VERSION "HNNBNNNYNNNNNNNNNNNNNNNNNNNNNNNNNNNNNNNNNN/4/%%%/4/'%**4NNN///"

NS_ :

BS_:

BU_: AAG BCM1 BCM2 ELV Gateway HDSG IEZS MFG MSBBR SAD SAD2 Schwerpanzer_Zusatz SitzMem_BFS SitzMem_FS SitzMem_HBFS SitzMem_HFS SitzMem_SR3 SpoilerSG TSG_BFS TSG_FS VSG VTS DK_Dummy

BO_ 975 TSG_HBFS_01: 8 TSG_BFS
 SG_ HBFS_Tuer_geoeffnet : 0|1@1+ (1,0) [0|1] ""  BCM2,Gateway,IEZS,MFG,SitzMem_FS,SitzMem_HBFS,SitzMem_SR3,VTS
 SG_ HBFS_verriegelt : 1|1@1+ (1,0) [0|1] ""  BCM2,Gateway,MFG,SitzMem_SR3,VTS
 SG_ HBFS_gesafet : 2|1@1+ (1,0) [0|1] ""  BCM2,Gateway,MFG,TSG_FS,VTS
 SG_ HBFS_Heckrollotaster_betaetigt : 3|1@1+ (1,0) [0|1] ""  BCM2,Gateway
 SG_ HBFS_Tuerschloss_defekt : 4|1@1+ (1,0) [0|1] ""  BCM2,Gateway
 SG_ HBFS_Unlock_Taster : 5|1@1+ (1,0) [0|1] ""  BCM2,Gateway,MFG
 SG_ HBFS_Lock_Taster : 6|1@1+ (1,0) [0|1] ""  BCM2,Gateway,MFG
 SG_ HBFS_Sperrklinke : 7|1@1+ (1,0) [0|1] ""  BCM2,Gateway,MFG
 SG_ HBFS_TAG_betaetigt : 8|1@1+ (1,0) [0|1] ""  Gateway,MFG,VTS
 SG_ HBFS_TIG_betaetigt : 9|1@1+ (1,0) [0|1] ""  BCM1,BCM2,Gateway,MFG
 SG_ HBFS_FH_S_HFS_AutoHoch : 10|1@1+ (1,0) [0|1] ""  Gateway,TSG_FS
 SG_ HBFS_FH_S_HFS_AutoTief : 11|1@1+ (1,0) [0|1] ""  Gateway,TSG_FS
 SG_ HBFS_FH_S_HFS_ManHoch : 12|1@1+ (1,0) [0|1] ""  Gateway,TSG_FS
 SG_ HBFS_FH_S_HFS_ManTief : 13|1@1+ (1,0) [0|1] ""  Gateway,TSG_FS
 SG_ HBFS_Tuer_Status : 14|2@1+ (1,0) [0|3] ""  Gateway,SitzMem_HBFS,TSG_FS
 SG_ HBFS_SAD_Schalter : 16|4@1+ (1,0) [0|15] ""  SAD2,BCM2,Gateway,SAD
 SG_ HBFS_FH_S_ManHoch : 20|1@1+ (1,0) [0|1] ""  BCM2,Gateway,MFG
 SG_ HBFS_FH_S_AutoHoch : 21|1@1+ (1,0) [0|1] ""  BCM2,Gateway,MFG
 SG_ HBFS_FH_S_ManTief : 22|1@1+ (1,0) [0|1] ""  BCM2,Gateway,MFG
 SG_ HBFS_FH_S_AutoTief : 23|1@1+ (1,0) [0|1] ""  BCM2,Gateway,MFG
 SG_ HBFS_FH_Oeffnung : 24|8@1+ (0.5,0) [0|100] "Unit_PerCent"  BCM1,BCM2,Gateway,MFG,SAD,SAD2,VSG,VTS
 SG_ HBFS_FH_Bew_hoch : 32|1@1+ (1,0) [0|1] ""  Gateway,MFG,TSG_FS,VSG
 SG_ HBFS_FH_Bew_tief : 33|1@1+ (1,0) [0|1] ""  Gateway,MFG,TSG_FS
 SG_ HBFS_FH_Fang : 34|1@1+ (1,0) [0|1] ""  Gateway,MFG
 SG_ HBFS_FH_Block : 35|1@1+ (1,0) [0|1] ""  Gateway,MFG
 SG_ HBFS_FH_Thermo : 36|1@1+ (1,0) [0|1] ""  BCM2,Gateway,MFG
 SG_ HBFS_UEKB_aktiviert : 37|1@1+ (1,0) [0|1] ""  BCM2,Gateway,MFG
 SG_ HBFS_Tuerschloss_verrieg_nicht : 38|1@1+ (1,0) [0|1] ""  Gateway
 SG_ HBFS_FH_normiert : 39|1@1+ (1,0) [0|1] ""  BCM2,Gateway,MFG,TSG_FS,VSG,VTS
 SG_ ASW_Warnung_aktiv_HBFS : 40|1@1+ (1,0) [0|1] ""  BCM1,Gateway
 SG_ HBFS_Zuziehhilfe_aktiv : 41|1@1+ (1,0) [0|1] ""  Gateway,MFG
 SG_ HBFS_Seitenrollo_hoch : 42|1@1+ (1,0) [0|1] ""  Gateway,MFG
 SG_ HBFS_Seitenrollo_tief : 43|1@1+ (1,0) [0|1] ""  Gateway,MFG
 SG_ HBFS_Status_KiSi : 44|1@1+ (1,0) [0|1] ""  Gateway,MFG,TSG_FS
 SG_ SSR_HBFS_Pos_Unten : 45|1@1+ (1,0) [0|1] ""  Gateway,TSG_FS
 SG_ HBFS_Oben_Block_erw : 46|1@1+ (1,0) [0|1] ""  Gateway,MFG,TSG_FS
 SG_ HBFS_Unten_Block_erw : 47|1@1+ (1,0) [0|1] ""  Gateway,MFG,TSG_FS
 SG_ MTHBFS_M_Taste : 48|1@1+ (1,0) [0|1] ""  Gateway,SitzMem_FS,SitzMem_HBFS
 SG_ MTHBFS_Pos1 : 49|1@1+ (1,0) [0|1] ""  Gateway,SitzMem_FS
 SG_ MTHBFS_Pos2 : 50|1@1+ (1,0) [0|1] ""  Gateway,SitzMem_FS,SitzMem_HBFS
 SG_ MTHBFS_Pos3 : 51|1@1+ (1,0) [0|1] ""  Gateway,SitzMem_FS,SitzMem_HBFS
 SG_ HBFS_MRollo_Schalter : 52|3@1+ (1,0) [0|7] ""  SAD2,BCM2,Gateway,SAD
 SG_ HBFS_Lock_Taster_inv : 55|1@1+ (1,0) [0|1] ""  BCM2,Gateway
 SG_ HBFS_Status_KiSi_inv : 56|1@1+ (1,0) [0|1] ""  Gateway,TSG_FS

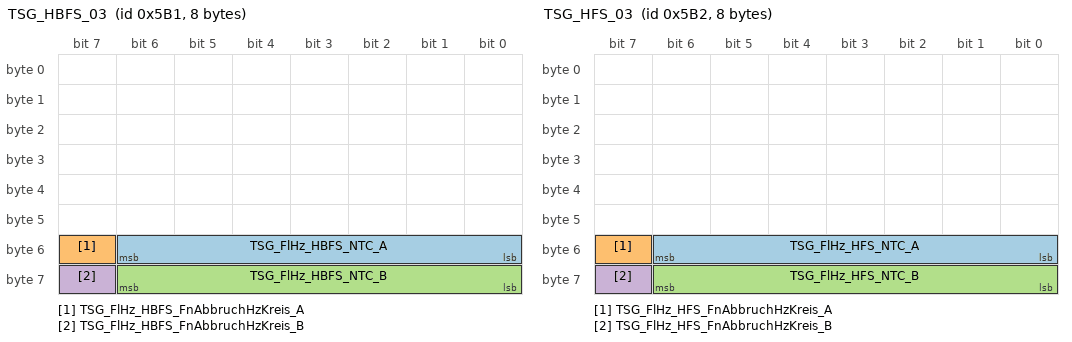
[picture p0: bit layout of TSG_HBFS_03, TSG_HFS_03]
BO_ 1457 TSG_HBFS_03: 8 TSG_BFS
 SG_ TSG_FlHz_HBFS_NTC_A : 48|7@1+ (1,-40) [-40|80] "Unit_DegreCelsi"  BCM1
 SG_ TSG_FlHz_HBFS_FnAbbruchHzKreis_A : 55|1@1+ (1,0) [0|1] ""  BCM1
 SG_ TSG_FlHz_HBFS_NTC_B : 56|7@1+ (1,-40) [-40|80] "Unit_DegreCelsi"  BCM1
 SG_ TSG_FlHz_HBFS_FnAbbruchHzKreis_B : 63|1@1+ (1,0) [0|1] ""  BCM1

BO_ 974 TSG_HFS_01: 8 TSG_FS
 SG_ HFS_Tuer_geoeffnet : 0|1@1+ (1,0) [0|1] ""  BCM2,Gateway,IEZS,MFG,SitzMem_FS,SitzMem_HFS,SitzMem_SR3,VTS
 SG_ HFS_verriegelt : 1|1@1+ (1,0) [0|1] ""  BCM2,Gateway,MFG,SitzMem_SR3,VTS
 SG_ HFS_gesafet : 2|1@1+ (1,0) [0|1] ""  BCM2,Gateway,MFG,TSG_BFS,VTS
 SG_ HFS_Heckrollotaster_betaetigt : 3|1@1+ (1,0) [0|1] ""  BCM2,Gateway
 SG_ HFS_Tuerschloss_defekt : 4|1@1+ (1,0) [0|1] ""  BCM2,Gateway
 SG_ HFS_Unlock_Taster : 5|1@1+ (1,0) [0|1] ""  BCM2,Gateway,MFG
 SG_ HFS_Lock_Taster : 6|1@1+ (1,0) [0|1] ""  BCM2,Gateway,MFG
 SG_ HFS_Sperrklinke : 7|1@1+ (1,0) [0|1] ""  BCM2,Gateway,MFG
 SG_ HFS_TAG_betaetigt : 8|1@1+ (1,0) [0|1] ""  Gateway,MFG,VTS
 SG_ HFS_TIG_betaetigt : 9|1@1+ (1,0) [0|1] ""  BCM1,BCM2,Gateway,MFG
 SG_ HFS_FH_S_HBFS_AutoHoch : 10|1@1+ (1,0) [0|1] ""  Gateway,MFG,TSG_BFS
 SG_ HFS_FH_S_HBFS_AutoTief : 11|1@1+ (1,0) [0|1] ""  Gateway,MFG,TSG_BFS
 SG_ HFS_FH_S_HBFS_ManHoch : 12|1@1+ (1,0) [0|1] ""  Gateway,MFG,TSG_BFS
 SG_ HFS_FH_S_HBFS_ManTief : 13|1@1+ (1,0) [0|1] ""  Gateway,MFG,TSG_BFS
 SG_ HFS_Tuer_Status : 14|2@1+ (1,0) [0|3] ""  Gateway
 SG_ HFS_SAD_Schalter : 16|4@1+ (1,0) [0|15] ""  SAD2,BCM2,Gateway,SAD
 SG_ HFS_FH_S_ManHoch : 20|1@1+ (1,0) [0|1] ""  BCM2,Gateway
 SG_ HFS_FH_S_AutoHoch : 21|1@1+ (1,0) [0|1] ""  BCM2,Gateway
 SG_ HFS_FH_S_ManTief : 22|1@1+ (1,0) [0|1] ""  BCM2,Gateway
 SG_ HFS_FH_S_AutoTief : 23|1@1+ (1,0) [0|1] ""  BCM2,Gateway
 SG_ HFS_FH_Oeffnung : 24|8@1+ (0.5,0) [0|100] "Unit_PerCent"  BCM1,BCM2,Gateway,MFG,SAD,SAD2,VSG,VTS
 SG_ HFS_FH_Bew_hoch : 32|1@1+ (1,0) [0|1] ""  Gateway,MFG,TSG_BFS,VSG
 SG_ HFS_FH_Bew_tief : 33|1@1+ (1,0) [0|1] ""  Gateway,MFG,TSG_BFS
 SG_ HFS_FH_Fang : 34|1@1+ (1,0) [0|1] ""  Gateway,MFG
 SG_ HFS_FH_Block : 35|1@1+ (1,0) [0|1] ""  Gateway,MFG
 SG_ HFS_FH_Thermo : 36|1@1+ (1,0) [0|1] ""  BCM2,Gateway,MFG
 SG_ HFS_UEKB_aktiviert : 37|1@1+ (1,0) [0|1] ""  BCM2,Gateway,MFG
 SG_ HFS_Tuerschloss_verrieg_nicht : 38|1@1+ (1,0) [0|1] ""  Gateway
 SG_ HFS_FH_normiert : 39|1@1+ (1,0) [0|1] ""  BCM2,Gateway,MFG,VSG,VTS
 SG_ ASW_Warnung_aktiv_HFS : 40|1@1+ (1,0) [0|1] ""  BCM1,Gateway
 SG_ HFS_Zuziehhilfe_aktiv : 41|1@1+ (1,0) [0|1] ""  Gateway,MFG
 SG_ HFS_Seitenrollo_hoch : 42|1@1+ (1,0) [0|1] ""  Gateway,MFG
 SG_ HFS_Seitenrollo_tief : 43|1@1+ (1,0) [0|1] ""  Gateway,MFG
 SG_ HFS_Status_KiSi : 44|1@1+ (1,0) [0|1] ""  Gateway,MFG,TSG_BFS
 SG_ SSR_HFS_Pos_Unten : 45|1@1+ (1,0) [0|1] ""  Gateway,TSG_BFS
 SG_ HFS_Oben_Block_erw : 46|1@1+ (1,0) [0|1] ""  Gateway,MFG,TSG_BFS
 SG_ HFS_Unten_Block_erw : 47|1@1+ (1,0) [0|1] ""  Gateway,MFG,TSG_BFS
 SG_ MTHFS_M_Taste : 48|1@1+ (1,0) [0|1] ""  Gateway,SitzMem_FS,SitzMem_HFS
 SG_ MTHFS_Pos1 : 49|1@1+ (1,0) [0|1] ""  Gateway,SitzMem_FS,SitzMem_HFS
 SG_ MTHFS_Pos2 : 50|1@1+ (1,0) [0|1] ""  Gateway,SitzMem_FS,SitzMem_HFS
 SG_ MTHFS_Pos3 : 51|1@1+ (1,0) [0|1] ""  Gateway,SitzMem_FS,SitzMem_HFS
 SG_ HFS_MRollo_Schalter : 52|3@1+ (1,0) [0|7] ""  SAD2,BCM2,Gateway,SAD
 SG_ HFS_Lock_Taster_inv : 55|1@1+ (1,0) [0|1] ""  BCM2,Gateway

BO_ 1458 TSG_HFS_03: 8 TSG_FS
 SG_ TSG_FlHz_HFS_NTC_A : 48|7@1+ (1,-40) [-40|80] "Unit_DegreCelsi"  BCM1
 SG_ TSG_FlHz_HFS_FnAbbruchHzKreis_A : 55|1@1+ (1,0) [0|1] ""  BCM1
 SG_ TSG_FlHz_HFS_NTC_B : 56|7@1+ (1,-40) [-40|80] "Unit_DegreCelsi"  BCM1
 SG_ TSG_FlHz_HFS_FnAbbruchHzKreis_B : 63|1@1+ (1,0) [0|1] ""  BCM1

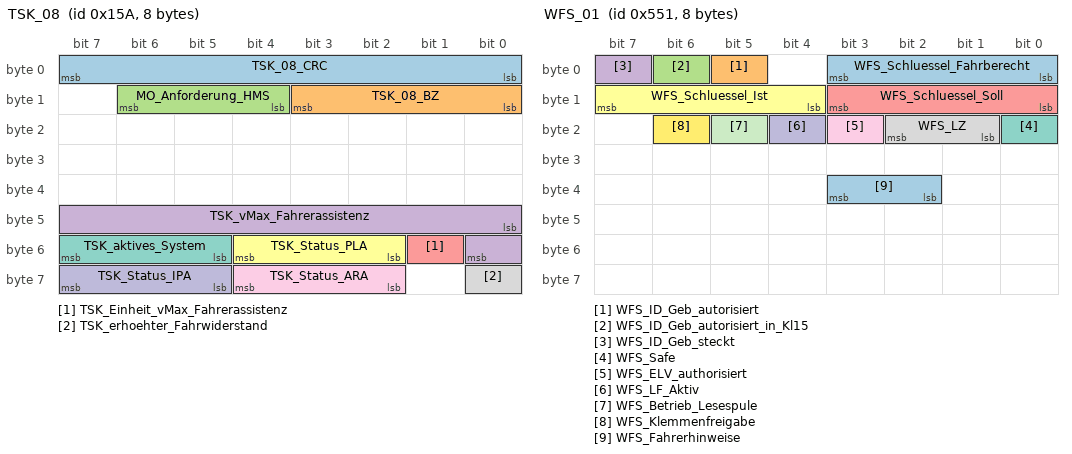
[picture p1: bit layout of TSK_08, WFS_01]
BO_ 346 TSK_08: 8 Gateway
 SG_ TSK_08_CRC : 0|8@1+ (1,0) [0|255] "" Vector__XXX
 SG_ TSK_08_BZ : 8|4@1+ (1,0) [0|15] "" Vector__XXX
 SG_ MO_Anforderung_HMS : 12|3@1+ (1,0) [0|7] "" Vector__XXX
 SG_ TSK_vMax_Fahrerassistenz : 40|9@1+ (1,0) [0|510] "" Vector__XXX
 SG_ TSK_Einheit_vMax_Fahrerassistenz : 49|1@1+ (1,0) [0|1] "" Vector__XXX
 SG_ TSK_Status_PLA : 50|3@1+ (1,0) [0|7] ""  BCM1
 SG_ TSK_aktives_System : 53|3@1+ (1,0) [0|7] ""  BCM1
 SG_ TSK_erhoehter_Fahrwiderstand : 56|1@1+ (1,0) [0|1] "" Vector__XXX
 SG_ TSK_Status_ARA : 58|3@1+ (1,0) [0|7] ""  BCM1
 SG_ TSK_Status_IPA : 61|3@1+ (1,0) [0|7] "" Vector__XXX

BO_ 995 Verdeck_01: 8 VSG
 SG_ VS_VD_zu_ver : 16|1@1+ (1,0) [0|1] ""  BCM1,BCM2,Gateway,SpoilerSG,TSG_BFS,TSG_FS
 SG_ VS_VD_entriegelt : 17|1@1+ (1,0) [0|1] ""  BCM2,Gateway,TSG_BFS,TSG_FS
 SG_ VS_VD_offen_ver : 18|1@1+ (1,0) [0|1] ""  BCM1,BCM2,Gateway,TSG_BFS,TSG_FS
 SG_ VS_VD_Zwischenposition : 19|1@1+ (1,0) [0|1] ""  BCM2,Gateway,TSG_BFS,TSG_FS
 SG_ VS_VD_Bew_auf : 20|1@1+ (1,0) [0|1] ""  Gateway,TSG_BFS,TSG_FS
 SG_ VS_VD_Bew_zu : 21|1@1+ (1,0) [0|1] ""  Gateway,TSG_BFS,TSG_FS
 SG_ VS_Verdeck_Anf : 22|1@1+ (1,0) [0|1] ""  AAG,BCM2,Gateway
 SG_ VS_Hardtop : 23|1@1+ (1,0) [0|1] ""  BCM1,Gateway,TSG_BFS,TSG_FS
 SG_ VS_VD_Fehler : 24|1@1+ (1,0) [0|1] ""  Gateway
 SG_ VS_Lampe_Blk : 25|1@1+ (1,0) [0|1] ""  Gateway
 SG_ VS_Buzzer : 26|1@1+ (1,0) [0|1] ""  Gateway
 SG_ VS_HD_sperren : 27|1@1+ (1,0) [0|1] ""  BCM2,Gateway
 SG_ VS_HHS_enable : 28|1@1+ (1,0) [0|1] ""  BCM2,Gateway
 SG_ ZFH_FS_AutoHoch : 32|1@1+ (1,0) [0|1] ""  Gateway,TSG_FS
 SG_ ZFH_FS_AutoTief : 33|1@1+ (1,0) [0|1] ""  Gateway,TSG_FS
 SG_ ZFH_FS_ManHoch : 34|1@1+ (1,0) [0|1] ""  Gateway,TSG_FS
 SG_ ZFH_FS_ManTief : 35|1@1+ (1,0) [0|1] ""  Gateway,TSG_FS
 SG_ ZFH_BFS_AutoHoch : 36|1@1+ (1,0) [0|1] ""  Gateway,TSG_BFS
 SG_ ZFH_BFS_AutoTief : 37|1@1+ (1,0) [0|1] ""  Gateway,TSG_BFS
 SG_ ZFH_BFS_ManHoch : 38|1@1+ (1,0) [0|1] ""  Gateway,TSG_BFS
 SG_ ZFH_BFS_ManTief : 39|1@1+ (1,0) [0|1] ""  Gateway,TSG_BFS
 SG_ ZFH_HFS_AutoHoch : 40|1@1+ (1,0) [0|1] ""  Gateway,TSG_FS
 SG_ ZFH_HFS_AutoTief : 41|1@1+ (1,0) [0|1] ""  Gateway,TSG_FS
 SG_ ZFH_HFS_ManHoch : 42|1@1+ (1,0) [0|1] ""  Gateway,TSG_FS
 SG_ ZFH_HFS_ManTief : 43|1@1+ (1,0) [0|1] ""  Gateway,TSG_FS
 SG_ ZFH_HBFS_AutoHoch : 44|1@1+ (1,0) [0|1] ""  Gateway,TSG_BFS
 SG_ ZFH_HBFS_AutoTief : 45|1@1+ (1,0) [0|1] ""  Gateway,TSG_BFS
 SG_ ZFH_HBFS_ManHoch : 46|1@1+ (1,0) [0|1] ""  Gateway,TSG_BFS
 SG_ ZFH_HBFS_ManTief : 47|1@1+ (1,0) [0|1] ""  Gateway,TSG_BFS
 SG_ VS_FH_FT_Langhub : 49|1@1+ (1,0) [0|1] ""  Gateway,TSG_FS
 SG_ VS_FH_BT_Langhub : 51|1@1+ (1,0) [0|1] ""  Gateway,TSG_BFS
 SG_ VS_FH_HFS_Langhub : 53|1@1+ (1,0) [0|1] ""  Gateway,TSG_FS
 SG_ VS_Heckschloss_auf : 54|1@1+ (1,0) [0|1] ""  Gateway
 SG_ VS_FH_HBFS_Langhub : 55|1@1+ (1,0) [0|1] ""  Gateway,TSG_BFS
 SG_ VSG_Meldungen : 56|6@1+ (1,0) [0|63] ""  BCM1,Gateway

BO_ 1716 VIN_01: 8 BCM2
 SG_ VIN_01_MUX M : 0|2@1+ (1,0) [0|3] ""  BCM1,Gateway,HDSG,MFG,SAD,SAD2,TSG_BFS,TSG_FS,VSG,VTS
 SG_ KS_Geheimnis_1 m0 : 8|8@1+ (1,0) [0|255] ""  Gateway
 SG_ VIN_4 m1 : 8|8@1+ (1,0) [0|255] ""  BCM1,Gateway,HDSG,MFG,SAD,SAD2,TSG_BFS,TSG_FS,VSG,VTS
 SG_ VIN_11 m2 : 8|8@1+ (1,0) [0|255] ""  BCM1,Gateway,HDSG,MFG,SAD,SAD2,TSG_BFS,TSG_FS,VSG,VTS
 SG_ KS_Geheimnis_2 m0 : 16|8@1+ (1,0) [0|255] ""  Gateway
 SG_ VIN_5 m1 : 16|8@1+ (1,0) [0|255] ""  BCM1,Gateway,HDSG,MFG,SAD,SAD2,TSG_BFS,TSG_FS,VSG,VTS
 SG_ VIN_12 m2 : 16|8@1+ (1,0) [0|255] ""  BCM1,Gateway,HDSG,MFG,SAD,SAD2,TSG_BFS,TSG_FS,VSG,VTS
 SG_ KS_Geheimnis_3 m0 : 24|8@1+ (1,0) [0|255] ""  Gateway
 SG_ VIN_6 m1 : 24|8@1+ (1,0) [0|255] ""  BCM1,Gateway,HDSG,MFG,SAD,SAD2,TSG_BFS,TSG_FS,VSG,VTS
 SG_ VIN_13 m2 : 24|8@1+ (1,0) [0|255] ""  BCM1,Gateway,HDSG,MFG,SAD,SAD2,TSG_BFS,TSG_FS,VSG,VTS
 SG_ KS_Geheimnis_4 m0 : 32|8@1+ (1,0) [0|255] ""  Gateway
 SG_ VIN_7 m1 : 32|8@1+ (1,0) [0|255] ""  BCM1,Gateway,HDSG,MFG,SAD,SAD2,TSG_BFS,TSG_FS,VSG,VTS
 SG_ VIN_14 m2 : 32|8@1+ (1,0) [0|255] ""  BCM1,Gateway,HDSG,MFG,SAD,SAD2,TSG_BFS,TSG_FS,VSG,VTS
 SG_ VIN_1 m0 : 40|8@1+ (1,0) [0|255] ""  BCM1,Gateway,HDSG,MFG,SAD,SAD2,TSG_BFS,TSG_FS,VSG,VTS
 SG_ VIN_8 m1 : 40|8@1+ (1,0) [0|255] ""  BCM1,Gateway,HDSG,MFG,SAD,SAD2,TSG_BFS,TSG_FS,VSG,VTS
 SG_ VIN_15 m2 : 40|8@1+ (1,0) [0|255] ""  BCM1,Gateway,HDSG,MFG,SAD,SAD2,TSG_BFS,TSG_FS,VSG,VTS
 SG_ VIN_2 m0 : 48|8@1+ (1,0) [0|255] ""  BCM1,Gateway,HDSG,MFG,SAD,SAD2,TSG_BFS,TSG_FS,VSG,VTS
 SG_ VIN_9 m1 : 48|8@1+ (1,0) [0|255] ""  BCM1,Gateway,HDSG,MFG,SAD,SAD2,TSG_BFS,TSG_FS,VSG,VTS
 SG_ VIN_16 m2 : 48|8@1+ (1,0) [0|255] ""  BCM1,Gateway,HDSG,MFG,SAD,SAD2,TSG_BFS,TSG_FS,VSG,VTS
 SG_ VIN_3 m0 : 56|8@1+ (1,0) [0|255] ""  BCM1,Gateway,HDSG,MFG,SAD,SAD2,TSG_BFS,TSG_FS,VSG,VTS
 SG_ VIN_10 m1 : 56|8@1+ (1,0) [0|255] ""  BCM1,Gateway,HDSG,MFG,SAD,SAD2,TSG_BFS,TSG_FS,VSG,VTS
 SG_ VIN_17 m2 : 56|8@1+ (1,0) [0|255] ""  BCM1,Gateway,HDSG,MFG,SAD,SAD2,TSG_BFS,TSG_FS,VSG,VTS

BO_ 1361 WFS_01: 8 BCM2
 SG_ WFS_Schluessel_Fahrberecht : 0|4@1+ (1,0) [0|15] ""  Gateway,SitzMem_FS
 SG_ WFS_ID_Geb_autorisiert : 5|1@1+ (1,0) [0|1] ""  BCM1,Gateway
 SG_ WFS_ID_Geb_autorisiert_in_Kl15 : 6|1@1+ (1,0) [0|1] ""  Gateway
 SG_ WFS_ID_Geb_steckt : 7|1@1+ (1,0) [0|1] ""  Gateway
 SG_ WFS_Schluessel_Soll : 8|4@1+ (1,0) [0|15] ""  Gateway
 SG_ WFS_Schluessel_Ist : 12|4@1+ (1,0) [0|15] ""  Gateway
 SG_ WFS_Safe : 16|1@1+ (1,0) [0|1] ""  Gateway
 SG_ WFS_LZ : 17|2@1+ (1,0) [0|3] ""  Gateway
 SG_ WFS_ELV_authorisiert : 19|1@1+ (1,0) [0|1] ""  Gateway
 SG_ WFS_LF_Aktiv : 20|1@1+ (1,0) [0|1] ""  Gateway
 SG_ WFS_Betrieb_Lesespule : 21|1@1+ (1,0) [0|1] ""  Gateway
 SG_ WFS_Klemmenfreigabe : 22|1@1+ (1,0) [0|1] ""  Gateway
 SG_ WFS_Fahrerhinweise : 34|2@1+ (1,0) [0|3] ""  Gateway

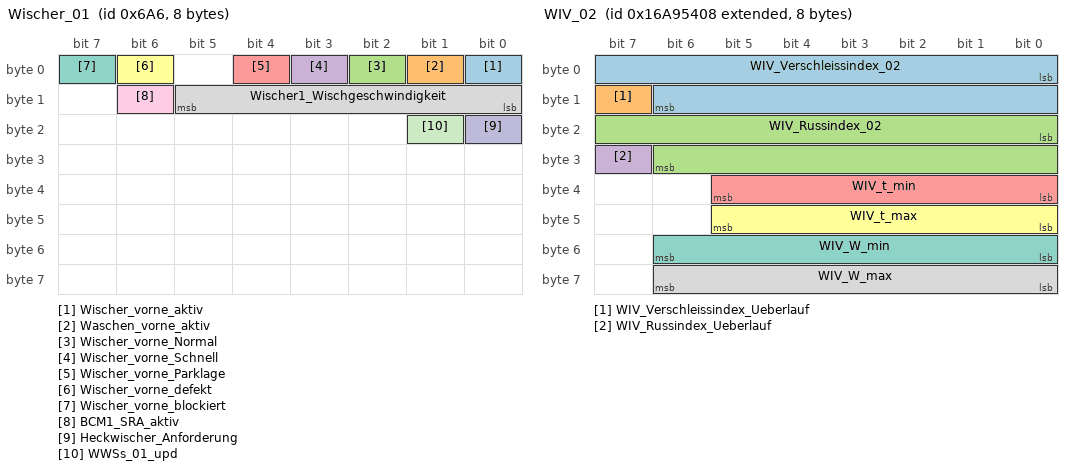
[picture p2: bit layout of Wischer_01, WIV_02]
BO_ 1702 Wischer_01: 8 BCM1
 SG_ Wischer_vorne_aktiv : 0|1@1+ (1,0) [0|1] ""  Gateway,TSG_BFS,TSG_FS
 SG_ Waschen_vorne_aktiv : 1|1@1+ (1,0) [0|1] ""  Gateway
 SG_ Wischer_vorne_Normal : 2|1@1+ (1,0) [0|1] ""  Gateway
 SG_ Wischer_vorne_Schnell : 3|1@1+ (1,0) [0|1] ""  Gateway
 SG_ Wischer_vorne_Parklage : 4|1@1+ (1,0) [0|1] ""  Gateway
 SG_ Wischer_vorne_defekt : 6|1@1+ (1,0) [0|1] ""  Gateway
 SG_ Wischer_vorne_blockiert : 7|1@1+ (1,0) [0|1] ""  Gateway
 SG_ Wischer1_Wischgeschwindigkeit : 8|6@1+ (1,9) [10|70] "Unit_MinutInver"  Gateway
 SG_ BCM1_SRA_aktiv : 14|1@1+ (1,0) [0|1] ""  Gateway
 SG_ Heckwischer_Anforderung : 16|1@1+ (1,0) [0|1] ""  BCM2,Gateway
 SG_ WWSs_01_upd : 17|1@1+ (1,0) [0|1] ""  Gateway,TSG_BFS,TSG_FS

BO_ 2527679496 WIV_02: 8 Gateway
 SG_ WIV_Verschleissindex_02 : 0|15@1+ (0.001,0) [0|32.766] "" Vector__XXX
 SG_ WIV_Verschleissindex_Ueberlauf : 15|1@1+ (1,0) [0|1] "" Vector__XXX
 SG_ WIV_Russindex_02 : 16|15@1+ (0.001,0) [0|32.766] "" Vector__XXX
 SG_ WIV_Russindex_Ueberlauf : 31|1@1+ (1,0) [0|1] "" Vector__XXX
 SG_ WIV_t_min : 32|6@1+ (1,0) [0|63] "Unit_Month"  VTS
 SG_ WIV_t_max : 40|6@1+ (1,0) [0|63] "Unit_Month"  VTS
 SG_ WIV_W_min : 48|7@1+ (1000,0) [0|127000] "Unit_KiloMeter"  VTS
 SG_ WIV_W_max : 56|7@1+ (1000,0) [0|127000] "Unit_KiloMeter"  VTS

BO_ 2617130496 XCP_AAG_CRO_01: 8 Vector__XXX
 SG_ XCP_AAG_CRO_01_Data : 0|64@1+ (1,0) [0|1] ""  AAG

BO_ 2617130497 XCP_AAG_DTO_01: 8 AAG
 SG_ XCP_AAG_DTO_01_Data : 0|64@1+ (1,0) [0|1] "" Vector__XXX

BO_ 2617013760 XCP_BCM1_CRO_01: 8 Vector__XXX
 SG_ XCP_BCM1_CRO_01_Data : 0|64@1+ (1,0) [0|1] ""  BCM1

BO_ 2617013761 XCP_BCM1_DTO_01: 8 BCM1
 SG_ XCP_BCM1_DTO_01_Data : 0|64@1+ (1,0) [0|1] "" Vector__XXX

BO_ 2617007872 XCP_BCM2_CRO_01: 8 Vector__XXX
 SG_ XCP_BCM2_CRO_01_Data : 0|64@1+ (1,0) [0|1] ""  BCM2

BO_ 2617007873 XCP_BCM2_DTO_01: 8 BCM2
 SG_ XCP_BCM2_DTO_01_Data : 0|64@1+ (1,0) [0|1] "" Vector__XXX

BO_ 2617085440 XCP_ELV_CRO_01: 8 Vector__XXX
 SG_ XCP_ELV_CRO_01_Data : 0|64@1+ (1,0) [0|1] ""  ELV

BO_ 2617085441 XCP_ELV_DTO_01: 8 ELV
 SG_ XCP_ELV_DTO_01_Data : 0|64@1+ (1,0) [0|1] "" Vector__XXX

BO_ 2617056768 XCP_HDSG_CRO_01: 8 Vector__XXX
 SG_ XCP_HDSG_CRO_01_Data : 0|64@1+ (1,0) [0|1] ""  HDSG

BO_ 2617056769 XCP_HDSG_DTO_01: 8 HDSG
 SG_ XCP_HDSG_DTO_01_Data : 0|64@1+ (1,0) [0|1] "" Vector__XXX

BO_ 2617075200 XCP_MFG_CRO_01: 8 Vector__XXX
 SG_ XCP_MFG_CRO_01_Data : 0|64@1+ (1,0) [0|1] ""  MFG

BO_ 2617075201 XCP_MFG_DTO_01: 8 MFG
 SG_ XCP_MFG_DTO_01_Data : 0|64@1+ (1,0) [0|1] "" Vector__XXX

BO_ 2617050880 XCP_SAD2_CRO_01: 8 Vector__XXX
 SG_ XCP_SAD2_CRO_01_Data : 0|64@1+ (1,0) [0|1] ""  SAD2

BO_ 2617050881 XCP_SAD2_DTO_01: 8 SAD2
 SG_ XCP_SAD2_DTO_01_Data : 0|64@1+ (1,0) [0|1] "" Vector__XXX

BO_ 2616993536 XCP_SAD_CRO_01: 8 Vector__XXX
 SG_ XCP_SAD_CRO_01_Data : 0|64@1+ (1,0) [0|1] ""  SAD

BO_ 2616993537 XCP_SAD_DTO_01: 8 SAD
 SG_ XCP_SAD_DTO_01_Data : 0|64@1+ (1,0) [0|1] "" Vector__XXX

BO_ 2617040640 XCP_SBBR_CRO_01: 8 Vector__XXX
 SG_ XCP_MSBBR_CRO_01_Data : 0|64@1+ (1,0) [0|1] ""  MSBBR

BO_ 2617040641 XCP_SBBR_DTO_01: 8 MSBBR
 SG_ XCP_MSBBR_DTO_01_Data : 0|64@1+ (1,0) [0|1] "" Vector__XXX

BO_ 2617142784 XCP_SitzMem_BFS_CRO_01: 8 Vector__XXX
 SG_ XCP_SitzMem_BFS_CRO_01_Data : 0|64@1+ (1,0) [0|1] ""  SitzMem_BFS

BO_ 2617142785 XCP_SitzMem_BFS_DTO_01: 8 SitzMem_BFS
 SG_ XCP_SitzMem_BFS_DTO_01_Data : 0|64@1+ (1,0) [0|1] "" Vector__XXX

BO_ 2617140736 XCP_SitzMem_FS_CRO_01: 8 Vector__XXX
 SG_ XCP_SitzMem_FS_CRO_01_Data : 0|64@1+ (1,0) [0|1] ""  SitzMem_FS

BO_ 2617140737 XCP_SitzMem_FS_DTO_01: 8 SitzMem_FS
 SG_ XCP_SitzMem_FS_DTO_01_Data : 0|64@1+ (1,0) [0|1] "" Vector__XXX

BO_ 2617001728 XCP_SitzMem_HBFS_CRO_01: 8 Vector__XXX
 SG_ XCP_SitzMem_HBFS_CRO_01_Data : 0|64@1+ (1,0) [0|1] ""  SitzMem_HBFS

BO_ 2617001729 XCP_SitzMem_HBFS_DTO_01: 8 SitzMem_HBFS
 SG_ XCP_SitzMem_HBFS_DTO_01_Data : 0|64@1+ (1,0) [0|1] "" Vector__XXX

BO_ 2616999680 XCP_SitzMem_HFS_CRO_01: 8 Vector__XXX
 SG_ XCP_SitzMem_HFS_CRO_01_Data : 0|64@1+ (1,0) [0|1] ""  SitzMem_HFS

BO_ 2616999681 XCP_SitzMem_HFS_DTO_01: 8 SitzMem_HFS
 SG_ XCP_SitzMem_HFS_DTO_01_Data : 0|64@1+ (1,0) [0|1] "" Vector__XXX

BO_ 2617028352 XCP_SitzMem_SR3_CRO_01: 8 Vector__XXX
 SG_ XCP_SitzMem_SR3_CRO_01_Data : 0|64@1+ (1,0) [0|1] ""  SitzMem_SR3

BO_ 2617028353 XCP_SitzMem_SR3_DTO_01: 8 SitzMem_SR3
 SG_ XCP_SitzMem_SR3_DTO_01_Data : 0|64@1+ (1,0) [0|1] "" Vector__XXX

BO_ 2617058816 XCP_SpoilerSG_CRO_01: 8 Vector__XXX
 SG_ XCP_SpoilerSG_CRO_01_Data : 0|64@1+ (1,0) [0|1] ""  SpoilerSG

BO_ 2617058817 XCP_SpoilerSG_DTO_01: 8 SpoilerSG
 SG_ XCP_SpoilerSG_DTO_01_Data : 0|64@1+ (1,0) [0|1] "" Vector__XXX

BO_ 2617073152 XCP_STS_CRO_01: 8 Vector__XXX
 SG_ XCP_STS_CRO_01_Data : 0|64@1+ (1,0) [0|1] ""  VTS

BO_ 2617073153 XCP_STS_DTO_01: 8 VTS
 SG_ XCP_STS_DTO_01_Data : 0|64@1+ (1,0) [0|1] "" Vector__XXX

BO_ 2617138688 XCP_TSG_BT_CRO_01: 8 Vector__XXX
 SG_ XCP_TSG_BT_CRO_01_Data : 0|64@1+ (1,0) [0|1.84467440737096E+019] ""  TSG_BFS

BO_ 2617138689 XCP_TSG_BT_DTO_01: 8 TSG_BFS
 SG_ XCP_TSG_BT_DTO_01_Data : 0|64@1+ (1,0) [0|1.84467440737096E+019] "" Vector__XXX

BO_ 2617136640 XCP_TSG_FT_CRO_01: 8 Vector__XXX
 SG_ XCP_TSG_FT_CRO_01_Data : 0|64@1+ (1,0) [0|1.84467440737096E+019] ""  TSG_FS

BO_ 2617136641 XCP_TSG_FT_DTO_01: 8 TSG_FS
 SG_ XCP_TSG_FT_DTO_01_Data : 0|64@1+ (1,0) [0|1.84467440737096E+019] "" Vector__XXX

BO_ 2566802688 XCP_TSG_HBFS_CRO_01: 8 Vector__XXX
 SG_ XCP_TSG_HBFS_CRO_01_Data : 0|64@1+ (1,0) [0|1.84467440737096E+019] ""  TSG_BFS

BO_ 2566802689 XCP_TSG_HBFS_DTO_01: 8 TSG_BFS
 SG_ XCP_TSG_HBFS_DTO_01_Data : 0|64@1+ (1,0) [0|1.84467440737096E+019] "" Vector__XXX

BO_ 2566802432 XCP_TSG_HFS_CRO_01: 8 Vector__XXX
 SG_ XCP_TSG_HFS_CRO_01_Data : 0|64@1+ (1,0) [0|1.84467440737096E+019] ""  TSG_FS

BO_ 2566802433 XCP_TSG_HFS_DTO_01: 8 TSG_FS
 SG_ XCP_TSG_HFS_DTO_01_Data : 0|64@1+ (1,0) [0|1.84467440737096E+019] "" Vector__XXX

BO_ 2617077248 XCP_VSG_CRO_01: 8 Vector__XXX
 SG_ XCP_VSG_CRO_01_Data : 0|64@1+ (1,0) [0|1] ""  VSG

BO_ 2617077249 XCP_VSG_DTO_01: 8 VSG
 SG_ XCP_VSG_DTO_01_Data : 0|64@1+ (1,0) [0|1] "" Vector__XXX

BO_ 389 ZFH_01: 8 TSG_FS
 SG_ ZFH_FS_ManHoch : 0|1@1+ (1,0) [0|1] ""  MFG
 SG_ ZFH_FS_AutoHoch : 1|1@1+ (1,0) [0|1] ""  MFG
 SG_ ZFH_FS_ManTief : 2|1@1+ (1,0) [0|1] ""  MFG
 SG_ ZFH_FS_AutoTief : 3|1@1+ (1,0) [0|1] ""  MFG
 SG_ ZFH_BFS_ManHoch : 4|1@1+ (1,0) [0|1] ""  MFG,TSG_BFS
 SG_ ZFH_BFS_AutoHoch : 5|1@1+ (1,0) [0|1] ""  MFG,TSG_BFS
 SG_ ZFH_BFS_ManTief : 6|1@1+ (1,0) [0|1] ""  MFG,TSG_BFS
 SG_ ZFH_BFS_AutoTief : 7|1@1+ (1,0) [0|1] ""  MFG,TSG_BFS
 SG_ ZFH_HFS_ManHoch : 8|1@1+ (1,0) [0|1] ""  MFG
 SG_ ZFH_HFS_AutoHoch : 9|1@1+ (1,0) [0|1] ""  MFG
 SG_ ZFH_HFS_ManTief : 10|1@1+ (1,0) [0|1] ""  MFG
 SG_ ZFH_HFS_AutoTief : 11|1@1+ (1,0) [0|1] ""  MFG
 SG_ ZFH_HBFS_ManHoch : 12|1@1+ (1,0) [0|1] ""  MFG,TSG_BFS
 SG_ ZFH_HBFS_AutoHoch : 13|1@1+ (1,0) [0|1] ""  MFG,TSG_BFS
 SG_ ZFH_HBFS_ManTief : 14|1@1+ (1,0) [0|1] ""  MFG,TSG_BFS
 SG_ ZFH_HBFS_AutoTief : 15|1@1+ (1,0) [0|1] ""  MFG,TSG_BFS
 SG_ ZFH_zentral_zu : 28|1@1+ (1,0) [0|1] ""  TSG_BFS
 SG_ ZFH_zentral_auf : 29|1@1+ (1,0) [0|1] ""  TSG_BFS
 SG_ Krypt_Signatur : 48|11@1+ (1,0) [0|2047] ""  TSG_BFS
 SG_ Krypt_Schluesselschalter_auf : 59|1@1+ (1,0) [0|1] ""  BCM2,TSG_BFS
 SG_ Krypt_Schluesselschalter_zu : 60|1@1+ (1,0) [0|1] ""  BCM2,TSG_BFS

BO_ 392 ZFH_BFS_01: 8 TSG_BFS
 SG_ BT_FH_BT_ManHoch : 0|1@1+ (1,0) [0|1] ""  MFG
 SG_ BT_FH_BT_AutoHoch : 1|1@1+ (1,0) [0|1] ""  MFG
 SG_ BT_FH_BT_ManTief : 2|1@1+ (1,0) [0|1] ""  MFG
 SG_ BT_FH_BT_AutoTief : 3|1@1+ (1,0) [0|1] ""  MFG
 SG_ BT_FH_FT_ManHoch : 4|1@1+ (1,0) [0|1] ""  MFG,TSG_FS
 SG_ BT_FH_FT_AutoHoch : 5|1@1+ (1,0) [0|1] ""  MFG,TSG_FS
 SG_ BT_FH_FT_ManTief : 6|1@1+ (1,0) [0|1] ""  MFG,TSG_FS
 SG_ BT_FH_FT_AutoTief : 7|1@1+ (1,0) [0|1] ""  MFG,TSG_FS
 SG_ BT_FH_HFS_ManHoch : 8|1@1+ (1,0) [0|1] ""  MFG,TSG_FS
 SG_ BT_FH_HFS_AutoHoch : 9|1@1+ (1,0) [0|1] ""  MFG,TSG_FS
 SG_ BT_FH_HFS_ManTief : 10|1@1+ (1,0) [0|1] ""  MFG,TSG_FS
 SG_ BT_FH_HFS_AutoTief : 11|1@1+ (1,0) [0|1] ""  MFG,TSG_FS
 SG_ BT_FH_HBFS_ManHoch : 12|1@1+ (1,0) [0|1] ""  MFG
 SG_ BT_FH_HBFS_AutoHoch : 13|1@1+ (1,0) [0|1] ""  MFG
 SG_ BT_FH_HBFS_ManTief : 14|1@1+ (1,0) [0|1] ""  MFG
 SG_ BT_FH_HBFS_AutoTief : 15|1@1+ (1,0) [0|1] ""  MFG
 SG_ BT_SP_hoch : 16|1@1+ (1,0) [0|1] ""  MFG
 SG_ BT_SP_tief : 17|1@1+ (1,0) [0|1] ""  MFG
 SG_ BT_SP_links : 18|1@1+ (1,0) [0|1] ""  MFG
 SG_ BT_SP_rechts : 19|1@1+ (1,0) [0|1] ""  MFG
 SG_ BT_SP_Garagenstellung : 20|1@1+ (1,0) [0|1] ""  MFG
 SG_ BT_SP_Fahrstellung : 21|1@1+ (1,0) [0|1] ""  MFG,VTS
 SG_ BT_FH_zentral_zu : 28|1@1+ (1,0) [0|1] ""  MFG,TSG_FS
 SG_ BT_FH_zentral_auf : 29|1@1+ (1,0) [0|1] ""  MFG,TSG_FS

BO_ 388 ZV_01: 8 BCM2
 SG_ ZV_01_CRC : 0|8@1+ (1,0) [0|255] ""  BCM1,Gateway,TSG_FS
 SG_ ZV_01_BZ : 8|4@1+ (1,0) [0|15] ""  BCM1,Gateway,TSG_FS
 SG_ ZV_FT_verriegeln : 12|1@1+ (1,0) [0|1] ""  BCM1,Gateway,SitzMem_BFS,SitzMem_FS,TSG_BFS,TSG_FS
 SG_ ZV_FT_entriegeln : 13|1@1+ (1,0) [0|1] ""  BCM1,Gateway,TSG_BFS,TSG_FS
 SG_ ZV_BT_verriegeln : 14|1@1+ (1,0) [0|1] ""  Gateway,TSG_BFS
 SG_ ZV_BT_entriegeln : 15|1@1+ (1,0) [0|1] ""  Gateway,TSG_BFS
 SG_ ZV_HFS_verriegeln : 16|1@1+ (1,0) [0|1] ""  Gateway,TSG_FS
 SG_ ZV_HFS_entriegeln : 17|1@1+ (1,0) [0|1] ""  Gateway,TSG_FS
 SG_ ZV_HBFS_verriegeln : 18|1@1+ (1,0) [0|1] ""  Gateway,TSG_BFS
 SG_ ZV_HBFS_entriegeln : 19|1@1+ (1,0) [0|1] ""  Gateway,TSG_BFS
 SG_ ZV_zentral_safen : 20|1@1+ (1,0) [0|1] ""  Gateway,TSG_BFS,TSG_FS
 SG_ ZV_zentral_entsafen : 21|1@1+ (1,0) [0|1] ""  Gateway,TSG_BFS,TSG_FS
 SG_ ZV_Spg_Anklappen : 22|1@1+ (1,0) [0|1] ""  Gateway,TSG_BFS,TSG_FS
 SG_ ZV_Softtouch_betaetigt : 23|1@1+ (1,0) [0|1] ""  AAG,BCM1,Gateway,HDSG
 SG_ ZV_LED_Steuerung : 24|1@1+ (1,0) [0|1] ""  Gateway,TSG_FS
 SG_ ZV_LED_Uebernahme : 25|1@1+ (1,0) [0|1] ""  Gateway,TSG_FS
 SG_ ZV_auf_FT : 26|1@1+ (1,0) [0|1] ""  BCM1,Gateway,TSG_FS
 SG_ ZV_zu_FT : 27|1@1+ (1,0) [0|1] ""  Gateway,TSG_FS
 SG_ ZV_auf_BT : 28|1@1+ (1,0) [0|1] ""  BCM1,Gateway
 SG_ ZV_zu_BT : 29|1@1+ (1,0) [0|1] ""  Gateway
 SG_ ZV_auf_Kessy : 30|1@1+ (1,0) [0|1] ""  BCM1,Gateway,TSG_BFS,TSG_FS
 SG_ ZV_zu_Kessy : 31|1@1+ (1,0) [0|1] ""  BCM1,Gateway,TSG_BFS,TSG_FS
 SG_ ZV_auf_Funk : 32|1@1+ (1,0) [0|1] ""  BCM1,Gateway,SitzMem_BFS,SitzMem_FS,TSG_BFS,TSG_FS
 SG_ ZV_zu_Funk : 33|1@1+ (1,0) [0|1] ""  BCM1,Gateway,TSG_BFS,TSG_FS
 SG_ VIP_Sensor_betaetigt : 34|1@1+ (1,0) [0|1] ""  AAG,BCM1,Gateway,HDSG
 SG_ VIP_Freigabe : 35|1@1+ (1,0) [0|1] ""  Gateway
 SG_ ZV_zu_Zeitl_Nachverr : 36|1@1+ (1,0) [0|1] ""  BCM1,Gateway,TSG_BFS,TSG_FS
 SG_ ZV_HSK_entriegeln : 37|1@1+ (1,0) [0|1] ""  Gateway
 SG_ ZV_HSK_verriegeln : 38|1@1+ (1,0) [0|1] ""  Gateway
 SG_ ZV_Verdeck_zu : 39|1@1+ (1,0) [0|1] ""  Gateway,VSG
 SG_ ZV_Verdeck_auf : 40|1@1+ (1,0) [0|1] ""  Gateway,VSG
 SG_ FH_FT_hoch : 41|1@1+ (1,0) [0|1] ""  Gateway,TSG_FS
 SG_ FH_FT_tief : 42|1@1+ (1,0) [0|1] ""  Gateway,TSG_FS
 SG_ FH_BT_hoch : 43|1@1+ (1,0) [0|1] ""  Gateway,TSG_BFS
 SG_ FH_BT_tief : 44|1@1+ (1,0) [0|1] ""  Gateway,TSG_BFS
 SG_ FH_HFS_hoch : 45|1@1+ (1,0) [0|1] ""  Gateway,TSG_FS
 SG_ FH_HFS_tief : 46|1@1+ (1,0) [0|1] ""  Gateway,TSG_FS
 SG_ FH_HBFS_hoch : 47|1@1+ (1,0) [0|1] ""  Gateway,TSG_BFS
 SG_ FH_HBFS_tief : 48|1@1+ (1,0) [0|1] ""  Gateway,TSG_BFS
 SG_ BCM_Spg_Synchron : 49|1@1+ (1,0) [0|1] ""  Gateway,TSG_FS
 SG_ BCM_BF_Spg_Absenkung : 50|1@1+ (1,0) [0|1] ""  Gateway,TSG_BFS
 SG_ ZV_Signatur : 51|11@1+ (1,0) [0|2047] ""  Gateway,TSG_BFS,TSG_FS

BO_ 1411 ZV_02: 8 BCM2
 SG_ BCM_FH_Freigabe : 12|1@1+ (1,0) [0|1] ""  Gateway,MFG,SAD,SAD2,TSG_BFS,TSG_FS,VSG
 SG_ BCM_Komfortfkt_Freigabe : 13|1@1+ (1,0) [0|1] ""  BCM1,Gateway,SAD,SAD2,TSG_BFS,TSG_FS
 SG_ BCM_HSK_Freigabe : 14|1@1+ (1,0) [0|1] ""  Gateway
 SG_ BCM_Verdeck_Freigabe : 15|1@1+ (1,0) [0|1] ""  Gateway,TSG_BFS,TSG_FS,VSG
 SG_ ZV_verriegelt_intern_ist : 16|1@1+ (1,0) [0|1] ""  Gateway,MFG,TSG_BFS,TSG_FS,VTS
 SG_ ZV_verriegelt_extern_ist : 17|1@1+ (1,0) [0|1] ""  AAG,BCM1,Gateway,HDSG,MFG,SitzMem_FS,SitzMem_SR3,TSG_BFS,TSG_FS,VSG,VTS
 SG_ ZV_verriegelt_intern_soll : 18|1@1+ (1,0) [0|1] ""  Gateway,MFG,TSG_BFS,TSG_FS
 SG_ ZV_verriegelt_extern_soll : 19|1@1+ (1,0) [0|1] ""  AAG,BCM1,ELV,Gateway,MFG,SitzMem_BFS,SitzMem_FS,SitzMem_SR3,TSG_BFS,TSG_FS,VSG
 SG_ ZV_gesafet_extern_ist : 20|1@1+ (1,0) [0|1] ""  BCM1,Gateway,MFG,TSG_BFS,TSG_FS
 SG_ ZV_gesafet_extern_soll : 21|1@1+ (1,0) [0|1] ""  BCM1,ELV,Gateway,MFG,TSG_BFS,TSG_FS
 SG_ ZV_Einzeltuerentriegelung : 22|1@1+ (1,0) [0|1] ""  Gateway
 SG_ ZV_Heckeinzelentriegelung : 23|1@1+ (1,0) [0|1] ""  Gateway
 SG_ ZV_FT_offen : 24|1@1+ (1,0) [0|1] ""  BCM1,Gateway,MSBBR
 SG_ ZV_BT_offen : 25|1@1+ (1,0) [0|1] ""  BCM1,Gateway,MSBBR
 SG_ ZV_HFS_offen : 26|1@1+ (1,0) [0|1] ""  BCM1,Gateway,MSBBR,TSG_BFS,TSG_FS
 SG_ ZV_HBFS_offen : 27|1@1+ (1,0) [0|1] ""  BCM1,Gateway,MSBBR,TSG_BFS,TSG_FS
 SG_ ZV_HD_offen : 28|1@1+ (1,0) [0|1] ""  AAG,BCM1,Gateway,HDSG,MFG,MSBBR,SitzMem_SR3,SpoilerSG,VSG,VTS
 SG_ ZV_HS_offen : 29|1@1+ (1,0) [0|1] ""  AAG,BCM1,Gateway,MSBBR,SitzMem_SR3
 SG_ IRUE_aktiv : 30|1@1+ (1,0) [0|1] ""  Gateway
 SG_ DWA_aktiv : 31|1@1+ (1,0) [0|1] ""  BCM1,Gateway,MFG
 SG_ HD_Hauptraste : 32|1@1+ (1,0) [0|1] ""  Gateway,HDSG,VSG
 SG_ HD_Vorraste : 33|1@1+ (1,0) [0|1] ""  Gateway,HDSG
 SG_ FFB_HDF_Taste : 34|1@1+ (1,0) [0|1] ""  Gateway
 SG_ FFB_Panik_Taste : 35|1@1+ (1,0) [0|1] ""  Gateway
 SG_ FFB_Auf_Taste : 36|1@1+ (1,0) [0|1] ""  Gateway
 SG_ FFB_Zu_Taste : 37|1@1+ (1,0) [0|1] ""  Gateway
 SG_ FFB_CarFinder : 38|1@1+ (1,0) [0|1] ""  Gateway
 SG_ FFB_Komfortoeffnen : 39|1@1+ (1,0) [0|1] ""  Gateway
 SG_ FFB_Komfortschliessen : 40|1@1+ (1,0) [0|1] ""  Gateway
 SG_ FBS_IDG_in_Reichweite : 41|1@1+ (1,0) [0|1] ""  Gateway
 SG_ ZV_Schluessel_Zugang : 42|4@1+ (1,0) [0|15] ""  Gateway
 SG_ ZV_SafeFunktion_aktiv : 46|1@1+ (1,0) [0|1] ""  Gateway
 SG_ FBS_Warn_Schluessel_Batt : 47|1@1+ (1,0) [0|1] ""  Gateway
 SG_ ZV_Oeffnungsmodus : 48|2@1+ (1,0) [0|3] ""  Gateway
 SG_ HFS_verriegelt : 50|1@1+ (1,0) [0|1] ""  Gateway
 SG_ HFS_gesafet : 51|1@1+ (1,0) [0|1] ""  Gateway
 SG_ HBFS_verriegelt : 52|1@1+ (1,0) [0|1] ""  Gateway
 SG_ HBFS_gesafet : 53|1@1+ (1,0) [0|1] ""  Gateway
 SG_ ZV_ist_Zustand_verfuegbar : 54|1@1+ (1,0) [0|1] ""  BCM1,Gateway,MFG,SitzMem_BFS,SitzMem_FS
 SG_ IRUE_Taster_Fkts_LED : 55|1@1+ (1,0) [0|1] ""  Gateway,TSG_FS
 SG_ ZV_Tankklappe_offen : 56|1@1+ (1,0) [0|1] ""  Gateway
 SG_ ZV_Rollo_auf : 57|1@1+ (1,0) [0|1] ""  Gateway,SAD,SAD2
 SG_ ZV_Rollo_zu : 58|1@1+ (1,0) [0|1] ""  Gateway,SAD,SAD2
 SG_ ZV_SAD_auf : 59|1@1+ (1,0) [0|1] ""  Gateway,SAD,SAD2
 SG_ ZV_SAD_zu : 60|1@1+ (1,0) [0|1] ""  Gateway,SAD,SAD2
 SG_ BCM_Tankklappensteller_Fehler : 61|1@1+ (1,0) [0|1] ""  Gateway

CM_ SG_ 975 HBFS_Tuer_geoeffnet "HBFS Tuer geoeffnet";
CM_ SG_ 975 HBFS_verriegelt "Verriegelungsstatus Tür";
CM_ SG_ 975 HBFS_gesafet "HBFS Tuer gesafet.
Im Zustand Safe wird auch das Signal HBFS_verriegelt = 1 gesendet.";
CM_ SG_ 975 HBFS_Heckrollotaster_betaetigt "Verfahren des Heckrollos in Richtung Hoch

Bei Einfachtaster wird Bit als Togglebit verwendet (Heckrollo hoch, tief)";
CM_ SG_ 975 HBFS_Tuerschloss_defekt "Das hintere Tuerschloss auf der Beifahrerseite ist nicht mehr funktionsfähig.";
CM_ SG_ 975 HBFS_Unlock_Taster "Betaetigung Unlock Taster";
CM_ SG_ 975 HBFS_Lock_Taster "Betaetigung Lock-Taster";
CM_ SG_ 975 HBFS_Sperrklinke "Vorraste für Schloß

zwischen Vor- und Hauptraste Signal kurz auf 1, danach wieder auf 0 wenn Tür in Hauptraste (Tür ist sicher zu wenn Sperrklinke und Türkontakt auf 0 sind)";
CM_ SG_ 975 HBFS_TAG_betaetigt "Betaetigung Türaussengriff";
CM_ SG_ 975 HBFS_TIG_betaetigt "Betaetigung Tuerinnengriff";
CM_ SG_ 975 HBFS_FH_S_HFS_AutoHoch "Automatisches Hochfahren der Seitenscheibe HFS";
CM_ SG_ 975 HBFS_FH_S_HFS_AutoTief "Automatisches Absenken der Seitenscheibe HFS";
CM_ SG_ 975 HBFS_FH_S_HFS_ManHoch "Manuelles Hochfahren der Seitenscheibe HFS";
CM_ SG_ 975 HBFS_FH_S_HFS_ManTief "Manuelles Absenken der Seitenscheibe HFS";
CM_ SG_ 975 HBFS_Tuer_Status "Türstatus mit Fehler und Initwert";
CM_ SG_ 975 HBFS_SAD_Schalter "  |   Ausstelldach MD3
-----------------------------
0 | nicht_betaetigt
1 |
2 |
3 |
4 |
5 | (m) Auf
6 | (a) Auf
7 | (m) Zu
8 | (a) Zu
13| Schalter nicht verfuegbar
14| Init
15| Fehlerfall";
CM_ SG_ 975 HBFS_FH_S_ManHoch "Betaetigung FH Schalter man hoch ";
CM_ SG_ 975 HBFS_FH_S_AutoHoch "Betaetigung FH Schalter auto tief ";
CM_ SG_ 975 HBFS_FH_S_ManTief "Betaetigung FH Schalter man tief";
CM_ SG_ 975 HBFS_FH_S_AutoTief "Betaetigung FH Schalter auto hoch";
CM_ SG_ 975 HBFS_FH_Oeffnung "Gibt den Fensteröffnungswert in % an.";
CM_ SG_ 975 HBFS_FH_Bew_hoch "HBFS Fenster bewegt sich in Richtung hoch";
CM_ SG_ 975 HBFS_FH_Bew_tief "HFS Fenster bewegt sich in Richtung tief";
CM_ SG_ 975 HBFS_FH_Fang "Fangbereich ist 4mm von oberer Lippendichtung";
CM_ SG_ 975 HBFS_FH_Block "Fensterscheibe befindet sich im mechanischen Block (oben oder unten)";
CM_ SG_ 975 HBFS_FH_Thermo "gibt an ob Fensterheber im Thermoschutz ist";
CM_ SG_ 975 HBFS_UEKB_aktiviert "Überschutzbegrenzungskraft bei Reversieren";
CM_ SG_ 975 HBFS_Tuerschloss_verrieg_nicht "Die Fahrertür kann nicht verriegelt werden.";
CM_ SG_ 975 ASW_Warnung_aktiv_HBFS "Abschaltung der Ambientefunktion Tür hinten der Beifahrerseite bei aktiver ASW Warnung an der Fahrertür";
CM_ SG_ 975 HBFS_Status_KiSi "Status Kindersicherung HBFS
";
CM_ SG_ 975 SSR_HBFS_Pos_Unten "Signal für die 'Global Close'. Über dieses Bit wissen die anderen TSGs, ob der SSR oder der FH verfahren werden darf.";
CM_ SG_ 975 HBFS_Oben_Block_erw "Fensterheber in Blockerwartung oben";
CM_ SG_ 975 HBFS_Unten_Block_erw "Fensterheber in Blockerwartung unten";
CM_ SG_ 975 MTHBFS_M_Taste "Betätigung M-Taste HBFS";
CM_ SG_ 975 MTHBFS_Pos1 "Betätigung Postionstaste 1 HBFS";
CM_ SG_ 975 MTHBFS_Pos2 "Betätigung Postionstaste 2 HBFS
";
CM_ SG_ 975 MTHBFS_Pos3 "Betätigung Postionstaste 3 HBFS";
CM_ SG_ 975 HBFS_MRollo_Schalter "  | MRollo2
-----------------------------
0 | nicht_betaetigt
1 | (m) Zu
2 | (a) Zu
3 | (m) Auf
4 | (a) Auf
5 | Schalter nicht verfuegbar
6 | Init
7 | Fehlerfall";
CM_ SG_ 975 HBFS_Lock_Taster_inv "Lock Taster nicht betätigt";
CM_ SG_ 975 HBFS_Status_KiSi_inv "Inverser Status der elektrischen Kindersicherung Beifahrerseite hinten";
CM_ SG_ 1457 TSG_FlHz_HBFS_NTC_A "Flächenheizung: Temperatur und Fehlerwert des Heizaktors";
CM_ SG_ 1457 TSG_FlHz_HBFS_FnAbbruchHzKreis_A "Flächenheizung: Status";
CM_ SG_ 1457 TSG_FlHz_HBFS_NTC_B "Flächenheizung: Temperatur und Fehlerwert des Heizaktors";
CM_ SG_ 1457 TSG_FlHz_HBFS_FnAbbruchHzKreis_B "Flächenheizung: Status";
CM_ SG_ 974 HFS_Tuer_geoeffnet "HFS Tuer geoeffnet";
CM_ SG_ 974 HFS_verriegelt "HFS Tuer verriegelt";
CM_ SG_ 974 HFS_gesafet "HFS Tuer gesafet.
Im Zustand Safe wird auch das Signal HFS_verriegelt = 1 gesendet.";
CM_ SG_ 974 HFS_Heckrollotaster_betaetigt "Verfahren des Heckrollos in Richtung Hoch

Bei Einfachtaster wird Bit als Togglebit verwendet (Heckrollo hoch, tief)";
CM_ SG_ 974 HFS_Tuerschloss_defekt "Das hintere Tuerschloss auf der Fahrerseite ist nicht mehr funktionsfähig.";
CM_ SG_ 974 HFS_Unlock_Taster "Betaetigung Unlock Taster";
CM_ SG_ 974 HFS_Lock_Taster "Betätigung Lock-Taster";
CM_ SG_ 974 HFS_Sperrklinke "Vorraste für Schloß

zwischen Vor- und Hauptraste Signal kurz auf 1, danach wieder auf 0 wenn Tür in Hauptraste (Tür ist sicher zu wenn Sperrklinke und Türkontakt auf 0 sind)";
CM_ SG_ 974 HFS_TAG_betaetigt "Betaetigung Türaussengriff";
CM_ SG_ 974 HFS_TIG_betaetigt "Betaetigung Türinnengriff";
CM_ SG_ 974 HFS_FH_S_HBFS_AutoHoch "Automatisches Hochfahren der Seitenscheibe HBFS";
CM_ SG_ 974 HFS_FH_S_HBFS_AutoTief "Automatisches Absenken der Seitenscheibe HBFS";
CM_ SG_ 974 HFS_FH_S_HBFS_ManHoch "Manuelles Hochfahren der Seitenscheibe HBFS";
CM_ SG_ 974 HFS_FH_S_HBFS_ManTief "Manuelles Absenken der Seitenscheibe HBFS";
CM_ SG_ 974 HFS_Tuer_Status "Türstatus mit Fehler und Initwert";
CM_ SG_ 974 HFS_SAD_Schalter "  |   Ausstelldach MD3
-----------------------------
0 | nicht_betaetigt
1 |
2 |
3 |
4 |
5 | (m) Auf
6 | (a) Auf
7 | (m) Zu
8 | (a) Zu
13| Schalter nicht verfuegbar
14| Init
15| Fehlerfall";
CM_ SG_ 974 HFS_FH_S_ManHoch "Betaetigung FH Schalter man hoch ";
CM_ SG_ 974 HFS_FH_S_AutoHoch "Betaetigung FH Schalter auto hoch";
CM_ SG_ 974 HFS_FH_S_ManTief "Betaetigung FH Schalter man tief";
CM_ SG_ 974 HFS_FH_S_AutoTief "Betaetigung FH Schalter auto tief ";
CM_ SG_ 974 HFS_FH_Oeffnung "Gibt den Fensteröffnungswert in % an.";
CM_ SG_ 974 HFS_FH_Bew_hoch "HFS Fenster bewegt sich in Richtung hoch";
CM_ SG_ 974 HFS_FH_Bew_tief "HFS Fenster bewegt sich in Richtung tief";
CM_ SG_ 974 HFS_FH_Fang "Fangbereich ist 4mm von oberer Lippendichtung";
CM_ SG_ 974 HFS_FH_Block "Fensterscheibe befindet sich im mechanischen Block (oben oder unten)";
CM_ SG_ 974 HFS_FH_Thermo "gibt an ob Fensterheber im Thermoschutz ist";
CM_ SG_ 974 HFS_UEKB_aktiviert "Überschutzbegrenzungskraft bei Reversieren";
CM_ SG_ 974 HFS_Tuerschloss_verrieg_nicht "Das Türschloss kann nicht verriegelt werden";
CM_ SG_ 974 ASW_Warnung_aktiv_HFS "Abschaltung der Ambientefunktion Tür hinten der Fahrerseite bei aktiver ASW Warnung an der Fahrertür";
CM_ SG_ 974 HFS_Status_KiSi "Status Kindersicherung hinten Fahrerseite";
CM_ SG_ 974 SSR_HFS_Pos_Unten "Signal für die 'Global Close'. Über dieses Bit wissen die anderen TSGs, ob der SSR oder der FH verfahren werden darf.";
CM_ SG_ 974 HFS_Oben_Block_erw "Fensterheber in Blockerwartung oben";
CM_ SG_ 974 HFS_Unten_Block_erw "Fensterheber in Blockerwartung unten";
CM_ SG_ 974 MTHFS_M_Taste "Betätigung M-Taste HFS";
CM_ SG_ 974 MTHFS_Pos1 "Betätigung Postionstaste 1 HFS";
CM_ SG_ 974 MTHFS_Pos2 "Betätigung Postionstaste 2 HFS
";
CM_ SG_ 974 MTHFS_Pos3 "Betätigung Postionstaste 3 HFS";
CM_ SG_ 974 HFS_MRollo_Schalter "  | MRollo2
-----------------------------
0 | nicht_betaetigt
1 | (m) Zu
2 | (a) Zu
3 | (m) Auf
4 | (a) Auf
5 | Schalter nicht verfuegbar
6 | Init
7 | Fehlerfall";
CM_ SG_ 974 HFS_Lock_Taster_inv "Lock Taster nicht betätigt";
CM_ SG_ 1458 TSG_FlHz_HFS_NTC_A "Flächenheizung: Temperatur und Fehlerwert des Heizaktors";
CM_ SG_ 1458 TSG_FlHz_HFS_FnAbbruchHzKreis_A "Flächenheizung: Status";
CM_ SG_ 1458 TSG_FlHz_HFS_NTC_B "Flächenheizung: Temperatur und Fehlerwert des Heizaktors";
CM_ SG_ 1458 TSG_FlHz_HFS_FnAbbruchHzKreis_B "Flächenheizung: Status";
CM_ SG_ 346 TSK_08_CRC "Für MLB:
'Berechnung siehe Lastenheft 'Kommunikationsabsicherung für FlexRay und CAN''

Ab MQB und MLBevo:
'Berechnung siehe Lastenheft 'End-to-End Kommunikationsabsicherung''

Endwerte siehe Begleitdokument 'S-PDU Kennungsfolgen'";
CM_ SG_ 346 MO_Anforderung_HMS "Halteanforderung vom Motor an HMS";
CM_ SG_ 346 TSK_vMax_Fahrerassistenz "maximale Sollgeschwindigkeit für GRA/ACC/Limiter
Hinweis: Signal ist mit Signal TSK_Einheit_vMax_Fahrerassistenz zu interpretieren.  Das Signal wird abwechselnd in km/h und mph gesendet.";
CM_ SG_ 346 TSK_Einheit_vMax_Fahrerassistenz "Einheit zu Signal TSK_vMax_Fahrerassistenz";
CM_ SG_ 346 TSK_Status_PLA "Funktionsstatus des Triebstrangkoordinators für den Speedlimiter des Parkassistenten";
CM_ SG_ 346 TSK_aktives_System "Anzeige der in der TSK-Längsführung aktiven Funktion";
CM_ SG_ 346 TSK_erhoehter_Fahrwiderstand "Rückmeldung vom Triebstrangkoordinator, dass eine große Reglerdifferenz detektiert wurde. Soll ermöglichen, einen ggfs. unbekannten Fahrwiderstand am Boden zu erkennen.";
CM_ SG_ 346 TSK_Status_ARA "Funktionsstatus des Triebstrangkoordinators für den Anhängerrangierassistenten";
CM_ SG_ 346 TSK_Status_IPA "Funktionsstatus des Triebstrangkoordinators für die Längsführung des Einparkassistenten";
CM_ BO_ 995 "ab MQB IS5";
CM_ SG_ 995 VS_VD_zu_ver "
";
CM_ SG_ 995 VS_VD_entriegelt "

";
CM_ SG_ 995 VS_VD_offen_ver "

";
CM_ SG_ 995 VS_VD_Zwischenposition "

";
CM_ SG_ 995 VS_VD_Bew_auf "



";
CM_ SG_ 995 VS_VD_Bew_zu "


";
CM_ SG_ 995 VS_Verdeck_Anf "



";
CM_ SG_ 995 VS_Hardtop "



";
CM_ SG_ 995 VS_VD_Fehler "

";
CM_ SG_ 995 VS_Lampe_Blk "Ansteuerung Lampe im Kombi

Wird aktiviert bei Aufprüfen, Verdecklauf und Fehlerfall (blinkend).


";
CM_ SG_ 995 VS_Buzzer "Buzzeransteuerung: 'Buzzeransteuerung' für Gong 200ms (Kombi)";
CM_ SG_ 995 VS_HD_sperren "Bei gesetztem Signal wird der Kofferraum/Heckdeckel durch den BCM2 nicht entriegelt werden.";
CM_ SG_ 995 VS_HHS_enable "

";
CM_ SG_ 995 ZFH_FS_AutoHoch "automatischer Hochlauf des FS Fenster ausgelöst durch zentralen Fensterhebertaster";
CM_ SG_ 995 ZFH_FS_AutoTief "automatischer Tieflauf des FS Fenster ausgelöst durch zentralen Fensterhebertaster";
CM_ SG_ 995 ZFH_FS_ManHoch "manueller Hochlauf des FS Fenster ausgelöst durch zentralen Fensterhebertaster";
CM_ SG_ 995 ZFH_FS_ManTief "manueller Tieflauf des FS Fenster ausgelöst durch zentralen Fensterhebertaster";
CM_ SG_ 995 ZFH_BFS_AutoHoch "automatischer Hochlauf des BFS Fenster ausgelöst durch zentralen Fensterhebertaster";
CM_ SG_ 995 ZFH_BFS_AutoTief "automatischer Tieflauf des BFS Fenster ausgelöst durch zentralen Fensterhebertaster";
CM_ SG_ 995 ZFH_BFS_ManHoch "manueller Hochlauf des BFS Fenster ausgelöst durch zentralen Fensterhebertaster";
CM_ SG_ 995 ZFH_BFS_ManTief "manueller Tieflauf des BFS Fenster ausgelöst durch zentralen Fensterhebertaster";
CM_ SG_ 995 ZFH_HFS_AutoHoch "automatischer Hochlauf des HFS Fenster ausgelöst durch zentralen Fensterhebertaster";
CM_ SG_ 995 ZFH_HFS_AutoTief "automatischer Tieflauf des HFS Fenster ausgelöst durch zentralen Fensterhebertaster";
CM_ SG_ 995 ZFH_HFS_ManHoch "manueller Hochlauf des HFS Fenster ausgelöst durch zentralen Fensterhebertaster";
CM_ SG_ 995 ZFH_HFS_ManTief "manueller Tieflauf des HFS Fenster ausgelöst durch zentralen Fensterhebertaster";
CM_ SG_ 995 ZFH_HBFS_AutoHoch "automatischer Hochlauf des HBFS Fenster ausgelöst durch zentralen Fensterhebertaster";
CM_ SG_ 995 ZFH_HBFS_AutoTief "automatischer Tieflauf des HBFS Fenster ausgelöst durch zentralen Fensterhebertaster";
CM_ SG_ 995 ZFH_HBFS_ManHoch "manueller Hochlauf des HBFS Fenster ausgelöst durch zentralen Fensterhebertaster";
CM_ SG_ 995 ZFH_HBFS_ManTief "manueller Tieflauf des HBFS Fenster ausgelöst durch zentralen Fensterhebertaster";
CM_ SG_ 995 VS_FH_FT_Langhub "Ansteuerung Fensterheber vom Verdecksteuergeraet";
CM_ SG_ 995 VS_FH_BT_Langhub "Ansteuerung Fensterheber vom Verdecksteuergeraet";
CM_ SG_ 995 VS_FH_HFS_Langhub "Ansteuerung Fensterheber vom Verdecksteuergeraet";
CM_ SG_ 995 VS_Heckschloss_auf "Signal wird gesetzt, wenn fuer einen Verdeckbetrieb das Öffnen des Heckschlosses erforderlich ist.";
CM_ SG_ 995 VS_FH_HBFS_Langhub "Ansteuerung Fensterheber vom Verdecksteuergeraet";
CM_ SG_ 995 VSG_Meldungen "Meldungen fuers Kombi lt. konzernübergreifender Abstimmung

0 -> keine Meldung
1 -> Meldung für 'Verdeckbetrieb RDW aktiv'
2 -> Meldung für 'Verdeckbetrieb NAR aktiv'
3 -> Meldung für 'stehendes Verdeck in Zwischenposition (ZP)'
4 -> Meldung für  'a";
CM_ BO_ 1716 "200ms bei D4 und folgende";
CM_ SG_ 1716 VIN_01_MUX "Achtung:
Die Botschaft ist nicht linear gemultiplext!!!
Sondern 0,1,0,2,0, usw.";
CM_ SG_ 1716 VIN_4 "Initwert:
0x2D bei Fahrzeugen mit Wegfahrsperrengeneration >= 5 
0x58 bei Fahrzeugen mit Wegfahrsperrengeneration < 5 (z.B. WFS-4)";
CM_ SG_ 1716 VIN_11 "Initwert:
0x2D bei Fahrzeugen mit Wegfahrsperrengeneration >= 5 
0x58 bei Fahrzeugen mit Wegfahrsperrengeneration < 5 (z.B. WFS-4)";
CM_ SG_ 1716 VIN_5 "Initwert:
0x2D bei Fahrzeugen mit Wegfahrsperrengeneration >= 5 
0x58 bei Fahrzeugen mit Wegfahrsperrengeneration < 5 (z.B. WFS-4)";
CM_ SG_ 1716 VIN_12 "Initwert:
0x2D bei Fahrzeugen mit Wegfahrsperrengeneration >= 5 
0x58 bei Fahrzeugen mit Wegfahrsperrengeneration < 5 (z.B. WFS-4)";
CM_ SG_ 1716 VIN_6 "Initwert:
0x2D bei Fahrzeugen mit Wegfahrsperrengeneration >= 5 
0x58 bei Fahrzeugen mit Wegfahrsperrengeneration < 5 (z.B. WFS-4)";
CM_ SG_ 1716 VIN_13 "Initwert:
0x2D bei Fahrzeugen mit Wegfahrsperrengeneration >= 5 
0x58 bei Fahrzeugen mit Wegfahrsperrengeneration < 5 (z.B. WFS-4)";
CM_ SG_ 1716 VIN_7 "Initwert:
0x2D bei Fahrzeugen mit Wegfahrsperrengeneration >= 5 
0x58 bei Fahrzeugen mit Wegfahrsperrengeneration < 5 (z.B. WFS-4)";
CM_ SG_ 1716 VIN_14 "Initwert:
0x2D bei Fahrzeugen mit Wegfahrsperrengeneration >= 5 
0x58 bei Fahrzeugen mit Wegfahrsperrengeneration < 5 (z.B. WFS-4)";
CM_ SG_ 1716 VIN_1 "Initwert:
0x2D bei Fahrzeugen mit Wegfahrsperrengeneration >= 5 
0x58 bei Fahrzeugen mit Wegfahrsperrengeneration < 5 (z.B. WFS-4)";
CM_ SG_ 1716 VIN_8 "Initwert:
0x2D bei Fahrzeugen mit Wegfahrsperrengeneration >= 5 
0x58 bei Fahrzeugen mit Wegfahrsperrengeneration < 5 (z.B. WFS-4)";
CM_ SG_ 1716 VIN_15 "Initwert:
0x2D bei Fahrzeugen mit Wegfahrsperrengeneration >= 5 
0x58 bei Fahrzeugen mit Wegfahrsperrengeneration < 5 (z.B. WFS-4)";
CM_ SG_ 1716 VIN_2 "Initwert:
0x2D bei Fahrzeugen mit Wegfahrsperrengeneration >= 5 
0x58 bei Fahrzeugen mit Wegfahrsperrengeneration < 5 (z.B. WFS-4)";
CM_ SG_ 1716 VIN_9 "Initwert:
0x2D bei Fahrzeugen mit Wegfahrsperrengeneration >= 5 
0x58 bei Fahrzeugen mit Wegfahrsperrengeneration < 5 (z.B. WFS-4)";
CM_ SG_ 1716 VIN_16 "Initwert:
0x2D bei Fahrzeugen mit Wegfahrsperrengeneration >= 5 
0x58 bei Fahrzeugen mit Wegfahrsperrengeneration < 5 (z.B. WFS-4)";
CM_ SG_ 1716 VIN_3 "Initwert:
0x2D bei Fahrzeugen mit Wegfahrsperrengeneration >= 5 
0x58 bei Fahrzeugen mit Wegfahrsperrengeneration < 5 (z.B. WFS-4)";
CM_ SG_ 1716 VIN_10 "Initwert:
0x2D bei Fahrzeugen mit Wegfahrsperrengeneration >= 5 
0x58 bei Fahrzeugen mit Wegfahrsperrengeneration < 5 (z.B. WFS-4)";
CM_ SG_ 1716 VIN_17 "Initwert:
0x2D bei Fahrzeugen mit Wegfahrsperrengeneration >= 5 
0x58 bei Fahrzeugen mit Wegfahrsperrengeneration < 5 (z.B. WFS-4)";
CM_ SG_ 1361 WFS_Schluessel_Fahrberecht "Schlüsselnummer Fahrberechtigung
0 = ungueltig, xxxx = Schluessel-Nr.";
CM_ SG_ 1361 WFS_ID_Geb_autorisiert "Authorisierung Schluessel (ID-Geber)
";
CM_ SG_ 1361 WFS_ID_Geb_autorisiert_in_Kl15 "Authorisierung des Schlüssels im aktiven Klemme-15-Zyklus";
CM_ SG_ 1361 WFS_ID_Geb_steckt "Schluessel (ID-Geber) im Zuendschloss
";
CM_ SG_ 1361 WFS_Schluessel_Soll "Sollwert der zu lernenden Schluessel";
CM_ SG_ 1361 WFS_Schluessel_Ist "Istwert der gelernten Schluessel";
CM_ SG_ 1361 WFS_Safe "Status WFS
";
CM_ SG_ 1361 WFS_LZ "Anforderung aus Lastenheft WFS V
";
CM_ SG_ 1361 WFS_ELV_authorisiert "Authorisierung der elektrischen Lenkungsverriegelung an der WFS";
CM_ SG_ 1361 WFS_LF_Aktiv "LF Schluesselkommunikation
";
CM_ SG_ 1361 WFS_Betrieb_Lesespule "Schlüsselkommunikation über die Lesespule";
CM_ SG_ 1361 WFS_Klemmenfreigabe "Freigabe von der WFS zum Einschalten der Klemme 15 und Klemme S";
CM_ SG_ 1361 WFS_Fahrerhinweise "Meldungen, Fahrer- und Warnhinweise der Wegfahrsperre";
CM_ BO_ 1702 "MLBevo";
CM_ SG_ 1702 Wischer_vorne_aktiv "Status: Wischer vorne ";
CM_ SG_ 1702 Waschen_vorne_aktiv "Status: Waschen vorne aktiv 
";
CM_ SG_ 1702 Wischer_vorne_Normal "Wischer Front normal aktiv";
CM_ SG_ 1702 Wischer_vorne_Schnell "Wischer vorne schnell aktiv";
CM_ SG_ 1702 Wischer_vorne_Parklage "Wischer Front in Parklage";
CM_ SG_ 1702 Wischer_vorne_defekt "Fehlerstatus Wischer vorne (Anzeige im Kombi)";
CM_ SG_ 1702 Wischer_vorne_blockiert "Blockade Wischer vorne (z.B. durch Schnee)";
CM_ SG_ 1702 Wischer1_Wischgeschwindigkeit "aktuelle, durch Sensorik gemessene Wischgeschwindigkeit";
CM_ SG_ 1702 BCM1_SRA_aktiv "Status Scheinwerferreinigungsanlage";
CM_ SG_ 1702 Heckwischer_Anforderung "Das Signal beschreibt die Anforderung an den Signalausgang im BCM2 zur Ansteuerung des Heckwischers.";
CM_ SG_ 1702 WWSs_01_upd "Update-Bit für die LIN-Botschaft WWSs_01.

Betroffene Signale:

Wischer_vorne_aktiv
Wischer1_Wischgeschwindigkeit";
CM_ SG_ 2527679496 WIV_Verschleissindex_02 "Bei Otto Verbrauch, bei Diesel Verschleiss";
CM_ SG_ 2527679496 WIV_Verschleissindex_Ueberlauf "Der motorsteuergeräteinterne Zähler für den Verschleissindex (Diesel) bzw. Verbrauchsindex (Otto) ist mindestens einmal übergelaufen. Dieses Bit wird genutzt, um erkennen zu können, daß das Motorsteuergerät aus dem Reset-Zustand hochläuft.";
CM_ SG_ 2527679496 WIV_Russindex_02 "Nur für Diesel, Rußwert, bei Otto Wert = 0";
CM_ SG_ 2527679496 WIV_Russindex_Ueberlauf "Der motorsteuergeräteinterne Zähler für den Russindex ist mindestens einmal übergelaufen. Dieses Bit wird genutzt, um erkennen zu können, daß das Motorsteuergerät aus dem Reset-Zustand hochläuft.";
CM_ SG_ 2527679496 WIV_t_min "Minimales Wartungsintervall für WIV in Monaten";
CM_ SG_ 2527679496 WIV_t_max "Maximales Wartungsintervall für WIV in Monaten";
CM_ SG_ 2527679496 WIV_W_min "Minimales Wartungsintervall für WIV in km";
CM_ SG_ 2527679496 WIV_W_max "Maximales Wartungsintervall für WIV in km";
CM_ BO_ 2617138688 "ab MQB";
CM_ BO_ 2617138689 "ab MQB";
CM_ BO_ 2617136640 "ab MQB";
CM_ BO_ 2617136641 "ab MQB";
CM_ BO_ 2566802688 "ab MQB";
CM_ BO_ 2566802689 "ab MQB";
CM_ BO_ 2566802432 "ab MQB";
CM_ BO_ 2566802433 "ab MQB";
CM_ BO_ 389 "Zentraler Fensterhebertaster

ab MQB gueltig";
CM_ SG_ 389 ZFH_FS_ManHoch "manueller Hochlauf des FS Fenster ausgelöst durch zentralen Fensterhebertaster";
CM_ SG_ 389 ZFH_FS_AutoHoch "automatischer Hochlauf des FS Fenster ausgelöst durch zentralen Fensterhebertaster";
CM_ SG_ 389 ZFH_FS_ManTief "manueller Tieflauf des FS Fenster ausgelöst durch zentralen Fensterhebertaster";
CM_ SG_ 389 ZFH_FS_AutoTief "automatischer Tieflauf des FS Fenster ausgelöst durch zentralen Fensterhebertaster";
CM_ SG_ 389 ZFH_BFS_ManHoch "manueller Hochlauf des BFS Fenster ausgelöst durch zentralen Fensterhebertaster";
CM_ SG_ 389 ZFH_BFS_AutoHoch "automatischer Hochlauf des BFS Fenster ausgelöst durch zentralen Fensterhebertaster";
CM_ SG_ 389 ZFH_BFS_ManTief "manueller Tieflauf des BFS Fenster ausgelöst durch zentralen Fensterhebertaster";
CM_ SG_ 389 ZFH_BFS_AutoTief "automatischer Tieflauf des BFS Fenster ausgelöst durch zentralen Fensterhebertaster";
CM_ SG_ 389 ZFH_HFS_ManHoch "manueller Hochlauf des HFS Fenster ausgelöst durch zentralen Fensterhebertaster";
CM_ SG_ 389 ZFH_HFS_AutoHoch "automatischer Hochlauf des HFS Fenster ausgelöst durch zentralen Fensterhebertaster";
CM_ SG_ 389 ZFH_HFS_ManTief "manueller Tieflauf des HFS Fenster ausgelöst durch zentralen Fensterhebertaster";
CM_ SG_ 389 ZFH_HFS_AutoTief "automatischer Tieflauf des HFS Fenster ausgelöst durch zentralen Fensterhebertaster";
CM_ SG_ 389 ZFH_HBFS_ManHoch "manueller Hochlauf des HBFS Fenster ausgelöst durch zentralen Fensterhebertaster";
CM_ SG_ 389 ZFH_HBFS_AutoHoch "automatischer Hochlauf des HBFS Fenster ausgelöst durch zentralen Fensterhebertaster";
CM_ SG_ 389 ZFH_HBFS_ManTief "manueller Tieflauf des HBFS Fenster ausgelöst durch zentralen Fensterhebertaster";
CM_ SG_ 389 ZFH_HBFS_AutoTief "automatischer Tieflauf des HBFS Fenster ausgelöst durch zentralen Fensterhebertaster";
CM_ SG_ 389 ZFH_zentral_zu "Zentraler Hochlauf aller Seitenscheiben";
CM_ SG_ 389 ZFH_zentral_auf "Zentraler Tieflauf aller Seitenscheiben";
CM_ SG_ 389 Krypt_Signatur "Kryptologiesignatur";
CM_ SG_ 389 Krypt_Schluesselschalter_auf "Schluesselschalter 'Auf' betaetigt";
CM_ SG_ 389 Krypt_Schluesselschalter_zu "Schluesselschalter 'ZU' betaetigt";
CM_ BO_ 392 "Zentraler Fensterhebertaster

ab MQB gueltig";
CM_ SG_ 392 BT_FH_BT_ManHoch "manueller Hochlauf der Beifahrertür Seitenscheiben ausgelöst durch zentralen Fensterhbertaster";
CM_ SG_ 392 BT_FH_BT_AutoHoch "automatischer Hochlauf der Beifahrertür Seitenscheiben ausgelöst durch zentralen Fensterhbertaster";
CM_ SG_ 392 BT_FH_BT_ManTief "manueller Tieflauf der Beifahrertür Seitenscheiben ausgelöst durch zentralen Fensterhbertaster";
CM_ SG_ 392 BT_FH_BT_AutoTief "automatischer Tieflauf der Beifahrertür Seitenscheiben ausgelöst durch zentralen Fensterhbertasterv";
CM_ SG_ 392 BT_FH_FT_ManHoch "manueller Hochlauf der Fahrertür Seitenscheiben ausgelöst durch zentralen Fensterhbertaster";
CM_ SG_ 392 BT_FH_FT_AutoHoch "automatischer Hochlauf der Fahrertür Seitenscheiben ausgelöst durch zentralen Fensterhbertaster";
CM_ SG_ 392 BT_FH_FT_ManTief "manueller Tieflauf der Fahrertür Seitenscheiben ausgelöst durch zentralen Fensterhbertaster";
CM_ SG_ 392 BT_FH_FT_AutoTief "automatischer Tieflauf der Fahrertür Seitenscheiben ausgelöst durch zentralen Fensterhbertaster";
CM_ SG_ 392 BT_FH_HFS_ManHoch "manueller Hochlauf der hinteren Türseitenscheiben Fahrerseite - durch zentralen Fensterhbertaster";
CM_ SG_ 392 BT_FH_HFS_AutoHoch "automatischer Hochlauf der hinteren Türseitenscheiben Fahrerseite - ausgelöst durch zentralen Fensterhbertaster";
CM_ SG_ 392 BT_FH_HFS_ManTief "manueller Tieflauf der hinteren Türseitenscheiben Fahrerseite - durch zentralen Fensterhbertaster";
CM_ SG_ 392 BT_FH_HFS_AutoTief "automatischer Tieflauf der hinteren Türseitenscheiben Fahrerseite - ausgelöst durch zentralen Fensterhbertaster";
CM_ SG_ 392 BT_FH_HBFS_ManHoch "manueller Hochlauf der hinteren Türseitenscheibe Beifahrerseite - ausgelöst durch zentralen Fensterhbertaster";
CM_ SG_ 392 BT_FH_HBFS_AutoHoch "automatischer Hochlauf der hinteren Türseitenscheibe Beifahrerseite - ausgelöst durch zentralen Fensterhbertaster";
CM_ SG_ 392 BT_FH_HBFS_ManTief "manueller Tieflauf der hinteren Türseitenscheibe Beifahrerseite - ausgelöst durch zentralen Fensterhbertaster";
CM_ SG_ 392 BT_FH_HBFS_AutoTief "automatischer Tieflauf der hinteren Türseitenscheibe Beifahrerseite - ausgelöst durch zentralen Fensterhbertaster";
CM_ SG_ 392 BT_SP_hoch "nicht in B8 und C6";
CM_ SG_ 392 BT_SP_tief "nicht in B8 und C6";
CM_ SG_ 392 BT_SP_links "nicht in B8 und C6";
CM_ SG_ 392 BT_SP_rechts "nicht in B8 und C6";
CM_ SG_ 392 BT_SP_Garagenstellung "Spiegel wird angeklappt

nicht in B8 und C6";
CM_ SG_ 392 BT_SP_Fahrstellung "Spiegel ausgeklappt

nicht in B8 und C6";
CM_ SG_ 388 ZV_01_CRC "Für MLB:
'Berechnung siehe Lastenheft 'Kommunikationsabsicherung für FlexRay und CAN''

Ab MQB und MLBevo:
'Berechnung siehe Lastenheft 'End-to-End Kommunikationsabsicherung''

Endwerte siehe Begleitdokument 'S-PDU Kennungsfolgen'";
CM_ SG_ 388 ZV_FT_verriegeln "Verriegelungsanforderung ZV für FT
";
CM_ SG_ 388 ZV_FT_entriegeln "Entriegelungsanforderung ZV für FT
";
CM_ SG_ 388 ZV_BT_verriegeln "Verriegelungsanforderung ZV für BT";
CM_ SG_ 388 ZV_BT_entriegeln "Beifahrertür entriegeln (Anforderung ZV)
";
CM_ SG_ 388 ZV_HFS_verriegeln "Verriegelungsanforderung ZV für HFS
";
CM_ SG_ 388 ZV_HFS_entriegeln "Entriegelungsanforderung ZV für HFS
";
CM_ SG_ 388 ZV_HBFS_verriegeln "Verriegelungsanforderung ZV für HBFS
";
CM_ SG_ 388 ZV_HBFS_entriegeln "Entriegelungsanforderung ZV für HBFS
";
CM_ SG_ 388 ZV_zentral_safen "Zentral safen

";
CM_ SG_ 388 ZV_zentral_entsafen "Zentral entsafen";
CM_ SG_ 388 ZV_Spg_Anklappen "Anforderung über ZV: Spiegel sind anzuklappen";
CM_ SG_ 388 ZV_Softtouch_betaetigt "Betätigung Softtouch
";
CM_ SG_ 388 ZV_LED_Steuerung "Ansteuerung der LED's in den Tueren; BAF gilt nicht für dieses Bit";
CM_ SG_ 388 ZV_LED_Uebernahme "Uebernahme der LED Steuerung durch das TSG FT
";
CM_ SG_ 388 ZV_auf_FT "ZV Schliessstelle";
CM_ SG_ 388 ZV_zu_FT "ZV Schliessstelle";
CM_ SG_ 388 ZV_auf_BT "ZV Schliessstelle";
CM_ SG_ 388 ZV_zu_BT "ZV Schliessstelle";
CM_ SG_ 388 ZV_auf_Kessy "ZV Schliessstelle";
CM_ SG_ 388 ZV_zu_Kessy "ZV Schliessstelle";
CM_ SG_ 388 ZV_auf_Funk "ZV Schliessstelle";
CM_ SG_ 388 ZV_zu_Funk "ZV Schliessstelle";
CM_ SG_ 388 VIP_Sensor_betaetigt "Heckentriegelung durch die Bedienstelle Virtuelles Pedal(VIP) erkannt. Der VIP Sensor hat eine Fusskickbewegung erkannt und es wurde ein Kessy - Schlüssel im Heckaussenbereich erkannt.";
CM_ SG_ 388 VIP_Freigabe "Vituelles Pedal ist über HMI freigeschaltet.";
CM_ SG_ 388 ZV_zu_Zeitl_Nachverr "ZV Schliessstelle";
CM_ SG_ 388 ZV_HSK_entriegeln "Anforderungssignal zur Ansteuerung des Handschuhkastenmotors in Richtung Entriegeln. ";
CM_ SG_ 388 ZV_HSK_verriegeln "Anforderungssignal zur Ansteuerung des Handschuhkastenmotors in Richtung Verriegeln. ";
CM_ SG_ 388 ZV_Verdeck_zu "Anforderungssignal für ein Komfortschließen des Verdecks. 
Signal wird angefordert wenn  SKontakt = 0 und eine Doppelbetätigung Schließzylinder_Zu oder Funkfernbedienung_Taste_zu  innerhalb zwei Sekunden empfangen wird. Signal wird auch angefordert wenn ";
CM_ SG_ 388 ZV_Verdeck_auf "Anforderungssignal für ein Komfortöffnen des Verdecks. 
Signal wird angefordert wenn  SKontakt = 0 und eine Doppelbetätigung Schließzylinder_auf oder Funkfernbedienung_Taste_auf  innerhalb zwei Sekunden empfangen wird. Signal wird auch angefordert wenn S";
CM_ SG_ 388 FH_FT_hoch "Freigabeinformation fuer die FH-Komfortfunktion";
CM_ SG_ 388 FH_FT_tief "Freigabeinformation fuer die FH-Komfortfunktion";
CM_ SG_ 388 FH_BT_hoch "Freigabeinformation fuer die FH-Komfortfunktion";
CM_ SG_ 388 FH_BT_tief "Freigabeinformation fuer die FH-Komfortfunktion";
CM_ SG_ 388 FH_HFS_hoch "Freigabeinformation fuer die FH-Komfortfunktion";
CM_ SG_ 388 FH_HFS_tief "Freigabeinformation fuer die FH-Komfortfunktion";
CM_ SG_ 388 FH_HBFS_hoch "Freigabeinformation fuer die FH-Komfortfunktion";
CM_ SG_ 388 FH_HBFS_tief "Freigabeinformation fuer die FH-Komfortfunktion";
CM_ SG_ 388 BCM_Spg_Synchron "Anforderung zur Aktivierung der synchronen Spiegelverstellung";
CM_ SG_ 388 ZV_Signatur "Signatur der ZV";
CM_ SG_ 1411 BCM_FH_Freigabe "Funktionsfreigabe Fensterheber";
CM_ SG_ 1411 BCM_Komfortfkt_Freigabe "globale Freigabe der Komfortfunktion";
CM_ SG_ 1411 BCM_HSK_Freigabe "Handschuhkastenfreigabe";
CM_ SG_ 1411 BCM_Verdeck_Freigabe "Freigabe Verdeckbetrieb
";
CM_ SG_ 1411 ZV_verriegelt_intern_ist "Istzustand: Verriegelung Fahrzeug innen
";
CM_ SG_ 1411 ZV_verriegelt_extern_ist "Istzustand: Verriegelung Fahrzeug aussen
";
CM_ SG_ 1411 ZV_verriegelt_intern_soll "Sollzustand: Verriegelung Fahrzeug innen
";
CM_ SG_ 1411 ZV_verriegelt_extern_soll "Sollzustand: Verriegelung Fahrzeug aussen
";
CM_ SG_ 1411 ZV_gesafet_extern_ist "Istzustand: Fahrzeug aussen gesafet
";
CM_ SG_ 1411 ZV_gesafet_extern_soll "Sollzustand: Fahrzeug gesafet extern
";
CM_ SG_ 1411 ZV_Einzeltuerentriegelung "Einzeltürentriegelung ZV
";
CM_ SG_ 1411 ZV_Heckeinzelentriegelung "Heckdeckeleinzelentriegelung";
CM_ SG_ 1411 ZV_FT_offen "gespiegeltes Bit FT_Tuer_geoeffnet TSG_FT_1 Botschaft";
CM_ SG_ 1411 ZV_BT_offen "gespiegeltes Bit BT_Tuer_geoeffnet TSG_BT_1 Botschaft";
CM_ SG_ 1411 ZV_HFS_offen "gespiegeltes Bit HFS_Tuer_geoeffnet TSG_HFS_1 Botschaft";
CM_ SG_ 1411 ZV_HBFS_offen "gespiegeltes Bit HBFS_Tuer_geoeffnet TSG_HBFS_1 Botschaft";
CM_ SG_ 1411 ZV_HD_offen "Status Heckdeckel
";
CM_ SG_ 1411 ZV_HS_offen "Status Heckscheibe
";
CM_ SG_ 1411 IRUE_aktiv "Status Innenraumüberwachung
";
CM_ SG_ 1411 DWA_aktiv "Status DWA
";
CM_ SG_ 1411 HD_Hauptraste "SBL-Schloss (MQB/MLBevo): Drehfalle Heckdeckel
sonst (MQB): Hauptraste Heckdeckel";
CM_ SG_ 1411 HD_Vorraste "SBL_Schloss (MQB/MLBevo): Sperrklinke Heckdeckel
sonst (MQB): Vorraste Heckdeckel";
CM_ SG_ 1411 FFB_HDF_Taste "HDF Taste am Funkschluessel
";
CM_ SG_ 1411 FFB_Panik_Taste "Panik Taste Funkschluessel
";
CM_ SG_ 1411 FFB_Auf_Taste "Auf-Taste Funkschluessel

";
CM_ SG_ 1411 FFB_Zu_Taste "Zu-Taste Funkschluessel
";
CM_ SG_ 1411 FFB_CarFinder "Car Finder Funktion (Blinken ohne zu entriegeln)";
CM_ SG_ 1411 FFB_Komfortoeffnen "Komfortoeffnen Funk
";
CM_ SG_ 1411 FFB_Komfortschliessen "Komfortschliessen Funk
";
CM_ SG_ 1411 FBS_IDG_in_Reichweite "Für elektrisch betätigte Türen und Klappen muss für eine Betätigung über Funk eine Reichweitenbegrenzung eingeführt werden. Diese Bit zeigt an, dass sich der Funkschlüssel innerhalb der geforderten Reichweite befindet";
CM_ SG_ 1411 ZV_Schluessel_Zugang "aktuelle Funkschlüsselnummer";
CM_ SG_ 1411 ZV_SafeFunktion_aktiv "Statusübermittlung ob die Safe Funktion im Fzg. aktiv ist. Das Kombi benötigt das Signal, um den Text Safelock aktiv anzuzeigen. ";
CM_ SG_ 1411 FBS_Warn_Schluessel_Batt "Kombi Prio Warnung Schluessel Batterie
'Bitte Schlüsselbatterie wechseln!'";
CM_ SG_ 1411 ZV_Oeffnungsmodus "Konfigurierter Oeffnungsmodus fuer ZV:
0 = globale Oeffnung (alle Tueren)
1 = ZV mit Einzeltuerentriegelung (FFB - nur Fahrertuer, Kessy - nur bediente Tuer)
2 = ZV individuell selektive Oeffnung (FFB - Fahrerseite, Kessy - bediente Tuer + Fahrertuer)";
CM_ SG_ 1411 HFS_verriegelt "HFS Tuer verriegelt";
CM_ SG_ 1411 HFS_gesafet "HFS Tuer gesafet.
Im Zustand Safe wird auch das Signal HFS_verriegelt = 1 gesendet.";
CM_ SG_ 1411 HBFS_verriegelt "Verriegelungsstatus Tür";
CM_ SG_ 1411 HBFS_gesafet "HBFS Tuer gesafet.
Im Zustand Safe wird auch das Signal HBFS_verriegelt = 1 gesendet.";
CM_ SG_ 1411 ZV_ist_Zustand_verfuegbar "Verfügbarkeit IST-Zustand ZV

";
CM_ SG_ 1411 IRUE_Taster_Fkts_LED "Anforderung Funktions-LED IRUE-Taster (LED wird vom TSG angesteuert)
MQB: Bei Verbau eines einzelnen Taster zur Deaktivierung von IRUE und NGS wird dieses Signal zur Ansteuerung der Funktions-LED gesendet.";
CM_ SG_ 1411 ZV_Tankklappe_offen "Öffnungsstatus der Tankklappe";
CM_ SG_ 1411 ZV_Rollo_auf "Komfortöffnen des Dachrollos";
CM_ SG_ 1411 ZV_Rollo_zu "Komfortschließen des Dachrollos";
CM_ SG_ 1411 ZV_SAD_auf "Komfortöffnen des Schiebeausstelldaches";
CM_ SG_ 1411 ZV_SAD_zu "Komfortschließen des Schiebeausstelldaches";
CM_ SG_ 1411 BCM_Tankklappensteller_Fehler "Fehler: nicht Funktionalität des Tankklappenstellers";
BA_DEF_ BO_  "DiagRequest" ENUM  "No","Yes";
BA_DEF_ BO_  "DiagResponse" ENUM  "No","Yes";
BA_DEF_ BO_  "DiagState" ENUM  "No","Yes";
BA_DEF_ BO_  "GenMsgChkConstant" HEX 0 4095;
BA_DEF_ BO_  "GenMsgCycleTime" INT 0 65535;
BA_DEF_ BO_  "GenMsgCycleTimeFast" INT 0 65535;
BA_DEF_ BO_  "GenMsgDelayTime" INT 0 100000;
BA_DEF_ BO_  "GenMsgILSupport" ENUM  "No","Yes";
BA_DEF_ BO_  "GenMsgNrOfRepetition" INT 0 100;
BA_DEF_ BO_  "GenMsgPDUConstants" STRING ;
BA_DEF_ BO_  "GenMsgSendType" ENUM  "Cyclic","not_used","not_used","not_used","not_used","not_used","not_used","IfActive","NoMsgSendType";
BA_DEF_ BO_  "GenMsgStartDelayTime" INT 0 100000;
BA_DEF_ BO_  "NmMessage" ENUM  "No","Yes";
BA_DEF_ BO_  "NmhMessage" ENUM  "No","Yes";
BA_DEF_ BO_  "MsgType" ENUM  "Application","NM ","NMH","TP2.0","ISO-TP ","BAP","EID";
BA_DEF_ BO_  "VAGTP20_API" HEX 0 255;
BA_DEF_ BO_  "VAGTP20_DynConnection" ENUM  "No","Yes";
BA_DEF_ BO_  "VAGTP20_DynSetup" ENUM  "No","Yes";
BA_DEF_ BO_  "VAGTP20_StatConnection" ENUM  "No","Yes";
BA_DEF_ SG_  "GenSigActiveRepetitions" INT -2147483648 2147483647;
BA_DEF_ SG_  "GenSigInactiveValue" INT -2147483648 2147483647;
BA_DEF_ SG_  "GenSigSendType" ENUM  "Cyclic","OnWrite","OnWriteWithRepetition","OnChange","OnChangeWithRepetition","IfActive","IfActiveWithRepetition","NoSigSendType","OnChangeAndIfActive","OnChangeAndIfActiveWithRepetition";
BA_DEF_ SG_  "GenSigStartValue" INT -2147483648 2147483647;
BA_DEF_ SG_  "NWM-WakeupAllowed" ENUM  "No","Yes";
BA_DEF_ SG_  "GenSigFuncType" ENUM  "NoFunction","MsgCounter","CRC-8","XOR","XOR-2","DatedBit","SW-Kl15","CHK","Constant","Protocol","CRC-8-SAE_J1850";
BA_DEF_ SG_  "GenSigSwitchedByIgnition" ENUM  "No","Yes";
BA_DEF_ SG_  "Fehlerwert" HEX 0 2147483647;
BA_DEF_ SG_  "GenSigMissingSourceValue" HEX 0 2147483647;
BA_DEF_REL_ BU_SG_REL_  "GenSigTimeoutTime" INT 0 65535;
BA_DEF_DEF_  "DiagRequest" "No";
BA_DEF_DEF_  "DiagResponse" "No";
BA_DEF_DEF_  "DiagState" "No";
BA_DEF_DEF_  "GenMsgChkConstant" 0;
BA_DEF_DEF_  "GenMsgCycleTime" 0;
BA_DEF_DEF_  "GenMsgCycleTimeFast" 0;
BA_DEF_DEF_  "GenMsgDelayTime" 0;
BA_DEF_DEF_  "GenMsgILSupport" "No";
BA_DEF_DEF_  "GenMsgNrOfRepetition" 0;
BA_DEF_DEF_  "GenMsgPDUConstants" "";
BA_DEF_DEF_  "GenMsgSendType" "NoMsgSendType";
BA_DEF_DEF_  "GenMsgStartDelayTime" 0;
BA_DEF_DEF_  "NmMessage" "No";
BA_DEF_DEF_  "NmhMessage" "No";
BA_DEF_DEF_  "MsgType" "Application";
BA_DEF_DEF_  "VAGTP20_API" 0;
BA_DEF_DEF_  "VAGTP20_DynConnection" "No";
BA_DEF_DEF_  "VAGTP20_DynSetup" "No";
BA_DEF_DEF_  "VAGTP20_StatConnection" "No";
BA_DEF_DEF_  "GenSigActiveRepetitions" 0;
BA_DEF_DEF_  "GenSigInactiveValue" 0;
BA_DEF_DEF_  "GenSigSendType" "NoSigSendType";
BA_DEF_DEF_  "GenSigStartValue" 0;
BA_DEF_DEF_  "NWM-WakeupAllowed" "No";
BA_DEF_DEF_  "GenSigFuncType" "NoFunction";
BA_DEF_DEF_  "GenSigSwitchedByIgnition" "Yes";
BA_DEF_DEF_  "Fehlerwert" 0;
BA_DEF_DEF_  "GenSigMissingSourceValue" 0;
BA_DEF_DEF_REL_ "GenSigTimeoutTime" 0;
BA_ "GenMsgSendType" BO_ 975 0;
BA_ "GenMsgILSupport" BO_ 975 1;
BA_ "GenMsgDelayTime" BO_ 975 20;
BA_ "GenMsgCycleTime" BO_ 975 100;
BA_ "GenMsgSendType" BO_ 1457 0;
BA_ "GenMsgILSupport" BO_ 1457 1;
BA_ "GenMsgDelayTime" BO_ 1457 100;
BA_ "GenMsgCycleTime" BO_ 1457 1000;
BA_ "GenMsgSendType" BO_ 974 0;
BA_ "GenMsgILSupport" BO_ 974 1;
BA_ "GenMsgDelayTime" BO_ 974 20;
BA_ "GenMsgCycleTime" BO_ 974 100;
BA_ "GenMsgSendType" BO_ 1458 0;
BA_ "GenMsgILSupport" BO_ 1458 1;
BA_ "GenMsgDelayTime" BO_ 1458 100;
BA_ "GenMsgCycleTime" BO_ 1458 1000;
BA_ "GenMsgSendType" BO_ 346 0;
BA_ "GenMsgPDUConstants" BO_ 346 "0xcf,0x1a,0x84,0x28,0x05,0xcb,0xb3,0x98,0x82,0x53,0xbe,0xa1,0x4a,0x6d,0x41,0xae";
BA_ "GenMsgILSupport" BO_ 346 1;
BA_ "GenMsgDelayTime" BO_ 346 20;
BA_ "GenMsgCycleTime" BO_ 346 100;
BA_ "GenMsgSendType" BO_ 995 0;
BA_ "GenMsgNrOfRepetition" BO_ 995 5;
BA_ "GenMsgILSupport" BO_ 995 1;
BA_ "GenMsgDelayTime" BO_ 995 50;
BA_ "GenMsgCycleTimeFast" BO_ 995 50;
BA_ "GenMsgCycleTime" BO_ 995 100;
BA_ "GenMsgSendType" BO_ 1716 0;
BA_ "GenMsgILSupport" BO_ 1716 1;
BA_ "GenMsgCycleTime" BO_ 1716 200;
BA_ "GenMsgSendType" BO_ 1361 0;
BA_ "GenMsgILSupport" BO_ 1361 1;
BA_ "GenMsgDelayTime" BO_ 1361 50;
BA_ "GenMsgCycleTime" BO_ 1361 200;
BA_ "GenMsgSendType" BO_ 1702 0;
BA_ "GenMsgNrOfRepetition" BO_ 1702 3;
BA_ "GenMsgILSupport" BO_ 1702 1;
BA_ "GenMsgDelayTime" BO_ 1702 50;
BA_ "GenMsgCycleTimeFast" BO_ 1702 100;
BA_ "GenMsgCycleTime" BO_ 1702 500;
BA_ "GenMsgSendType" BO_ 2527679496 0;
BA_ "GenMsgILSupport" BO_ 2527679496 1;
BA_ "GenMsgCycleTime" BO_ 2527679496 320;
BA_ "MsgType" BO_ 2617130496 6;
BA_ "MsgType" BO_ 2617130497 6;
BA_ "MsgType" BO_ 2617013760 6;
BA_ "MsgType" BO_ 2617013761 6;
BA_ "MsgType" BO_ 2617007872 6;
BA_ "MsgType" BO_ 2617007873 6;
BA_ "MsgType" BO_ 2617085440 6;
BA_ "MsgType" BO_ 2617085441 6;
BA_ "MsgType" BO_ 2617056768 6;
BA_ "MsgType" BO_ 2617056769 6;
BA_ "MsgType" BO_ 2617075200 6;
BA_ "MsgType" BO_ 2617075201 6;
BA_ "MsgType" BO_ 2617050880 6;
BA_ "MsgType" BO_ 2617050881 6;
BA_ "MsgType" BO_ 2616993536 6;
BA_ "MsgType" BO_ 2616993537 6;
BA_ "MsgType" BO_ 2617040640 6;
BA_ "MsgType" BO_ 2617040641 6;
BA_ "MsgType" BO_ 2617142784 6;
BA_ "MsgType" BO_ 2617142785 6;
BA_ "MsgType" BO_ 2617140736 6;
BA_ "MsgType" BO_ 2617140737 6;
BA_ "MsgType" BO_ 2617001728 6;
BA_ "MsgType" BO_ 2617001729 6;
BA_ "MsgType" BO_ 2616999680 6;
BA_ "MsgType" BO_ 2616999681 6;
BA_ "MsgType" BO_ 2617028352 6;
BA_ "MsgType" BO_ 2617028353 6;
BA_ "MsgType" BO_ 2617058816 6;
BA_ "MsgType" BO_ 2617058817 6;
BA_ "MsgType" BO_ 2617073152 6;
BA_ "MsgType" BO_ 2617073153 6;
BA_ "MsgType" BO_ 2617138688 6;
BA_ "MsgType" BO_ 2617138689 6;
BA_ "MsgType" BO_ 2617136640 6;
BA_ "MsgType" BO_ 2617136641 6;
BA_ "MsgType" BO_ 2566802688 6;
BA_ "MsgType" BO_ 2566802689 6;
BA_ "MsgType" BO_ 2566802432 6;
BA_ "MsgType" BO_ 2566802433 6;
BA_ "MsgType" BO_ 2617077248 6;
BA_ "MsgType" BO_ 2617077249 6;
BA_ "GenMsgSendType" BO_ 389 7;
BA_ "GenMsgNrOfRepetition" BO_ 389 5;
BA_ "GenMsgILSupport" BO_ 389 1;
BA_ "GenMsgDelayTime" BO_ 389 10;
BA_ "GenMsgCycleTimeFast" BO_ 389 40;
BA_ "GenMsgSendType" BO_ 392 7;
BA_ "GenMsgNrOfRepetition" BO_ 392 5;
BA_ "GenMsgILSupport" BO_ 392 1;
BA_ "GenMsgDelayTime" BO_ 392 10;
BA_ "GenMsgCycleTimeFast" BO_ 392 40;
BA_ "GenMsgSendType" BO_ 388 0;
BA_ "GenMsgPDUConstants" BO_ 388 "0xe3,0xe8,0xc4,0x7f,0xf1,0x95,0xd8,0xb0,0xc7,0xa3,0xf4,0x6c,0xe7,0xc3,0x5a,0xf7";
BA_ "GenMsgNrOfRepetition" BO_ 388 5;
BA_ "GenMsgILSupport" BO_ 388 1;
BA_ "GenMsgCycleTimeFast" BO_ 388 20;
BA_ "GenMsgCycleTime" BO_ 388 1000;
BA_ "GenMsgSendType" BO_ 1411 0;
BA_ "GenMsgNrOfRepetition" BO_ 1411 3;
BA_ "GenMsgILSupport" BO_ 1411 1;
BA_ "GenMsgDelayTime" BO_ 1411 50;
BA_ "GenMsgCycleTimeFast" BO_ 1411 50;
BA_ "GenMsgCycleTime" BO_ 1411 200;
BA_ "GenSigSwitchedByIgnition" SG_ 975 HBFS_Tuer_geoeffnet 0;
BA_ "GenSigSendType" SG_ 975 HBFS_Tuer_geoeffnet 3;
BA_ "GenSigSwitchedByIgnition" SG_ 975 HBFS_verriegelt 0;
BA_ "GenSigSendType" SG_ 975 HBFS_verriegelt 3;
BA_ "GenSigSwitchedByIgnition" SG_ 975 HBFS_gesafet 0;
BA_ "GenSigSendType" SG_ 975 HBFS_gesafet 3;
BA_ "GenSigSwitchedByIgnition" SG_ 975 HBFS_Heckrollotaster_betaetigt 0;
BA_ "GenSigSendType" SG_ 975 HBFS_Heckrollotaster_betaetigt 3;
BA_ "GenSigSwitchedByIgnition" SG_ 975 HBFS_Tuerschloss_defekt 0;
BA_ "GenSigSendType" SG_ 975 HBFS_Tuerschloss_defekt 0;
BA_ "GenSigSwitchedByIgnition" SG_ 975 HBFS_Unlock_Taster 0;
BA_ "GenSigSendType" SG_ 975 HBFS_Unlock_Taster 3;
BA_ "GenSigSwitchedByIgnition" SG_ 975 HBFS_Lock_Taster 0;
BA_ "GenSigSendType" SG_ 975 HBFS_Lock_Taster 3;
BA_ "GenSigSwitchedByIgnition" SG_ 975 HBFS_Sperrklinke 0;
BA_ "GenSigSendType" SG_ 975 HBFS_Sperrklinke 3;
BA_ "GenSigSwitchedByIgnition" SG_ 975 HBFS_TAG_betaetigt 0;
BA_ "GenSigSendType" SG_ 975 HBFS_TAG_betaetigt 3;
BA_ "GenSigSwitchedByIgnition" SG_ 975 HBFS_TIG_betaetigt 0;
BA_ "GenSigSendType" SG_ 975 HBFS_TIG_betaetigt 3;
BA_ "GenSigSwitchedByIgnition" SG_ 975 HBFS_FH_S_HFS_AutoHoch 0;
BA_ "GenSigSendType" SG_ 975 HBFS_FH_S_HFS_AutoHoch 3;
BA_ "GenSigSwitchedByIgnition" SG_ 975 HBFS_FH_S_HFS_AutoTief 0;
BA_ "GenSigSendType" SG_ 975 HBFS_FH_S_HFS_AutoTief 3;
BA_ "GenSigSwitchedByIgnition" SG_ 975 HBFS_FH_S_HFS_ManHoch 0;
BA_ "GenSigSendType" SG_ 975 HBFS_FH_S_HFS_ManHoch 3;
BA_ "GenSigSwitchedByIgnition" SG_ 975 HBFS_FH_S_HFS_ManTief 0;
BA_ "GenSigSendType" SG_ 975 HBFS_FH_S_HFS_ManTief 3;
BA_ "Fehlerwert" SG_ 975 HBFS_Tuer_Status 3;
BA_ "GenSigSwitchedByIgnition" SG_ 975 HBFS_Tuer_Status 0;
BA_ "GenSigSendType" SG_ 975 HBFS_Tuer_Status 3;
BA_ "Fehlerwert" SG_ 975 HBFS_SAD_Schalter 15;
BA_ "GenSigSwitchedByIgnition" SG_ 975 HBFS_SAD_Schalter 0;
BA_ "GenSigStartValue" SG_ 975 HBFS_SAD_Schalter 14;
BA_ "GenSigSendType" SG_ 975 HBFS_SAD_Schalter 3;
BA_ "GenSigSwitchedByIgnition" SG_ 975 HBFS_FH_S_ManHoch 0;
BA_ "GenSigSendType" SG_ 975 HBFS_FH_S_ManHoch 3;
BA_ "GenSigSwitchedByIgnition" SG_ 975 HBFS_FH_S_AutoHoch 0;
BA_ "GenSigSendType" SG_ 975 HBFS_FH_S_AutoHoch 3;
BA_ "GenSigSwitchedByIgnition" SG_ 975 HBFS_FH_S_ManTief 0;
BA_ "GenSigSendType" SG_ 975 HBFS_FH_S_ManTief 3;
BA_ "GenSigSwitchedByIgnition" SG_ 975 HBFS_FH_S_AutoTief 0;
BA_ "GenSigSendType" SG_ 975 HBFS_FH_S_AutoTief 3;
BA_ "GenSigSwitchedByIgnition" SG_ 975 HBFS_FH_Oeffnung 0;
BA_ "GenSigSendType" SG_ 975 HBFS_FH_Oeffnung 3;
BA_ "GenSigSwitchedByIgnition" SG_ 975 HBFS_FH_Bew_hoch 0;
BA_ "GenSigSendType" SG_ 975 HBFS_FH_Bew_hoch 3;
BA_ "GenSigSwitchedByIgnition" SG_ 975 HBFS_FH_Bew_tief 0;
BA_ "GenSigSendType" SG_ 975 HBFS_FH_Bew_tief 3;
BA_ "GenSigSwitchedByIgnition" SG_ 975 HBFS_FH_Fang 0;
BA_ "GenSigSendType" SG_ 975 HBFS_FH_Fang 3;
BA_ "GenSigSwitchedByIgnition" SG_ 975 HBFS_FH_Block 0;
BA_ "GenSigSendType" SG_ 975 HBFS_FH_Block 3;
BA_ "GenSigSwitchedByIgnition" SG_ 975 HBFS_FH_Thermo 0;
BA_ "GenSigSendType" SG_ 975 HBFS_FH_Thermo 3;
BA_ "GenSigSwitchedByIgnition" SG_ 975 HBFS_UEKB_aktiviert 0;
BA_ "GenSigSendType" SG_ 975 HBFS_UEKB_aktiviert 3;
BA_ "GenSigSwitchedByIgnition" SG_ 975 HBFS_Tuerschloss_verrieg_nicht 0;
BA_ "GenSigSendType" SG_ 975 HBFS_Tuerschloss_verrieg_nicht 0;
BA_ "GenSigSwitchedByIgnition" SG_ 975 HBFS_FH_normiert 0;
BA_ "GenSigSendType" SG_ 975 HBFS_FH_normiert 3;
BA_ "GenSigSwitchedByIgnition" SG_ 975 ASW_Warnung_aktiv_HBFS 0;
BA_ "GenSigSendType" SG_ 975 ASW_Warnung_aktiv_HBFS 3;
BA_ "GenSigSwitchedByIgnition" SG_ 975 HBFS_Zuziehhilfe_aktiv 0;
BA_ "GenSigSendType" SG_ 975 HBFS_Zuziehhilfe_aktiv 3;
BA_ "GenSigSwitchedByIgnition" SG_ 975 HBFS_Seitenrollo_hoch 0;
BA_ "GenSigSendType" SG_ 975 HBFS_Seitenrollo_hoch 3;
BA_ "GenSigSwitchedByIgnition" SG_ 975 HBFS_Seitenrollo_tief 0;
BA_ "GenSigSendType" SG_ 975 HBFS_Seitenrollo_tief 3;
BA_ "GenSigSwitchedByIgnition" SG_ 975 HBFS_Status_KiSi 0;
BA_ "GenSigSendType" SG_ 975 HBFS_Status_KiSi 3;
BA_ "GenSigSwitchedByIgnition" SG_ 975 SSR_HBFS_Pos_Unten 0;
BA_ "GenSigSendType" SG_ 975 SSR_HBFS_Pos_Unten 0;
BA_ "GenSigSwitchedByIgnition" SG_ 975 HBFS_Oben_Block_erw 0;
BA_ "GenSigSendType" SG_ 975 HBFS_Oben_Block_erw 3;
BA_ "GenSigSwitchedByIgnition" SG_ 975 HBFS_Unten_Block_erw 0;
BA_ "GenSigSendType" SG_ 975 HBFS_Unten_Block_erw 3;
BA_ "GenSigSwitchedByIgnition" SG_ 975 MTHBFS_M_Taste 0;
BA_ "GenSigSendType" SG_ 975 MTHBFS_M_Taste 3;
BA_ "GenSigSwitchedByIgnition" SG_ 975 MTHBFS_Pos1 0;
BA_ "GenSigSendType" SG_ 975 MTHBFS_Pos1 3;
BA_ "GenSigSwitchedByIgnition" SG_ 975 MTHBFS_Pos2 0;
BA_ "GenSigSendType" SG_ 975 MTHBFS_Pos2 3;
BA_ "GenSigSwitchedByIgnition" SG_ 975 MTHBFS_Pos3 0;
BA_ "GenSigSendType" SG_ 975 MTHBFS_Pos3 3;
BA_ "Fehlerwert" SG_ 975 HBFS_MRollo_Schalter 7;
BA_ "GenSigSwitchedByIgnition" SG_ 975 HBFS_MRollo_Schalter 0;
BA_ "GenSigStartValue" SG_ 975 HBFS_MRollo_Schalter 6;
BA_ "GenSigSendType" SG_ 975 HBFS_MRollo_Schalter 3;
BA_ "GenSigSwitchedByIgnition" SG_ 975 HBFS_Lock_Taster_inv 0;
BA_ "GenSigSendType" SG_ 975 HBFS_Lock_Taster_inv 3;
BA_ "GenSigSwitchedByIgnition" SG_ 975 HBFS_Status_KiSi_inv 0;
BA_ "GenSigStartValue" SG_ 975 HBFS_Status_KiSi_inv 1;
BA_ "GenSigSendType" SG_ 975 HBFS_Status_KiSi_inv 0;
BA_ "GenSigSwitchedByIgnition" SG_ 1457 TSG_FlHz_HBFS_NTC_A 0;
BA_ "GenSigStartValue" SG_ 1457 TSG_FlHz_HBFS_NTC_A 127;
BA_ "GenSigSendType" SG_ 1457 TSG_FlHz_HBFS_NTC_A 3;
BA_ "GenSigSwitchedByIgnition" SG_ 1457 TSG_FlHz_HBFS_FnAbbruchHzKreis_A 0;
BA_ "GenSigSendType" SG_ 1457 TSG_FlHz_HBFS_FnAbbruchHzKreis_A 3;
BA_ "GenSigSwitchedByIgnition" SG_ 1457 TSG_FlHz_HBFS_NTC_B 0;
BA_ "GenSigStartValue" SG_ 1457 TSG_FlHz_HBFS_NTC_B 127;
BA_ "GenSigSendType" SG_ 1457 TSG_FlHz_HBFS_NTC_B 3;
BA_ "GenSigSwitchedByIgnition" SG_ 1457 TSG_FlHz_HBFS_FnAbbruchHzKreis_B 0;
BA_ "GenSigSendType" SG_ 1457 TSG_FlHz_HBFS_FnAbbruchHzKreis_B 3;
BA_ "GenSigSwitchedByIgnition" SG_ 974 HFS_Tuer_geoeffnet 0;
BA_ "GenSigSendType" SG_ 974 HFS_Tuer_geoeffnet 3;
BA_ "GenSigSwitchedByIgnition" SG_ 974 HFS_verriegelt 0;
BA_ "GenSigSendType" SG_ 974 HFS_verriegelt 3;
BA_ "GenSigSwitchedByIgnition" SG_ 974 HFS_gesafet 0;
BA_ "GenSigSendType" SG_ 974 HFS_gesafet 3;
BA_ "GenSigSwitchedByIgnition" SG_ 974 HFS_Heckrollotaster_betaetigt 0;
BA_ "GenSigSendType" SG_ 974 HFS_Heckrollotaster_betaetigt 3;
BA_ "GenSigSwitchedByIgnition" SG_ 974 HFS_Tuerschloss_defekt 0;
BA_ "GenSigSendType" SG_ 974 HFS_Tuerschloss_defekt 0;
BA_ "GenSigSwitchedByIgnition" SG_ 974 HFS_Unlock_Taster 0;
BA_ "GenSigSendType" SG_ 974 HFS_Unlock_Taster 3;
BA_ "GenSigSwitchedByIgnition" SG_ 974 HFS_Lock_Taster 0;
BA_ "GenSigSendType" SG_ 974 HFS_Lock_Taster 3;
BA_ "GenSigSwitchedByIgnition" SG_ 974 HFS_Sperrklinke 0;
BA_ "GenSigSendType" SG_ 974 HFS_Sperrklinke 3;
BA_ "GenSigSwitchedByIgnition" SG_ 974 HFS_TAG_betaetigt 0;
BA_ "GenSigSendType" SG_ 974 HFS_TAG_betaetigt 3;
BA_ "GenSigSwitchedByIgnition" SG_ 974 HFS_TIG_betaetigt 0;
BA_ "GenSigSendType" SG_ 974 HFS_TIG_betaetigt 3;
BA_ "GenSigSwitchedByIgnition" SG_ 974 HFS_FH_S_HBFS_AutoHoch 0;
BA_ "GenSigSendType" SG_ 974 HFS_FH_S_HBFS_AutoHoch 3;
BA_ "GenSigSwitchedByIgnition" SG_ 974 HFS_FH_S_HBFS_AutoTief 0;
BA_ "GenSigSendType" SG_ 974 HFS_FH_S_HBFS_AutoTief 3;
BA_ "GenSigSwitchedByIgnition" SG_ 974 HFS_FH_S_HBFS_ManHoch 0;
BA_ "GenSigSendType" SG_ 974 HFS_FH_S_HBFS_ManHoch 3;
BA_ "GenSigSwitchedByIgnition" SG_ 974 HFS_FH_S_HBFS_ManTief 0;
BA_ "GenSigSendType" SG_ 974 HFS_FH_S_HBFS_ManTief 3;
BA_ "Fehlerwert" SG_ 974 HFS_Tuer_Status 3;
BA_ "GenSigSwitchedByIgnition" SG_ 974 HFS_Tuer_Status 0;
BA_ "GenSigSendType" SG_ 974 HFS_Tuer_Status 3;
BA_ "Fehlerwert" SG_ 974 HFS_SAD_Schalter 15;
BA_ "GenSigSwitchedByIgnition" SG_ 974 HFS_SAD_Schalter 0;
BA_ "GenSigStartValue" SG_ 974 HFS_SAD_Schalter 14;
BA_ "GenSigSendType" SG_ 974 HFS_SAD_Schalter 3;
BA_ "GenSigSwitchedByIgnition" SG_ 974 HFS_FH_S_ManHoch 0;
BA_ "GenSigSendType" SG_ 974 HFS_FH_S_ManHoch 3;
BA_ "GenSigSwitchedByIgnition" SG_ 974 HFS_FH_S_AutoHoch 0;
BA_ "GenSigSendType" SG_ 974 HFS_FH_S_AutoHoch 3;
BA_ "GenSigSwitchedByIgnition" SG_ 974 HFS_FH_S_ManTief 0;
BA_ "GenSigSendType" SG_ 974 HFS_FH_S_ManTief 3;
BA_ "GenSigSwitchedByIgnition" SG_ 974 HFS_FH_S_AutoTief 0;
BA_ "GenSigSendType" SG_ 974 HFS_FH_S_AutoTief 3;
BA_ "GenSigSwitchedByIgnition" SG_ 974 HFS_FH_Oeffnung 0;
BA_ "GenSigSendType" SG_ 974 HFS_FH_Oeffnung 3;
BA_ "GenSigSwitchedByIgnition" SG_ 974 HFS_FH_Bew_hoch 0;
BA_ "GenSigSendType" SG_ 974 HFS_FH_Bew_hoch 3;
BA_ "GenSigSwitchedByIgnition" SG_ 974 HFS_FH_Bew_tief 0;
BA_ "GenSigSendType" SG_ 974 HFS_FH_Bew_tief 3;
BA_ "GenSigSwitchedByIgnition" SG_ 974 HFS_FH_Fang 0;
BA_ "GenSigSendType" SG_ 974 HFS_FH_Fang 3;
BA_ "GenSigSwitchedByIgnition" SG_ 974 HFS_FH_Block 0;
BA_ "GenSigSendType" SG_ 974 HFS_FH_Block 3;
BA_ "GenSigSwitchedByIgnition" SG_ 974 HFS_FH_Thermo 0;
BA_ "GenSigSendType" SG_ 974 HFS_FH_Thermo 3;
BA_ "GenSigSwitchedByIgnition" SG_ 974 HFS_UEKB_aktiviert 0;
BA_ "GenSigSendType" SG_ 974 HFS_UEKB_aktiviert 3;
BA_ "GenSigSwitchedByIgnition" SG_ 974 HFS_Tuerschloss_verrieg_nicht 0;
BA_ "GenSigSendType" SG_ 974 HFS_Tuerschloss_verrieg_nicht 0;
BA_ "GenSigSwitchedByIgnition" SG_ 974 HFS_FH_normiert 0;
BA_ "GenSigSendType" SG_ 974 HFS_FH_normiert 3;
BA_ "GenSigSwitchedByIgnition" SG_ 974 ASW_Warnung_aktiv_HFS 0;
BA_ "GenSigSendType" SG_ 974 ASW_Warnung_aktiv_HFS 3;
BA_ "GenSigSwitchedByIgnition" SG_ 974 HFS_Zuziehhilfe_aktiv 0;
BA_ "GenSigSendType" SG_ 974 HFS_Zuziehhilfe_aktiv 3;
BA_ "GenSigSwitchedByIgnition" SG_ 974 HFS_Seitenrollo_hoch 0;
BA_ "GenSigSendType" SG_ 974 HFS_Seitenrollo_hoch 3;
BA_ "GenSigSwitchedByIgnition" SG_ 974 HFS_Seitenrollo_tief 0;
BA_ "GenSigSendType" SG_ 974 HFS_Seitenrollo_tief 3;
BA_ "GenSigSwitchedByIgnition" SG_ 974 HFS_Status_KiSi 0;
BA_ "GenSigSendType" SG_ 974 HFS_Status_KiSi 3;
BA_ "GenSigSwitchedByIgnition" SG_ 974 SSR_HFS_Pos_Unten 0;
BA_ "GenSigSendType" SG_ 974 SSR_HFS_Pos_Unten 0;
BA_ "GenSigSwitchedByIgnition" SG_ 974 HFS_Oben_Block_erw 0;
BA_ "GenSigSendType" SG_ 974 HFS_Oben_Block_erw 3;
BA_ "GenSigSwitchedByIgnition" SG_ 974 HFS_Unten_Block_erw 0;
BA_ "GenSigSendType" SG_ 974 HFS_Unten_Block_erw 3;
BA_ "GenSigSwitchedByIgnition" SG_ 974 MTHFS_M_Taste 0;
BA_ "GenSigSendType" SG_ 974 MTHFS_M_Taste 3;
BA_ "GenSigSwitchedByIgnition" SG_ 974 MTHFS_Pos1 0;
BA_ "GenSigSendType" SG_ 974 MTHFS_Pos1 3;
BA_ "GenSigSwitchedByIgnition" SG_ 974 MTHFS_Pos2 0;
BA_ "GenSigSendType" SG_ 974 MTHFS_Pos2 3;
BA_ "GenSigSwitchedByIgnition" SG_ 974 MTHFS_Pos3 0;
BA_ "GenSigSendType" SG_ 974 MTHFS_Pos3 3;
BA_ "Fehlerwert" SG_ 974 HFS_MRollo_Schalter 7;
BA_ "GenSigSwitchedByIgnition" SG_ 974 HFS_MRollo_Schalter 0;
BA_ "GenSigStartValue" SG_ 974 HFS_MRollo_Schalter 6;
BA_ "GenSigSendType" SG_ 974 HFS_MRollo_Schalter 3;
BA_ "GenSigSwitchedByIgnition" SG_ 974 HFS_Lock_Taster_inv 0;
BA_ "GenSigSendType" SG_ 974 HFS_Lock_Taster_inv 3;
BA_ "GenSigSwitchedByIgnition" SG_ 1458 TSG_FlHz_HFS_NTC_A 0;
BA_ "GenSigStartValue" SG_ 1458 TSG_FlHz_HFS_NTC_A 127;
BA_ "GenSigSendType" SG_ 1458 TSG_FlHz_HFS_NTC_A 3;
BA_ "GenSigSwitchedByIgnition" SG_ 1458 TSG_FlHz_HFS_FnAbbruchHzKreis_A 0;
BA_ "GenSigSendType" SG_ 1458 TSG_FlHz_HFS_FnAbbruchHzKreis_A 3;
BA_ "GenSigSwitchedByIgnition" SG_ 1458 TSG_FlHz_HFS_NTC_B 0;
BA_ "GenSigStartValue" SG_ 1458 TSG_FlHz_HFS_NTC_B 127;
BA_ "GenSigSendType" SG_ 1458 TSG_FlHz_HFS_NTC_B 3;
BA_ "GenSigSwitchedByIgnition" SG_ 1458 TSG_FlHz_HFS_FnAbbruchHzKreis_B 0;
BA_ "GenSigSendType" SG_ 1458 TSG_FlHz_HFS_FnAbbruchHzKreis_B 3;
BA_ "GenSigSwitchedByIgnition" SG_ 346 TSK_08_CRC 0;
BA_ "GenSigFuncType" SG_ 346 TSK_08_CRC 2;
BA_ "GenSigSendType" SG_ 346 TSK_08_CRC 0;
BA_ "GenSigSwitchedByIgnition" SG_ 346 TSK_08_BZ 0;
BA_ "GenSigFuncType" SG_ 346 TSK_08_BZ 1;
BA_ "GenSigSendType" SG_ 346 TSK_08_BZ 0;
BA_ "GenSigSwitchedByIgnition" SG_ 346 MO_Anforderung_HMS 0;
BA_ "GenSigSendType" SG_ 346 MO_Anforderung_HMS 3;
BA_ "GenSigStartValue" SG_ 346 TSK_vMax_Fahrerassistenz 511;
BA_ "GenSigSendType" SG_ 346 TSK_vMax_Fahrerassistenz 0;
BA_ "GenSigSendType" SG_ 346 TSK_Einheit_vMax_Fahrerassistenz 0;
BA_ "Fehlerwert" SG_ 346 TSK_Status_PLA 7;
BA_ "GenSigSwitchedByIgnition" SG_ 346 TSK_Status_PLA 0;
BA_ "GenSigStartValue" SG_ 346 TSK_Status_PLA 1;
BA_ "GenSigSendType" SG_ 346 TSK_Status_PLA 3;
BA_ "GenSigSwitchedByIgnition" SG_ 346 TSK_aktives_System 0;
BA_ "GenSigSendType" SG_ 346 TSK_aktives_System 3;
BA_ "GenSigSendType" SG_ 346 TSK_erhoehter_Fahrwiderstand 3;
BA_ "Fehlerwert" SG_ 346 TSK_Status_ARA 7;
BA_ "GenSigSwitchedByIgnition" SG_ 346 TSK_Status_ARA 0;
BA_ "GenSigStartValue" SG_ 346 TSK_Status_ARA 1;
BA_ "GenSigSendType" SG_ 346 TSK_Status_ARA 3;
BA_ "Fehlerwert" SG_ 346 TSK_Status_IPA 7;
BA_ "GenSigSwitchedByIgnition" SG_ 346 TSK_Status_IPA 0;
BA_ "GenSigStartValue" SG_ 346 TSK_Status_IPA 1;
BA_ "GenSigSendType" SG_ 346 TSK_Status_IPA 3;
BA_ "GenSigSwitchedByIgnition" SG_ 995 VS_VD_zu_ver 0;
BA_ "GenSigSendType" SG_ 995 VS_VD_zu_ver 3;
BA_ "GenSigSwitchedByIgnition" SG_ 995 VS_VD_entriegelt 0;
BA_ "GenSigSendType" SG_ 995 VS_VD_entriegelt 3;
BA_ "GenSigSwitchedByIgnition" SG_ 995 VS_VD_offen_ver 0;
BA_ "GenSigSendType" SG_ 995 VS_VD_offen_ver 3;
BA_ "GenSigSwitchedByIgnition" SG_ 995 VS_VD_Zwischenposition 0;
BA_ "GenSigSendType" SG_ 995 VS_VD_Zwischenposition 3;
BA_ "GenSigSwitchedByIgnition" SG_ 995 VS_VD_Bew_auf 0;
BA_ "GenSigSendType" SG_ 995 VS_VD_Bew_auf 3;
BA_ "GenSigSwitchedByIgnition" SG_ 995 VS_VD_Bew_zu 0;
BA_ "GenSigSendType" SG_ 995 VS_VD_Bew_zu 3;
BA_ "GenSigSwitchedByIgnition" SG_ 995 VS_Verdeck_Anf 0;
BA_ "GenSigSendType" SG_ 995 VS_Verdeck_Anf 3;
BA_ "GenSigSwitchedByIgnition" SG_ 995 VS_Hardtop 0;
BA_ "GenSigSendType" SG_ 995 VS_Hardtop 3;
BA_ "GenSigSwitchedByIgnition" SG_ 995 VS_VD_Fehler 0;
BA_ "GenSigSendType" SG_ 995 VS_VD_Fehler 3;
BA_ "GenSigSwitchedByIgnition" SG_ 995 VS_Lampe_Blk 0;
BA_ "GenSigSendType" SG_ 995 VS_Lampe_Blk 3;
BA_ "GenSigSwitchedByIgnition" SG_ 995 VS_Buzzer 0;
BA_ "GenSigSendType" SG_ 995 VS_Buzzer 3;
BA_ "GenSigSwitchedByIgnition" SG_ 995 VS_HD_sperren 0;
BA_ "GenSigSendType" SG_ 995 VS_HD_sperren 3;
BA_ "GenSigSwitchedByIgnition" SG_ 995 VS_HHS_enable 0;
BA_ "GenSigSendType" SG_ 995 VS_HHS_enable 3;
BA_ "GenSigSwitchedByIgnition" SG_ 995 ZFH_FS_AutoHoch 0;
BA_ "GenSigSendType" SG_ 995 ZFH_FS_AutoHoch 4;
BA_ "GenSigSwitchedByIgnition" SG_ 995 ZFH_FS_AutoTief 0;
BA_ "GenSigSendType" SG_ 995 ZFH_FS_AutoTief 4;
BA_ "GenSigSwitchedByIgnition" SG_ 995 ZFH_FS_ManHoch 0;
BA_ "GenSigSendType" SG_ 995 ZFH_FS_ManHoch 4;
BA_ "GenSigSwitchedByIgnition" SG_ 995 ZFH_FS_ManTief 0;
BA_ "GenSigSendType" SG_ 995 ZFH_FS_ManTief 4;
BA_ "GenSigSwitchedByIgnition" SG_ 995 ZFH_BFS_AutoHoch 0;
BA_ "GenSigSendType" SG_ 995 ZFH_BFS_AutoHoch 4;
BA_ "GenSigSwitchedByIgnition" SG_ 995 ZFH_BFS_AutoTief 0;
BA_ "GenSigSendType" SG_ 995 ZFH_BFS_AutoTief 4;
BA_ "GenSigSwitchedByIgnition" SG_ 995 ZFH_BFS_ManHoch 0;
BA_ "GenSigSendType" SG_ 995 ZFH_BFS_ManHoch 4;
BA_ "GenSigSwitchedByIgnition" SG_ 995 ZFH_BFS_ManTief 0;
BA_ "GenSigSendType" SG_ 995 ZFH_BFS_ManTief 4;
BA_ "GenSigSwitchedByIgnition" SG_ 995 ZFH_HFS_AutoHoch 0;
BA_ "GenSigSendType" SG_ 995 ZFH_HFS_AutoHoch 4;
BA_ "GenSigSwitchedByIgnition" SG_ 995 ZFH_HFS_AutoTief 0;
BA_ "GenSigSendType" SG_ 995 ZFH_HFS_AutoTief 4;
BA_ "GenSigSwitchedByIgnition" SG_ 995 ZFH_HFS_ManHoch 0;
BA_ "GenSigSendType" SG_ 995 ZFH_HFS_ManHoch 4;
BA_ "GenSigSwitchedByIgnition" SG_ 995 ZFH_HFS_ManTief 0;
BA_ "GenSigSendType" SG_ 995 ZFH_HFS_ManTief 4;
BA_ "GenSigSwitchedByIgnition" SG_ 995 ZFH_HBFS_AutoHoch 0;
BA_ "GenSigSendType" SG_ 995 ZFH_HBFS_AutoHoch 4;
BA_ "GenSigSwitchedByIgnition" SG_ 995 ZFH_HBFS_AutoTief 0;
BA_ "GenSigSendType" SG_ 995 ZFH_HBFS_AutoTief 4;
BA_ "GenSigSwitchedByIgnition" SG_ 995 ZFH_HBFS_ManHoch 0;
BA_ "GenSigSendType" SG_ 995 ZFH_HBFS_ManHoch 4;
BA_ "GenSigSwitchedByIgnition" SG_ 995 ZFH_HBFS_ManTief 0;
BA_ "GenSigSendType" SG_ 995 ZFH_HBFS_ManTief 4;
BA_ "GenSigSwitchedByIgnition" SG_ 995 VS_FH_FT_Langhub 0;
BA_ "GenSigSendType" SG_ 995 VS_FH_FT_Langhub 3;
BA_ "GenSigSwitchedByIgnition" SG_ 995 VS_FH_BT_Langhub 0;
BA_ "GenSigSendType" SG_ 995 VS_FH_BT_Langhub 3;
BA_ "GenSigSwitchedByIgnition" SG_ 995 VS_FH_HFS_Langhub 0;
BA_ "GenSigSendType" SG_ 995 VS_FH_HFS_Langhub 3;
BA_ "GenSigSwitchedByIgnition" SG_ 995 VS_Heckschloss_auf 0;
BA_ "GenSigSendType" SG_ 995 VS_Heckschloss_auf 3;
BA_ "GenSigSwitchedByIgnition" SG_ 995 VS_FH_HBFS_Langhub 0;
BA_ "GenSigSendType" SG_ 995 VS_FH_HBFS_Langhub 3;
BA_ "GenSigSwitchedByIgnition" SG_ 995 VSG_Meldungen 0;
BA_ "GenSigSendType" SG_ 995 VSG_Meldungen 3;
BA_ "GenSigSwitchedByIgnition" SG_ 1716 VIN_01_MUX 0;
BA_ "GenSigSendType" SG_ 1716 VIN_01_MUX 0;
BA_ "GenSigSwitchedByIgnition" SG_ 1716 KS_Geheimnis_1 0;
BA_ "GenSigSwitchedByIgnition" SG_ 1716 VIN_4 0;
BA_ "GenSigStartValue" SG_ 1716 VIN_4 45;
BA_ "GenSigSwitchedByIgnition" SG_ 1716 VIN_11 0;
BA_ "GenSigStartValue" SG_ 1716 VIN_11 45;
BA_ "GenSigSwitchedByIgnition" SG_ 1716 KS_Geheimnis_2 0;
BA_ "GenSigSwitchedByIgnition" SG_ 1716 VIN_5 0;
BA_ "GenSigStartValue" SG_ 1716 VIN_5 45;
BA_ "GenSigSwitchedByIgnition" SG_ 1716 VIN_12 0;
BA_ "GenSigStartValue" SG_ 1716 VIN_12 45;
BA_ "GenSigSwitchedByIgnition" SG_ 1716 KS_Geheimnis_3 0;
BA_ "GenSigSwitchedByIgnition" SG_ 1716 VIN_6 0;
BA_ "GenSigStartValue" SG_ 1716 VIN_6 45;
BA_ "GenSigSwitchedByIgnition" SG_ 1716 VIN_13 0;
BA_ "GenSigStartValue" SG_ 1716 VIN_13 45;
BA_ "GenSigSwitchedByIgnition" SG_ 1716 KS_Geheimnis_4 0;
BA_ "GenSigSwitchedByIgnition" SG_ 1716 VIN_7 0;
BA_ "GenSigStartValue" SG_ 1716 VIN_7 45;
BA_ "GenSigSwitchedByIgnition" SG_ 1716 VIN_14 0;
BA_ "GenSigStartValue" SG_ 1716 VIN_14 45;
BA_ "GenSigSwitchedByIgnition" SG_ 1716 VIN_1 0;
BA_ "GenSigStartValue" SG_ 1716 VIN_1 45;
BA_ "GenSigSwitchedByIgnition" SG_ 1716 VIN_8 0;
BA_ "GenSigStartValue" SG_ 1716 VIN_8 45;
BA_ "GenSigSwitchedByIgnition" SG_ 1716 VIN_15 0;
BA_ "GenSigStartValue" SG_ 1716 VIN_15 45;
BA_ "GenSigSwitchedByIgnition" SG_ 1716 VIN_2 0;
BA_ "GenSigStartValue" SG_ 1716 VIN_2 45;
BA_ "GenSigSwitchedByIgnition" SG_ 1716 VIN_9 0;
BA_ "GenSigStartValue" SG_ 1716 VIN_9 45;
BA_ "GenSigSwitchedByIgnition" SG_ 1716 VIN_16 0;
BA_ "GenSigStartValue" SG_ 1716 VIN_16 45;
BA_ "GenSigSwitchedByIgnition" SG_ 1716 VIN_3 0;
BA_ "GenSigStartValue" SG_ 1716 VIN_3 45;
BA_ "GenSigSwitchedByIgnition" SG_ 1716 VIN_10 0;
BA_ "GenSigStartValue" SG_ 1716 VIN_10 45;
BA_ "GenSigSwitchedByIgnition" SG_ 1716 VIN_17 0;
BA_ "GenSigStartValue" SG_ 1716 VIN_17 45;
BA_ "GenSigSwitchedByIgnition" SG_ 1361 WFS_Schluessel_Fahrberecht 0;
BA_ "GenSigSendType" SG_ 1361 WFS_Schluessel_Fahrberecht 0;
BA_ "GenSigSwitchedByIgnition" SG_ 1361 WFS_ID_Geb_autorisiert 0;
BA_ "GenSigSendType" SG_ 1361 WFS_ID_Geb_autorisiert 3;
BA_ "GenSigSwitchedByIgnition" SG_ 1361 WFS_ID_Geb_autorisiert_in_Kl15 0;
BA_ "GenSigSendType" SG_ 1361 WFS_ID_Geb_autorisiert_in_Kl15 3;
BA_ "GenSigSwitchedByIgnition" SG_ 1361 WFS_ID_Geb_steckt 0;
BA_ "GenSigSendType" SG_ 1361 WFS_ID_Geb_steckt 3;
BA_ "GenSigSwitchedByIgnition" SG_ 1361 WFS_Schluessel_Soll 0;
BA_ "GenSigSendType" SG_ 1361 WFS_Schluessel_Soll 3;
BA_ "GenSigSwitchedByIgnition" SG_ 1361 WFS_Schluessel_Ist 0;
BA_ "GenSigSendType" SG_ 1361 WFS_Schluessel_Ist 3;
BA_ "GenSigSwitchedByIgnition" SG_ 1361 WFS_Safe 0;
BA_ "GenSigSendType" SG_ 1361 WFS_Safe 3;
BA_ "GenSigSwitchedByIgnition" SG_ 1361 WFS_LZ 0;
BA_ "GenSigSendType" SG_ 1361 WFS_LZ 3;
BA_ "GenSigSwitchedByIgnition" SG_ 1361 WFS_ELV_authorisiert 0;
BA_ "GenSigSendType" SG_ 1361 WFS_ELV_authorisiert 3;
BA_ "GenSigSwitchedByIgnition" SG_ 1361 WFS_LF_Aktiv 0;
BA_ "GenSigSendType" SG_ 1361 WFS_LF_Aktiv 3;
BA_ "GenSigSwitchedByIgnition" SG_ 1361 WFS_Betrieb_Lesespule 0;
BA_ "GenSigSendType" SG_ 1361 WFS_Betrieb_Lesespule 3;
BA_ "GenSigSwitchedByIgnition" SG_ 1361 WFS_Klemmenfreigabe 0;
BA_ "GenSigSendType" SG_ 1361 WFS_Klemmenfreigabe 3;
BA_ "GenSigSwitchedByIgnition" SG_ 1361 WFS_Fahrerhinweise 0;
BA_ "GenSigSendType" SG_ 1361 WFS_Fahrerhinweise 3;
BA_ "GenSigSwitchedByIgnition" SG_ 1702 Wischer_vorne_aktiv 0;
BA_ "GenSigSendType" SG_ 1702 Wischer_vorne_aktiv 3;
BA_ "GenSigSwitchedByIgnition" SG_ 1702 Waschen_vorne_aktiv 0;
BA_ "GenSigSendType" SG_ 1702 Waschen_vorne_aktiv 3;
BA_ "GenSigSwitchedByIgnition" SG_ 1702 Wischer_vorne_Normal 0;
BA_ "GenSigSendType" SG_ 1702 Wischer_vorne_Normal 3;
BA_ "GenSigSwitchedByIgnition" SG_ 1702 Wischer_vorne_Schnell 0;
BA_ "GenSigSendType" SG_ 1702 Wischer_vorne_Schnell 3;
BA_ "GenSigSwitchedByIgnition" SG_ 1702 Wischer_vorne_Parklage 0;
BA_ "GenSigStartValue" SG_ 1702 Wischer_vorne_Parklage 1;
BA_ "GenSigSendType" SG_ 1702 Wischer_vorne_Parklage 3;
BA_ "GenSigSwitchedByIgnition" SG_ 1702 Wischer_vorne_defekt 0;
BA_ "GenSigSendType" SG_ 1702 Wischer_vorne_defekt 3;
BA_ "GenSigSwitchedByIgnition" SG_ 1702 Wischer_vorne_blockiert 0;
BA_ "GenSigSendType" SG_ 1702 Wischer_vorne_blockiert 3;
BA_ "GenSigSwitchedByIgnition" SG_ 1702 Wischer1_Wischgeschwindigkeit 0;
BA_ "GenSigStartValue" SG_ 1702 Wischer1_Wischgeschwindigkeit 62;
BA_ "GenSigSendType" SG_ 1702 Wischer1_Wischgeschwindigkeit 0;
BA_ "GenSigSwitchedByIgnition" SG_ 1702 BCM1_SRA_aktiv 0;
BA_ "GenSigSendType" SG_ 1702 BCM1_SRA_aktiv 3;
BA_ "GenSigSwitchedByIgnition" SG_ 1702 Heckwischer_Anforderung 0;
BA_ "GenSigSendType" SG_ 1702 Heckwischer_Anforderung 4;
BA_ "GenSigActiveRepetitions" SG_ 1702 Heckwischer_Anforderung 3;
BA_ "GenSigSwitchedByIgnition" SG_ 1702 WWSs_01_upd 0;
BA_ "GenSigFuncType" SG_ 1702 WWSs_01_upd 5;
BA_ "GenSigSendType" SG_ 1702 WWSs_01_upd 0;
BA_ "GenSigSwitchedByIgnition" SG_ 2527679496 WIV_Verschleissindex_02 0;
BA_ "GenSigSendType" SG_ 2527679496 WIV_Verschleissindex_02 0;
BA_ "GenSigSwitchedByIgnition" SG_ 2527679496 WIV_Verschleissindex_Ueberlauf 0;
BA_ "GenSigSendType" SG_ 2527679496 WIV_Verschleissindex_Ueberlauf 0;
BA_ "GenSigSwitchedByIgnition" SG_ 2527679496 WIV_Russindex_02 0;
BA_ "GenSigSendType" SG_ 2527679496 WIV_Russindex_02 0;
BA_ "GenSigSwitchedByIgnition" SG_ 2527679496 WIV_Russindex_Ueberlauf 0;
BA_ "GenSigSendType" SG_ 2527679496 WIV_Russindex_Ueberlauf 0;
BA_ "GenSigSwitchedByIgnition" SG_ 2527679496 WIV_t_min 0;
BA_ "GenSigStartValue" SG_ 2527679496 WIV_t_min 12;
BA_ "GenSigSendType" SG_ 2527679496 WIV_t_min 0;
BA_ "GenSigSwitchedByIgnition" SG_ 2527679496 WIV_t_max 0;
BA_ "GenSigStartValue" SG_ 2527679496 WIV_t_max 24;
BA_ "GenSigSendType" SG_ 2527679496 WIV_t_max 0;
BA_ "GenSigSwitchedByIgnition" SG_ 2527679496 WIV_W_min 0;
BA_ "GenSigStartValue" SG_ 2527679496 WIV_W_min 17;
BA_ "GenSigSendType" SG_ 2527679496 WIV_W_min 0;
BA_ "GenSigSwitchedByIgnition" SG_ 2527679496 WIV_W_max 0;
BA_ "GenSigStartValue" SG_ 2527679496 WIV_W_max 31;
BA_ "GenSigSendType" SG_ 2527679496 WIV_W_max 0;
BA_ "GenSigSwitchedByIgnition" SG_ 2617130496 XCP_AAG_CRO_01_Data 0;
BA_ "GenSigSwitchedByIgnition" SG_ 2617130497 XCP_AAG_DTO_01_Data 0;
BA_ "GenSigSwitchedByIgnition" SG_ 2617013760 XCP_BCM1_CRO_01_Data 0;
BA_ "GenSigSwitchedByIgnition" SG_ 2617013761 XCP_BCM1_DTO_01_Data 0;
BA_ "GenSigSwitchedByIgnition" SG_ 2617007872 XCP_BCM2_CRO_01_Data 0;
BA_ "GenSigSwitchedByIgnition" SG_ 2617007873 XCP_BCM2_DTO_01_Data 0;
BA_ "GenSigSwitchedByIgnition" SG_ 2617085440 XCP_ELV_CRO_01_Data 0;
BA_ "GenSigSwitchedByIgnition" SG_ 2617085441 XCP_ELV_DTO_01_Data 0;
BA_ "GenSigSwitchedByIgnition" SG_ 2617056768 XCP_HDSG_CRO_01_Data 0;
BA_ "GenSigSwitchedByIgnition" SG_ 2617056769 XCP_HDSG_DTO_01_Data 0;
BA_ "GenSigSwitchedByIgnition" SG_ 2617075200 XCP_MFG_CRO_01_Data 0;
BA_ "GenSigSwitchedByIgnition" SG_ 2617075201 XCP_MFG_DTO_01_Data 0;
BA_ "GenSigSwitchedByIgnition" SG_ 2617050880 XCP_SAD2_CRO_01_Data 0;
BA_ "GenSigSwitchedByIgnition" SG_ 2617050881 XCP_SAD2_DTO_01_Data 0;
BA_ "GenSigSwitchedByIgnition" SG_ 2616993536 XCP_SAD_CRO_01_Data 0;
BA_ "GenSigSwitchedByIgnition" SG_ 2616993537 XCP_SAD_DTO_01_Data 0;
BA_ "GenSigSwitchedByIgnition" SG_ 2617040640 XCP_MSBBR_CRO_01_Data 0;
BA_ "GenSigSwitchedByIgnition" SG_ 2617040641 XCP_MSBBR_DTO_01_Data 0;
BA_ "GenSigSwitchedByIgnition" SG_ 2617142784 XCP_SitzMem_BFS_CRO_01_Data 0;
BA_ "GenSigSwitchedByIgnition" SG_ 2617142785 XCP_SitzMem_BFS_DTO_01_Data 0;
BA_ "GenSigSwitchedByIgnition" SG_ 2617140736 XCP_SitzMem_FS_CRO_01_Data 0;
BA_ "GenSigSwitchedByIgnition" SG_ 2617140737 XCP_SitzMem_FS_DTO_01_Data 0;
BA_ "GenSigSwitchedByIgnition" SG_ 2617001728 XCP_SitzMem_HBFS_CRO_01_Data 0;
BA_ "GenSigSwitchedByIgnition" SG_ 2617001729 XCP_SitzMem_HBFS_DTO_01_Data 0;
BA_ "GenSigSwitchedByIgnition" SG_ 2616999680 XCP_SitzMem_HFS_CRO_01_Data 0;
BA_ "GenSigSwitchedByIgnition" SG_ 2616999681 XCP_SitzMem_HFS_DTO_01_Data 0;
BA_ "GenSigSwitchedByIgnition" SG_ 2617028352 XCP_SitzMem_SR3_CRO_01_Data 0;
BA_ "GenSigSwitchedByIgnition" SG_ 2617028353 XCP_SitzMem_SR3_DTO_01_Data 0;
BA_ "GenSigSwitchedByIgnition" SG_ 2617058816 XCP_SpoilerSG_CRO_01_Data 0;
BA_ "GenSigSwitchedByIgnition" SG_ 2617058817 XCP_SpoilerSG_DTO_01_Data 0;
BA_ "GenSigSwitchedByIgnition" SG_ 2617073152 XCP_STS_CRO_01_Data 0;
BA_ "GenSigSwitchedByIgnition" SG_ 2617073153 XCP_STS_DTO_01_Data 0;
BA_ "GenSigSwitchedByIgnition" SG_ 2617138688 XCP_TSG_BT_CRO_01_Data 0;
BA_ "GenSigSwitchedByIgnition" SG_ 2617138689 XCP_TSG_BT_DTO_01_Data 0;
BA_ "GenSigSwitchedByIgnition" SG_ 2617136640 XCP_TSG_FT_CRO_01_Data 0;
BA_ "GenSigSwitchedByIgnition" SG_ 2617136641 XCP_TSG_FT_DTO_01_Data 0;
BA_ "GenSigSwitchedByIgnition" SG_ 2566802688 XCP_TSG_HBFS_CRO_01_Data 0;
BA_ "GenSigSwitchedByIgnition" SG_ 2566802689 XCP_TSG_HBFS_DTO_01_Data 0;
BA_ "GenSigSwitchedByIgnition" SG_ 2566802432 XCP_TSG_HFS_CRO_01_Data 0;
BA_ "GenSigSwitchedByIgnition" SG_ 2566802433 XCP_TSG_HFS_DTO_01_Data 0;
BA_ "GenSigSwitchedByIgnition" SG_ 2617077248 XCP_VSG_CRO_01_Data 0;
BA_ "GenSigSwitchedByIgnition" SG_ 2617077249 XCP_VSG_DTO_01_Data 0;
BA_ "GenSigSwitchedByIgnition" SG_ 389 ZFH_FS_ManHoch 0;
BA_ "GenSigSendType" SG_ 389 ZFH_FS_ManHoch 4;
BA_ "GenSigSwitchedByIgnition" SG_ 389 ZFH_FS_AutoHoch 0;
BA_ "GenSigSendType" SG_ 389 ZFH_FS_AutoHoch 4;
BA_ "GenSigSwitchedByIgnition" SG_ 389 ZFH_FS_ManTief 0;
BA_ "GenSigSendType" SG_ 389 ZFH_FS_ManTief 4;
BA_ "GenSigSwitchedByIgnition" SG_ 389 ZFH_FS_AutoTief 0;
BA_ "GenSigSendType" SG_ 389 ZFH_FS_AutoTief 4;
BA_ "GenSigSwitchedByIgnition" SG_ 389 ZFH_BFS_ManHoch 0;
BA_ "GenSigSendType" SG_ 389 ZFH_BFS_ManHoch 4;
BA_ "GenSigSwitchedByIgnition" SG_ 389 ZFH_BFS_AutoHoch 0;
BA_ "GenSigSendType" SG_ 389 ZFH_BFS_AutoHoch 4;
BA_ "GenSigSwitchedByIgnition" SG_ 389 ZFH_BFS_ManTief 0;
BA_ "GenSigSendType" SG_ 389 ZFH_BFS_ManTief 4;
BA_ "GenSigSwitchedByIgnition" SG_ 389 ZFH_BFS_AutoTief 0;
BA_ "GenSigSendType" SG_ 389 ZFH_BFS_AutoTief 4;
BA_ "GenSigSwitchedByIgnition" SG_ 389 ZFH_HFS_ManHoch 0;
BA_ "GenSigSendType" SG_ 389 ZFH_HFS_ManHoch 4;
BA_ "GenSigSwitchedByIgnition" SG_ 389 ZFH_HFS_AutoHoch 0;
BA_ "GenSigSendType" SG_ 389 ZFH_HFS_AutoHoch 4;
BA_ "GenSigSwitchedByIgnition" SG_ 389 ZFH_HFS_ManTief 0;
BA_ "GenSigSendType" SG_ 389 ZFH_HFS_ManTief 4;
BA_ "GenSigSwitchedByIgnition" SG_ 389 ZFH_HFS_AutoTief 0;
BA_ "GenSigSendType" SG_ 389 ZFH_HFS_AutoTief 4;
BA_ "GenSigSwitchedByIgnition" SG_ 389 ZFH_HBFS_ManHoch 0;
BA_ "GenSigSendType" SG_ 389 ZFH_HBFS_ManHoch 4;
BA_ "GenSigSwitchedByIgnition" SG_ 389 ZFH_HBFS_AutoHoch 0;
BA_ "GenSigSendType" SG_ 389 ZFH_HBFS_AutoHoch 4;
BA_ "GenSigSwitchedByIgnition" SG_ 389 ZFH_HBFS_ManTief 0;
BA_ "GenSigSendType" SG_ 389 ZFH_HBFS_ManTief 4;
BA_ "GenSigSwitchedByIgnition" SG_ 389 ZFH_HBFS_AutoTief 0;
BA_ "GenSigSendType" SG_ 389 ZFH_HBFS_AutoTief 4;
BA_ "GenSigSwitchedByIgnition" SG_ 389 ZFH_zentral_zu 0;
BA_ "GenSigSendType" SG_ 389 ZFH_zentral_zu 4;
BA_ "GenSigSwitchedByIgnition" SG_ 389 ZFH_zentral_auf 0;
BA_ "GenSigSendType" SG_ 389 ZFH_zentral_auf 4;
BA_ "GenSigSwitchedByIgnition" SG_ 389 Krypt_Signatur 0;
BA_ "GenSigSendType" SG_ 389 Krypt_Signatur 4;
BA_ "GenSigActiveRepetitions" SG_ 389 Krypt_Signatur 5;
BA_ "GenSigSwitchedByIgnition" SG_ 389 Krypt_Schluesselschalter_auf 0;
BA_ "GenSigSendType" SG_ 389 Krypt_Schluesselschalter_auf 4;
BA_ "GenSigActiveRepetitions" SG_ 389 Krypt_Schluesselschalter_auf 5;
BA_ "GenSigSwitchedByIgnition" SG_ 389 Krypt_Schluesselschalter_zu 0;
BA_ "GenSigSendType" SG_ 389 Krypt_Schluesselschalter_zu 4;
BA_ "GenSigActiveRepetitions" SG_ 389 Krypt_Schluesselschalter_zu 5;
BA_ "GenSigSwitchedByIgnition" SG_ 392 BT_FH_BT_ManHoch 0;
BA_ "GenSigSendType" SG_ 392 BT_FH_BT_ManHoch 4;
BA_ "GenSigActiveRepetitions" SG_ 392 BT_FH_BT_ManHoch 5;
BA_ "GenSigSwitchedByIgnition" SG_ 392 BT_FH_BT_AutoHoch 0;
BA_ "GenSigSendType" SG_ 392 BT_FH_BT_AutoHoch 4;
BA_ "GenSigActiveRepetitions" SG_ 392 BT_FH_BT_AutoHoch 5;
BA_ "GenSigSwitchedByIgnition" SG_ 392 BT_FH_BT_ManTief 0;
BA_ "GenSigSendType" SG_ 392 BT_FH_BT_ManTief 4;
BA_ "GenSigActiveRepetitions" SG_ 392 BT_FH_BT_ManTief 5;
BA_ "GenSigSwitchedByIgnition" SG_ 392 BT_FH_BT_AutoTief 0;
BA_ "GenSigSendType" SG_ 392 BT_FH_BT_AutoTief 4;
BA_ "GenSigActiveRepetitions" SG_ 392 BT_FH_BT_AutoTief 5;
BA_ "GenSigSwitchedByIgnition" SG_ 392 BT_FH_FT_ManHoch 0;
BA_ "GenSigSendType" SG_ 392 BT_FH_FT_ManHoch 4;
BA_ "GenSigActiveRepetitions" SG_ 392 BT_FH_FT_ManHoch 5;
BA_ "GenSigSwitchedByIgnition" SG_ 392 BT_FH_FT_AutoHoch 0;
BA_ "GenSigSendType" SG_ 392 BT_FH_FT_AutoHoch 4;
BA_ "GenSigActiveRepetitions" SG_ 392 BT_FH_FT_AutoHoch 5;
BA_ "GenSigSwitchedByIgnition" SG_ 392 BT_FH_FT_ManTief 0;
BA_ "GenSigSendType" SG_ 392 BT_FH_FT_ManTief 4;
BA_ "GenSigActiveRepetitions" SG_ 392 BT_FH_FT_ManTief 5;
BA_ "GenSigSwitchedByIgnition" SG_ 392 BT_FH_FT_AutoTief 0;
BA_ "GenSigSendType" SG_ 392 BT_FH_FT_AutoTief 4;
BA_ "GenSigActiveRepetitions" SG_ 392 BT_FH_FT_AutoTief 5;
BA_ "GenSigSwitchedByIgnition" SG_ 392 BT_FH_HFS_ManHoch 0;
BA_ "GenSigSendType" SG_ 392 BT_FH_HFS_ManHoch 4;
BA_ "GenSigActiveRepetitions" SG_ 392 BT_FH_HFS_ManHoch 5;
BA_ "GenSigSwitchedByIgnition" SG_ 392 BT_FH_HFS_AutoHoch 0;
BA_ "GenSigSendType" SG_ 392 BT_FH_HFS_AutoHoch 4;
BA_ "GenSigActiveRepetitions" SG_ 392 BT_FH_HFS_AutoHoch 5;
BA_ "GenSigSwitchedByIgnition" SG_ 392 BT_FH_HFS_ManTief 0;
BA_ "GenSigSendType" SG_ 392 BT_FH_HFS_ManTief 4;
BA_ "GenSigActiveRepetitions" SG_ 392 BT_FH_HFS_ManTief 5;
BA_ "GenSigSwitchedByIgnition" SG_ 392 BT_FH_HFS_AutoTief 0;
BA_ "GenSigSendType" SG_ 392 BT_FH_HFS_AutoTief 4;
BA_ "GenSigActiveRepetitions" SG_ 392 BT_FH_HFS_AutoTief 5;
BA_ "GenSigSwitchedByIgnition" SG_ 392 BT_FH_HBFS_ManHoch 0;
BA_ "GenSigSendType" SG_ 392 BT_FH_HBFS_ManHoch 4;
BA_ "GenSigActiveRepetitions" SG_ 392 BT_FH_HBFS_ManHoch 5;
BA_ "GenSigSwitchedByIgnition" SG_ 392 BT_FH_HBFS_AutoHoch 0;
BA_ "GenSigSendType" SG_ 392 BT_FH_HBFS_AutoHoch 4;
BA_ "GenSigActiveRepetitions" SG_ 392 BT_FH_HBFS_AutoHoch 5;
BA_ "GenSigSwitchedByIgnition" SG_ 392 BT_FH_HBFS_ManTief 0;
BA_ "GenSigSendType" SG_ 392 BT_FH_HBFS_ManTief 4;
BA_ "GenSigActiveRepetitions" SG_ 392 BT_FH_HBFS_ManTief 5;
BA_ "GenSigSwitchedByIgnition" SG_ 392 BT_FH_HBFS_AutoTief 0;
BA_ "GenSigSendType" SG_ 392 BT_FH_HBFS_AutoTief 4;
BA_ "GenSigActiveRepetitions" SG_ 392 BT_FH_HBFS_AutoTief 5;
BA_ "GenSigSwitchedByIgnition" SG_ 392 BT_SP_hoch 0;
BA_ "GenSigSendType" SG_ 392 BT_SP_hoch 4;
BA_ "GenSigActiveRepetitions" SG_ 392 BT_SP_hoch 5;
BA_ "GenSigSwitchedByIgnition" SG_ 392 BT_SP_tief 0;
BA_ "GenSigSendType" SG_ 392 BT_SP_tief 4;
BA_ "GenSigActiveRepetitions" SG_ 392 BT_SP_tief 5;
BA_ "GenSigSwitchedByIgnition" SG_ 392 BT_SP_links 0;
BA_ "GenSigSendType" SG_ 392 BT_SP_links 4;
BA_ "GenSigActiveRepetitions" SG_ 392 BT_SP_links 5;
BA_ "GenSigSwitchedByIgnition" SG_ 392 BT_SP_rechts 0;
BA_ "GenSigSendType" SG_ 392 BT_SP_rechts 4;
BA_ "GenSigActiveRepetitions" SG_ 392 BT_SP_rechts 5;
BA_ "GenSigSwitchedByIgnition" SG_ 392 BT_SP_Garagenstellung 0;
BA_ "GenSigSendType" SG_ 392 BT_SP_Garagenstellung 4;
BA_ "GenSigActiveRepetitions" SG_ 392 BT_SP_Garagenstellung 5;
BA_ "GenSigSwitchedByIgnition" SG_ 392 BT_SP_Fahrstellung 0;
BA_ "GenSigSendType" SG_ 392 BT_SP_Fahrstellung 4;
BA_ "GenSigActiveRepetitions" SG_ 392 BT_SP_Fahrstellung 5;
BA_ "GenSigSwitchedByIgnition" SG_ 392 BT_FH_zentral_zu 0;
BA_ "GenSigSendType" SG_ 392 BT_FH_zentral_zu 4;
BA_ "GenSigActiveRepetitions" SG_ 392 BT_FH_zentral_zu 5;
BA_ "GenSigSwitchedByIgnition" SG_ 392 BT_FH_zentral_auf 0;
BA_ "GenSigSendType" SG_ 392 BT_FH_zentral_auf 4;
BA_ "GenSigActiveRepetitions" SG_ 392 BT_FH_zentral_auf 5;
BA_ "GenSigFuncType" SG_ 388 ZV_01_CRC 2;
BA_ "GenSigSendType" SG_ 388 ZV_01_CRC 0;
BA_ "GenSigFuncType" SG_ 388 ZV_01_BZ 1;
BA_ "GenSigSendType" SG_ 388 ZV_01_BZ 0;
BA_ "GenSigSwitchedByIgnition" SG_ 388 ZV_FT_verriegeln 0;
BA_ "GenSigSendType" SG_ 388 ZV_FT_verriegeln 6;
BA_ "GenSigActiveRepetitions" SG_ 388 ZV_FT_verriegeln 11;
BA_ "GenSigSwitchedByIgnition" SG_ 388 ZV_FT_entriegeln 0;
BA_ "GenSigSendType" SG_ 388 ZV_FT_entriegeln 6;
BA_ "GenSigActiveRepetitions" SG_ 388 ZV_FT_entriegeln 11;
BA_ "GenSigSwitchedByIgnition" SG_ 388 ZV_BT_verriegeln 0;
BA_ "GenSigSendType" SG_ 388 ZV_BT_verriegeln 6;
BA_ "GenSigActiveRepetitions" SG_ 388 ZV_BT_verriegeln 11;
BA_ "GenSigSwitchedByIgnition" SG_ 388 ZV_BT_entriegeln 0;
BA_ "GenSigSendType" SG_ 388 ZV_BT_entriegeln 6;
BA_ "GenSigActiveRepetitions" SG_ 388 ZV_BT_entriegeln 11;
BA_ "GenSigSwitchedByIgnition" SG_ 388 ZV_HFS_verriegeln 0;
BA_ "GenSigSendType" SG_ 388 ZV_HFS_verriegeln 6;
BA_ "GenSigActiveRepetitions" SG_ 388 ZV_HFS_verriegeln 11;
BA_ "GenSigSwitchedByIgnition" SG_ 388 ZV_HFS_entriegeln 0;
BA_ "GenSigSendType" SG_ 388 ZV_HFS_entriegeln 6;
BA_ "GenSigActiveRepetitions" SG_ 388 ZV_HFS_entriegeln 11;
BA_ "GenSigSwitchedByIgnition" SG_ 388 ZV_HBFS_verriegeln 0;
BA_ "GenSigSendType" SG_ 388 ZV_HBFS_verriegeln 6;
BA_ "GenSigActiveRepetitions" SG_ 388 ZV_HBFS_verriegeln 11;
BA_ "GenSigSwitchedByIgnition" SG_ 388 ZV_HBFS_entriegeln 0;
BA_ "GenSigSendType" SG_ 388 ZV_HBFS_entriegeln 6;
BA_ "GenSigActiveRepetitions" SG_ 388 ZV_HBFS_entriegeln 11;
BA_ "GenSigSwitchedByIgnition" SG_ 388 ZV_zentral_safen 0;
BA_ "GenSigSendType" SG_ 388 ZV_zentral_safen 6;
BA_ "GenSigActiveRepetitions" SG_ 388 ZV_zentral_safen 11;
BA_ "GenSigSwitchedByIgnition" SG_ 388 ZV_zentral_entsafen 0;
BA_ "GenSigSendType" SG_ 388 ZV_zentral_entsafen 6;
BA_ "GenSigActiveRepetitions" SG_ 388 ZV_zentral_entsafen 11;
BA_ "GenSigSwitchedByIgnition" SG_ 388 ZV_Spg_Anklappen 0;
BA_ "GenSigSendType" SG_ 388 ZV_Spg_Anklappen 6;
BA_ "GenSigActiveRepetitions" SG_ 388 ZV_Spg_Anklappen 11;
BA_ "GenSigSwitchedByIgnition" SG_ 388 ZV_Softtouch_betaetigt 0;
BA_ "GenSigSendType" SG_ 388 ZV_Softtouch_betaetigt 6;
BA_ "GenSigActiveRepetitions" SG_ 388 ZV_Softtouch_betaetigt 11;
BA_ "GenSigSwitchedByIgnition" SG_ 388 ZV_LED_Steuerung 0;
BA_ "GenSigSendType" SG_ 388 ZV_LED_Steuerung 6;
BA_ "GenSigActiveRepetitions" SG_ 388 ZV_LED_Steuerung 11;
BA_ "GenSigSwitchedByIgnition" SG_ 388 ZV_LED_Uebernahme 0;
BA_ "GenSigSendType" SG_ 388 ZV_LED_Uebernahme 6;
BA_ "GenSigActiveRepetitions" SG_ 388 ZV_LED_Uebernahme 11;
BA_ "GenSigSwitchedByIgnition" SG_ 388 ZV_auf_FT 0;
BA_ "GenSigSendType" SG_ 388 ZV_auf_FT 6;
BA_ "GenSigActiveRepetitions" SG_ 388 ZV_auf_FT 11;
BA_ "GenSigSwitchedByIgnition" SG_ 388 ZV_zu_FT 0;
BA_ "GenSigSendType" SG_ 388 ZV_zu_FT 6;
BA_ "GenSigActiveRepetitions" SG_ 388 ZV_zu_FT 11;
BA_ "GenSigSwitchedByIgnition" SG_ 388 ZV_auf_BT 0;
BA_ "GenSigSendType" SG_ 388 ZV_auf_BT 6;
BA_ "GenSigActiveRepetitions" SG_ 388 ZV_auf_BT 11;
BA_ "GenSigSwitchedByIgnition" SG_ 388 ZV_zu_BT 0;
BA_ "GenSigSendType" SG_ 388 ZV_zu_BT 6;
BA_ "GenSigActiveRepetitions" SG_ 388 ZV_zu_BT 11;
BA_ "GenSigSwitchedByIgnition" SG_ 388 ZV_auf_Kessy 0;
BA_ "GenSigSendType" SG_ 388 ZV_auf_Kessy 6;
BA_ "GenSigActiveRepetitions" SG_ 388 ZV_auf_Kessy 11;
BA_ "GenSigSwitchedByIgnition" SG_ 388 ZV_zu_Kessy 0;
BA_ "GenSigSendType" SG_ 388 ZV_zu_Kessy 6;
BA_ "GenSigActiveRepetitions" SG_ 388 ZV_zu_Kessy 11;
BA_ "GenSigSwitchedByIgnition" SG_ 388 ZV_auf_Funk 0;
BA_ "GenSigSendType" SG_ 388 ZV_auf_Funk 6;
BA_ "GenSigActiveRepetitions" SG_ 388 ZV_auf_Funk 11;
BA_ "GenSigSwitchedByIgnition" SG_ 388 ZV_zu_Funk 0;
BA_ "GenSigSendType" SG_ 388 ZV_zu_Funk 6;
BA_ "GenSigActiveRepetitions" SG_ 388 ZV_zu_Funk 11;
BA_ "GenSigSwitchedByIgnition" SG_ 388 VIP_Sensor_betaetigt 0;
BA_ "GenSigSendType" SG_ 388 VIP_Sensor_betaetigt 6;
BA_ "GenSigActiveRepetitions" SG_ 388 VIP_Sensor_betaetigt 11;
BA_ "GenSigSwitchedByIgnition" SG_ 388 VIP_Freigabe 0;
BA_ "GenSigSendType" SG_ 388 VIP_Freigabe 0;
BA_ "GenSigSwitchedByIgnition" SG_ 388 ZV_zu_Zeitl_Nachverr 0;
BA_ "GenSigSendType" SG_ 388 ZV_zu_Zeitl_Nachverr 6;
BA_ "GenSigActiveRepetitions" SG_ 388 ZV_zu_Zeitl_Nachverr 11;
BA_ "GenSigSwitchedByIgnition" SG_ 388 ZV_HSK_entriegeln 0;
BA_ "GenSigSendType" SG_ 388 ZV_HSK_entriegeln 6;
BA_ "GenSigActiveRepetitions" SG_ 388 ZV_HSK_entriegeln 11;
BA_ "GenSigSwitchedByIgnition" SG_ 388 ZV_HSK_verriegeln 0;
BA_ "GenSigSendType" SG_ 388 ZV_HSK_verriegeln 6;
BA_ "GenSigActiveRepetitions" SG_ 388 ZV_HSK_verriegeln 11;
BA_ "GenSigSwitchedByIgnition" SG_ 388 ZV_Verdeck_zu 0;
BA_ "GenSigSendType" SG_ 388 ZV_Verdeck_zu 6;
BA_ "GenSigActiveRepetitions" SG_ 388 ZV_Verdeck_zu 11;
BA_ "GenSigSwitchedByIgnition" SG_ 388 ZV_Verdeck_auf 0;
BA_ "GenSigSendType" SG_ 388 ZV_Verdeck_auf 6;
BA_ "GenSigActiveRepetitions" SG_ 388 ZV_Verdeck_auf 11;
BA_ "GenSigSwitchedByIgnition" SG_ 388 FH_FT_hoch 0;
BA_ "GenSigSendType" SG_ 388 FH_FT_hoch 6;
BA_ "GenSigActiveRepetitions" SG_ 388 FH_FT_hoch 11;
BA_ "GenSigSwitchedByIgnition" SG_ 388 FH_FT_tief 0;
BA_ "GenSigSendType" SG_ 388 FH_FT_tief 6;
BA_ "GenSigActiveRepetitions" SG_ 388 FH_FT_tief 11;
BA_ "GenSigSwitchedByIgnition" SG_ 388 FH_BT_hoch 0;
BA_ "GenSigSendType" SG_ 388 FH_BT_hoch 6;
BA_ "GenSigActiveRepetitions" SG_ 388 FH_BT_hoch 11;
BA_ "GenSigSwitchedByIgnition" SG_ 388 FH_BT_tief 0;
BA_ "GenSigSendType" SG_ 388 FH_BT_tief 6;
BA_ "GenSigActiveRepetitions" SG_ 388 FH_BT_tief 11;
BA_ "GenSigSwitchedByIgnition" SG_ 388 FH_HFS_hoch 0;
BA_ "GenSigSendType" SG_ 388 FH_HFS_hoch 6;
BA_ "GenSigSwitchedByIgnition" SG_ 388 FH_HFS_tief 0;
BA_ "GenSigSendType" SG_ 388 FH_HFS_tief 6;
BA_ "GenSigSwitchedByIgnition" SG_ 388 FH_HBFS_hoch 0;
BA_ "GenSigSendType" SG_ 388 FH_HBFS_hoch 6;
BA_ "GenSigSwitchedByIgnition" SG_ 388 FH_HBFS_tief 0;
BA_ "GenSigSendType" SG_ 388 FH_HBFS_tief 6;
BA_ "GenSigSwitchedByIgnition" SG_ 388 BCM_Spg_Synchron 0;
BA_ "GenSigSendType" SG_ 388 BCM_Spg_Synchron 0;
BA_ "GenSigSwitchedByIgnition" SG_ 388 BCM_BF_Spg_Absenkung 0;
BA_ "GenSigSendType" SG_ 388 BCM_BF_Spg_Absenkung 0;
BA_ "GenSigSwitchedByIgnition" SG_ 388 ZV_Signatur 0;
BA_ "GenSigSendType" SG_ 388 ZV_Signatur 6;
BA_ "GenSigActiveRepetitions" SG_ 388 ZV_Signatur 11;
BA_ "GenSigSwitchedByIgnition" SG_ 1411 BCM_FH_Freigabe 0;
BA_ "GenSigSendType" SG_ 1411 BCM_FH_Freigabe 3;
BA_ "GenSigSwitchedByIgnition" SG_ 1411 BCM_Komfortfkt_Freigabe 0;
BA_ "GenSigSendType" SG_ 1411 BCM_Komfortfkt_Freigabe 3;
BA_ "GenSigSwitchedByIgnition" SG_ 1411 BCM_HSK_Freigabe 0;
BA_ "GenSigSendType" SG_ 1411 BCM_HSK_Freigabe 3;
BA_ "GenSigSwitchedByIgnition" SG_ 1411 BCM_Verdeck_Freigabe 0;
BA_ "GenSigSendType" SG_ 1411 BCM_Verdeck_Freigabe 3;
BA_ "GenSigSwitchedByIgnition" SG_ 1411 ZV_verriegelt_intern_ist 0;
BA_ "GenSigSendType" SG_ 1411 ZV_verriegelt_intern_ist 3;
BA_ "GenSigSwitchedByIgnition" SG_ 1411 ZV_verriegelt_extern_ist 0;
BA_ "GenSigSendType" SG_ 1411 ZV_verriegelt_extern_ist 3;
BA_ "GenSigSwitchedByIgnition" SG_ 1411 ZV_verriegelt_intern_soll 0;
BA_ "GenSigSendType" SG_ 1411 ZV_verriegelt_intern_soll 3;
BA_ "GenSigSwitchedByIgnition" SG_ 1411 ZV_verriegelt_extern_soll 0;
BA_ "GenSigSendType" SG_ 1411 ZV_verriegelt_extern_soll 3;
BA_ "GenSigSwitchedByIgnition" SG_ 1411 ZV_gesafet_extern_ist 0;
BA_ "GenSigSendType" SG_ 1411 ZV_gesafet_extern_ist 3;
BA_ "GenSigSwitchedByIgnition" SG_ 1411 ZV_gesafet_extern_soll 0;
BA_ "GenSigSendType" SG_ 1411 ZV_gesafet_extern_soll 3;
BA_ "GenSigSwitchedByIgnition" SG_ 1411 ZV_Einzeltuerentriegelung 0;
BA_ "GenSigSendType" SG_ 1411 ZV_Einzeltuerentriegelung 3;
BA_ "GenSigSwitchedByIgnition" SG_ 1411 ZV_Heckeinzelentriegelung 0;
BA_ "GenSigSendType" SG_ 1411 ZV_Heckeinzelentriegelung 3;
BA_ "GenSigSwitchedByIgnition" SG_ 1411 ZV_FT_offen 0;
BA_ "GenSigSendType" SG_ 1411 ZV_FT_offen 3;
BA_ "GenSigSwitchedByIgnition" SG_ 1411 ZV_BT_offen 0;
BA_ "GenSigSendType" SG_ 1411 ZV_BT_offen 3;
BA_ "GenSigSwitchedByIgnition" SG_ 1411 ZV_HFS_offen 0;
BA_ "GenSigSendType" SG_ 1411 ZV_HFS_offen 3;
BA_ "GenSigSwitchedByIgnition" SG_ 1411 ZV_HBFS_offen 0;
BA_ "GenSigSendType" SG_ 1411 ZV_HBFS_offen 3;
BA_ "GenSigSwitchedByIgnition" SG_ 1411 ZV_HD_offen 0;
BA_ "GenSigSendType" SG_ 1411 ZV_HD_offen 3;
BA_ "GenSigSwitchedByIgnition" SG_ 1411 ZV_HS_offen 0;
BA_ "GenSigSendType" SG_ 1411 ZV_HS_offen 3;
BA_ "GenSigSwitchedByIgnition" SG_ 1411 IRUE_aktiv 0;
BA_ "GenSigSendType" SG_ 1411 IRUE_aktiv 3;
BA_ "GenSigSwitchedByIgnition" SG_ 1411 DWA_aktiv 0;
BA_ "GenSigSendType" SG_ 1411 DWA_aktiv 3;
BA_ "GenSigSwitchedByIgnition" SG_ 1411 HD_Hauptraste 0;
BA_ "GenSigSendType" SG_ 1411 HD_Hauptraste 3;
BA_ "GenSigSwitchedByIgnition" SG_ 1411 HD_Vorraste 0;
BA_ "GenSigSendType" SG_ 1411 HD_Vorraste 3;
BA_ "GenSigSwitchedByIgnition" SG_ 1411 FFB_HDF_Taste 0;
BA_ "GenSigSendType" SG_ 1411 FFB_HDF_Taste 2;
BA_ "GenSigActiveRepetitions" SG_ 1411 FFB_HDF_Taste 5;
BA_ "GenSigSwitchedByIgnition" SG_ 1411 FFB_Panik_Taste 0;
BA_ "GenSigSendType" SG_ 1411 FFB_Panik_Taste 2;
BA_ "GenSigActiveRepetitions" SG_ 1411 FFB_Panik_Taste 5;
BA_ "GenSigSwitchedByIgnition" SG_ 1411 FFB_Auf_Taste 0;
BA_ "GenSigSendType" SG_ 1411 FFB_Auf_Taste 2;
BA_ "GenSigActiveRepetitions" SG_ 1411 FFB_Auf_Taste 5;
BA_ "GenSigSwitchedByIgnition" SG_ 1411 FFB_Zu_Taste 0;
BA_ "GenSigSendType" SG_ 1411 FFB_Zu_Taste 2;
BA_ "GenSigActiveRepetitions" SG_ 1411 FFB_Zu_Taste 5;
BA_ "GenSigSwitchedByIgnition" SG_ 1411 FFB_CarFinder 0;
BA_ "GenSigSendType" SG_ 1411 FFB_CarFinder 2;
BA_ "GenSigActiveRepetitions" SG_ 1411 FFB_CarFinder 5;
BA_ "GenSigSwitchedByIgnition" SG_ 1411 FFB_Komfortoeffnen 0;
BA_ "GenSigSendType" SG_ 1411 FFB_Komfortoeffnen 2;
BA_ "GenSigActiveRepetitions" SG_ 1411 FFB_Komfortoeffnen 5;
BA_ "GenSigSwitchedByIgnition" SG_ 1411 FFB_Komfortschliessen 0;
BA_ "GenSigSendType" SG_ 1411 FFB_Komfortschliessen 2;
BA_ "GenSigActiveRepetitions" SG_ 1411 FFB_Komfortschliessen 5;
BA_ "GenSigSwitchedByIgnition" SG_ 1411 FBS_IDG_in_Reichweite 0;
BA_ "GenSigSendType" SG_ 1411 FBS_IDG_in_Reichweite 2;
BA_ "GenSigActiveRepetitions" SG_ 1411 FBS_IDG_in_Reichweite 5;
BA_ "GenSigSwitchedByIgnition" SG_ 1411 ZV_Schluessel_Zugang 0;
BA_ "GenSigSendType" SG_ 1411 ZV_Schluessel_Zugang 4;
BA_ "GenSigActiveRepetitions" SG_ 1411 ZV_Schluessel_Zugang 3;
BA_ "GenSigSwitchedByIgnition" SG_ 1411 ZV_SafeFunktion_aktiv 0;
BA_ "GenSigSendType" SG_ 1411 ZV_SafeFunktion_aktiv 3;
BA_ "GenSigSwitchedByIgnition" SG_ 1411 FBS_Warn_Schluessel_Batt 0;
BA_ "GenSigSendType" SG_ 1411 FBS_Warn_Schluessel_Batt 3;
BA_ "GenSigSwitchedByIgnition" SG_ 1411 ZV_Oeffnungsmodus 0;
BA_ "GenSigSendType" SG_ 1411 ZV_Oeffnungsmodus 3;
BA_ "GenSigSwitchedByIgnition" SG_ 1411 HFS_verriegelt 0;
BA_ "GenSigSendType" SG_ 1411 HFS_verriegelt 3;
BA_ "GenSigSwitchedByIgnition" SG_ 1411 HFS_gesafet 0;
BA_ "GenSigSendType" SG_ 1411 HFS_gesafet 3;
BA_ "GenSigSwitchedByIgnition" SG_ 1411 HBFS_verriegelt 0;
BA_ "GenSigSendType" SG_ 1411 HBFS_verriegelt 3;
BA_ "GenSigSwitchedByIgnition" SG_ 1411 HBFS_gesafet 0;
BA_ "GenSigSendType" SG_ 1411 HBFS_gesafet 3;
BA_ "GenSigSwitchedByIgnition" SG_ 1411 ZV_ist_Zustand_verfuegbar 0;
BA_ "GenSigSendType" SG_ 1411 ZV_ist_Zustand_verfuegbar 3;
BA_ "GenSigSwitchedByIgnition" SG_ 1411 IRUE_Taster_Fkts_LED 0;
BA_ "GenSigSendType" SG_ 1411 IRUE_Taster_Fkts_LED 3;
BA_ "GenSigSwitchedByIgnition" SG_ 1411 ZV_Tankklappe_offen 0;
BA_ "GenSigSendType" SG_ 1411 ZV_Tankklappe_offen 0;
BA_ "GenSigSwitchedByIgnition" SG_ 1411 ZV_Rollo_auf 0;
BA_ "GenSigSendType" SG_ 1411 ZV_Rollo_auf 3;
BA_ "GenSigSwitchedByIgnition" SG_ 1411 ZV_Rollo_zu 0;
BA_ "GenSigSendType" SG_ 1411 ZV_Rollo_zu 3;
BA_ "GenSigSwitchedByIgnition" SG_ 1411 ZV_SAD_auf 0;
BA_ "GenSigSendType" SG_ 1411 ZV_SAD_auf 3;
BA_ "GenSigSwitchedByIgnition" SG_ 1411 ZV_SAD_zu 0;
BA_ "GenSigSendType" SG_ 1411 ZV_SAD_zu 3;
BA_ "Fehlerwert" SG_ 1411 BCM_Tankklappensteller_Fehler 1;
BA_ "GenSigSwitchedByIgnition" SG_ 1411 BCM_Tankklappensteller_Fehler 0;
BA_ "GenSigSendType" SG_ 1411 BCM_Tankklappensteller_Fehler 0;
BA_REL_ "GenSigTimeoutTime" BU_SG_REL_ BCM2 SG_ 975 HBFS_Tuer_geoeffnet 1000;
BA_REL_ "GenSigTimeoutTime" BU_SG_REL_ Gateway SG_ 975 HBFS_Tuer_geoeffnet 1000;
BA_REL_ "GenSigTimeoutTime" BU_SG_REL_ IEZS SG_ 975 HBFS_Tuer_geoeffnet 1000;
BA_REL_ "GenSigTimeoutTime" BU_SG_REL_ MFG SG_ 975 HBFS_Tuer_geoeffnet 1000;
BA_REL_ "GenSigTimeoutTime" BU_SG_REL_ SitzMem_FS SG_ 975 HBFS_Tuer_geoeffnet 1000;
BA_REL_ "GenSigTimeoutTime" BU_SG_REL_ SitzMem_HBFS SG_ 975 HBFS_Tuer_geoeffnet 1000;
BA_REL_ "GenSigTimeoutTime" BU_SG_REL_ SitzMem_SR3 SG_ 975 HBFS_Tuer_geoeffnet 1000;
BA_REL_ "GenSigTimeoutTime" BU_SG_REL_ VTS SG_ 975 HBFS_Tuer_geoeffnet 1000;
BA_REL_ "GenSigTimeoutTime" BU_SG_REL_ BCM2 SG_ 975 HBFS_verriegelt 1000;
BA_REL_ "GenSigTimeoutTime" BU_SG_REL_ Gateway SG_ 975 HBFS_verriegelt 1000;
BA_REL_ "GenSigTimeoutTime" BU_SG_REL_ MFG SG_ 975 HBFS_verriegelt 1000;
BA_REL_ "GenSigTimeoutTime" BU_SG_REL_ SitzMem_SR3 SG_ 975 HBFS_verriegelt 1000;
BA_REL_ "GenSigTimeoutTime" BU_SG_REL_ VTS SG_ 975 HBFS_verriegelt 1000;
BA_REL_ "GenSigTimeoutTime" BU_SG_REL_ BCM2 SG_ 975 HBFS_gesafet 1000;
BA_REL_ "GenSigTimeoutTime" BU_SG_REL_ Gateway SG_ 975 HBFS_gesafet 1000;
BA_REL_ "GenSigTimeoutTime" BU_SG_REL_ MFG SG_ 975 HBFS_gesafet 1000;
BA_REL_ "GenSigTimeoutTime" BU_SG_REL_ TSG_FS SG_ 975 HBFS_gesafet 1000;
BA_REL_ "GenSigTimeoutTime" BU_SG_REL_ VTS SG_ 975 HBFS_gesafet 1000;
BA_REL_ "GenSigTimeoutTime" BU_SG_REL_ BCM2 SG_ 975 HBFS_Heckrollotaster_betaetigt 1000;
BA_REL_ "GenSigTimeoutTime" BU_SG_REL_ BCM2 SG_ 975 HBFS_Tuerschloss_defekt 1000;
BA_REL_ "GenSigTimeoutTime" BU_SG_REL_ BCM2 SG_ 975 HBFS_Unlock_Taster 1000;
BA_REL_ "GenSigTimeoutTime" BU_SG_REL_ MFG SG_ 975 HBFS_Unlock_Taster 1000;
BA_REL_ "GenSigTimeoutTime" BU_SG_REL_ BCM2 SG_ 975 HBFS_Lock_Taster 1000;
BA_REL_ "GenSigTimeoutTime" BU_SG_REL_ MFG SG_ 975 HBFS_Lock_Taster 1000;
BA_REL_ "GenSigTimeoutTime" BU_SG_REL_ BCM2 SG_ 975 HBFS_Sperrklinke 1000;
BA_REL_ "GenSigTimeoutTime" BU_SG_REL_ MFG SG_ 975 HBFS_Sperrklinke 1000;
BA_REL_ "GenSigTimeoutTime" BU_SG_REL_ MFG SG_ 975 HBFS_TAG_betaetigt 1000;
BA_REL_ "GenSigTimeoutTime" BU_SG_REL_ VTS SG_ 975 HBFS_TAG_betaetigt 1000;
BA_REL_ "GenSigTimeoutTime" BU_SG_REL_ BCM1 SG_ 975 HBFS_TIG_betaetigt 1000;
BA_REL_ "GenSigTimeoutTime" BU_SG_REL_ BCM2 SG_ 975 HBFS_TIG_betaetigt 1000;
BA_REL_ "GenSigTimeoutTime" BU_SG_REL_ MFG SG_ 975 HBFS_TIG_betaetigt 1000;
BA_REL_ "GenSigTimeoutTime" BU_SG_REL_ TSG_FS SG_ 975 HBFS_FH_S_HFS_AutoHoch 1000;
BA_REL_ "GenSigTimeoutTime" BU_SG_REL_ TSG_FS SG_ 975 HBFS_FH_S_HFS_AutoTief 1000;
BA_REL_ "GenSigTimeoutTime" BU_SG_REL_ TSG_FS SG_ 975 HBFS_FH_S_HFS_ManHoch 1000;
BA_REL_ "GenSigTimeoutTime" BU_SG_REL_ TSG_FS SG_ 975 HBFS_FH_S_HFS_ManTief 1000;
BA_REL_ "GenSigTimeoutTime" BU_SG_REL_ SitzMem_HBFS SG_ 975 HBFS_Tuer_Status 1000;
BA_REL_ "GenSigTimeoutTime" BU_SG_REL_ TSG_FS SG_ 975 HBFS_Tuer_Status 1000;
BA_REL_ "GenSigTimeoutTime" BU_SG_REL_ BCM2 SG_ 975 HBFS_SAD_Schalter 1000;
BA_REL_ "GenSigTimeoutTime" BU_SG_REL_ SAD SG_ 975 HBFS_SAD_Schalter 1000;
BA_REL_ "GenSigTimeoutTime" BU_SG_REL_ BCM2 SG_ 975 HBFS_FH_S_ManHoch 1000;
BA_REL_ "GenSigTimeoutTime" BU_SG_REL_ MFG SG_ 975 HBFS_FH_S_ManHoch 1000;
BA_REL_ "GenSigTimeoutTime" BU_SG_REL_ BCM2 SG_ 975 HBFS_FH_S_AutoHoch 1000;
BA_REL_ "GenSigTimeoutTime" BU_SG_REL_ MFG SG_ 975 HBFS_FH_S_AutoHoch 1000;
BA_REL_ "GenSigTimeoutTime" BU_SG_REL_ BCM2 SG_ 975 HBFS_FH_S_ManTief 1000;
BA_REL_ "GenSigTimeoutTime" BU_SG_REL_ MFG SG_ 975 HBFS_FH_S_ManTief 1000;
BA_REL_ "GenSigTimeoutTime" BU_SG_REL_ BCM2 SG_ 975 HBFS_FH_S_AutoTief 1000;
BA_REL_ "GenSigTimeoutTime" BU_SG_REL_ MFG SG_ 975 HBFS_FH_S_AutoTief 1000;
BA_REL_ "GenSigTimeoutTime" BU_SG_REL_ BCM1 SG_ 975 HBFS_FH_Oeffnung 1000;
BA_REL_ "GenSigTimeoutTime" BU_SG_REL_ BCM2 SG_ 975 HBFS_FH_Oeffnung 1000;
BA_REL_ "GenSigTimeoutTime" BU_SG_REL_ Gateway SG_ 975 HBFS_FH_Oeffnung 1000;
BA_REL_ "GenSigTimeoutTime" BU_SG_REL_ MFG SG_ 975 HBFS_FH_Oeffnung 1000;
BA_REL_ "GenSigTimeoutTime" BU_SG_REL_ SAD SG_ 975 HBFS_FH_Oeffnung 1000;
BA_REL_ "GenSigTimeoutTime" BU_SG_REL_ SAD2 SG_ 975 HBFS_FH_Oeffnung 1000;
BA_REL_ "GenSigTimeoutTime" BU_SG_REL_ VSG SG_ 975 HBFS_FH_Oeffnung 1000;
BA_REL_ "GenSigTimeoutTime" BU_SG_REL_ VTS SG_ 975 HBFS_FH_Oeffnung 1000;
BA_REL_ "GenSigTimeoutTime" BU_SG_REL_ MFG SG_ 975 HBFS_FH_Bew_hoch 1000;
BA_REL_ "GenSigTimeoutTime" BU_SG_REL_ TSG_FS SG_ 975 HBFS_FH_Bew_hoch 1000;
BA_REL_ "GenSigTimeoutTime" BU_SG_REL_ VSG SG_ 975 HBFS_FH_Bew_hoch 1000;
BA_REL_ "GenSigTimeoutTime" BU_SG_REL_ MFG SG_ 975 HBFS_FH_Bew_tief 1000;
BA_REL_ "GenSigTimeoutTime" BU_SG_REL_ TSG_FS SG_ 975 HBFS_FH_Bew_tief 1000;
BA_REL_ "GenSigTimeoutTime" BU_SG_REL_ Gateway SG_ 975 HBFS_FH_Fang 1000;
BA_REL_ "GenSigTimeoutTime" BU_SG_REL_ MFG SG_ 975 HBFS_FH_Fang 1000;
BA_REL_ "GenSigTimeoutTime" BU_SG_REL_ MFG SG_ 975 HBFS_FH_Block 1000;
BA_REL_ "GenSigTimeoutTime" BU_SG_REL_ BCM2 SG_ 975 HBFS_FH_Thermo 1000;
BA_REL_ "GenSigTimeoutTime" BU_SG_REL_ MFG SG_ 975 HBFS_FH_Thermo 1000;
BA_REL_ "GenSigTimeoutTime" BU_SG_REL_ BCM2 SG_ 975 HBFS_UEKB_aktiviert 1000;
BA_REL_ "GenSigTimeoutTime" BU_SG_REL_ MFG SG_ 975 HBFS_UEKB_aktiviert 1000;
BA_REL_ "GenSigTimeoutTime" BU_SG_REL_ BCM2 SG_ 975 HBFS_FH_normiert 1000;
BA_REL_ "GenSigTimeoutTime" BU_SG_REL_ Gateway SG_ 975 HBFS_FH_normiert 1000;
BA_REL_ "GenSigTimeoutTime" BU_SG_REL_ MFG SG_ 975 HBFS_FH_normiert 1000;
BA_REL_ "GenSigTimeoutTime" BU_SG_REL_ TSG_FS SG_ 975 HBFS_FH_normiert 1000;
BA_REL_ "GenSigTimeoutTime" BU_SG_REL_ VSG SG_ 975 HBFS_FH_normiert 1000;
BA_REL_ "GenSigTimeoutTime" BU_SG_REL_ VTS SG_ 975 HBFS_FH_normiert 1000;
BA_REL_ "GenSigTimeoutTime" BU_SG_REL_ BCM1 SG_ 975 ASW_Warnung_aktiv_HBFS 1000;
BA_REL_ "GenSigTimeoutTime" BU_SG_REL_ MFG SG_ 975 HBFS_Zuziehhilfe_aktiv 1000;
BA_REL_ "GenSigTimeoutTime" BU_SG_REL_ MFG SG_ 975 HBFS_Seitenrollo_hoch 1000;
BA_REL_ "GenSigTimeoutTime" BU_SG_REL_ MFG SG_ 975 HBFS_Seitenrollo_tief 1000;
BA_REL_ "GenSigTimeoutTime" BU_SG_REL_ MFG SG_ 975 HBFS_Status_KiSi 1000;
BA_REL_ "GenSigTimeoutTime" BU_SG_REL_ TSG_FS SG_ 975 HBFS_Status_KiSi 1000;
BA_REL_ "GenSigTimeoutTime" BU_SG_REL_ TSG_FS SG_ 975 SSR_HBFS_Pos_Unten 1000;
BA_REL_ "GenSigTimeoutTime" BU_SG_REL_ MFG SG_ 975 HBFS_Oben_Block_erw 1000;
BA_REL_ "GenSigTimeoutTime" BU_SG_REL_ TSG_FS SG_ 975 HBFS_Oben_Block_erw 1000;
BA_REL_ "GenSigTimeoutTime" BU_SG_REL_ MFG SG_ 975 HBFS_Unten_Block_erw 1000;
BA_REL_ "GenSigTimeoutTime" BU_SG_REL_ TSG_FS SG_ 975 HBFS_Unten_Block_erw 1000;
BA_REL_ "GenSigTimeoutTime" BU_SG_REL_ SitzMem_FS SG_ 975 MTHBFS_M_Taste 1000;
BA_REL_ "GenSigTimeoutTime" BU_SG_REL_ SitzMem_HBFS SG_ 975 MTHBFS_M_Taste 1000;
BA_REL_ "GenSigTimeoutTime" BU_SG_REL_ SitzMem_FS SG_ 975 MTHBFS_Pos1 1000;
BA_REL_ "GenSigTimeoutTime" BU_SG_REL_ SitzMem_FS SG_ 975 MTHBFS_Pos2 1000;
BA_REL_ "GenSigTimeoutTime" BU_SG_REL_ SitzMem_HBFS SG_ 975 MTHBFS_Pos2 1000;
BA_REL_ "GenSigTimeoutTime" BU_SG_REL_ SitzMem_FS SG_ 975 MTHBFS_Pos3 1000;
BA_REL_ "GenSigTimeoutTime" BU_SG_REL_ SitzMem_HBFS SG_ 975 MTHBFS_Pos3 1000;
BA_REL_ "GenSigTimeoutTime" BU_SG_REL_ BCM2 SG_ 975 HBFS_MRollo_Schalter 1000;
BA_REL_ "GenSigTimeoutTime" BU_SG_REL_ SAD SG_ 975 HBFS_MRollo_Schalter 1000;
BA_REL_ "GenSigTimeoutTime" BU_SG_REL_ BCM2 SG_ 975 HBFS_Lock_Taster_inv 1000;
BA_REL_ "GenSigTimeoutTime" BU_SG_REL_ TSG_FS SG_ 975 HBFS_Status_KiSi_inv 1000;
BA_REL_ "GenSigTimeoutTime" BU_SG_REL_ BCM1 SG_ 1457 TSG_FlHz_HBFS_NTC_A 5000;
BA_REL_ "GenSigTimeoutTime" BU_SG_REL_ BCM1 SG_ 1457 TSG_FlHz_HBFS_FnAbbruchHzKreis_A 5000;
BA_REL_ "GenSigTimeoutTime" BU_SG_REL_ BCM1 SG_ 1457 TSG_FlHz_HBFS_NTC_B 5000;
BA_REL_ "GenSigTimeoutTime" BU_SG_REL_ BCM1 SG_ 1457 TSG_FlHz_HBFS_FnAbbruchHzKreis_B 5000;
BA_REL_ "GenSigTimeoutTime" BU_SG_REL_ BCM2 SG_ 974 HFS_Tuer_geoeffnet 1000;
BA_REL_ "GenSigTimeoutTime" BU_SG_REL_ Gateway SG_ 974 HFS_Tuer_geoeffnet 1000;
BA_REL_ "GenSigTimeoutTime" BU_SG_REL_ IEZS SG_ 974 HFS_Tuer_geoeffnet 1000;
BA_REL_ "GenSigTimeoutTime" BU_SG_REL_ MFG SG_ 974 HFS_Tuer_geoeffnet 1000;
BA_REL_ "GenSigTimeoutTime" BU_SG_REL_ SitzMem_FS SG_ 974 HFS_Tuer_geoeffnet 1000;
BA_REL_ "GenSigTimeoutTime" BU_SG_REL_ SitzMem_HFS SG_ 974 HFS_Tuer_geoeffnet 1000;
BA_REL_ "GenSigTimeoutTime" BU_SG_REL_ SitzMem_SR3 SG_ 974 HFS_Tuer_geoeffnet 1000;
BA_REL_ "GenSigTimeoutTime" BU_SG_REL_ VTS SG_ 974 HFS_Tuer_geoeffnet 1000;
BA_REL_ "GenSigTimeoutTime" BU_SG_REL_ BCM2 SG_ 974 HFS_verriegelt 1000;
BA_REL_ "GenSigTimeoutTime" BU_SG_REL_ Gateway SG_ 974 HFS_verriegelt 1000;
BA_REL_ "GenSigTimeoutTime" BU_SG_REL_ MFG SG_ 974 HFS_verriegelt 1000;
BA_REL_ "GenSigTimeoutTime" BU_SG_REL_ SitzMem_SR3 SG_ 974 HFS_verriegelt 1000;
BA_REL_ "GenSigTimeoutTime" BU_SG_REL_ VTS SG_ 974 HFS_verriegelt 1000;
BA_REL_ "GenSigTimeoutTime" BU_SG_REL_ BCM2 SG_ 974 HFS_gesafet 1000;
BA_REL_ "GenSigTimeoutTime" BU_SG_REL_ Gateway SG_ 974 HFS_gesafet 1000;
BA_REL_ "GenSigTimeoutTime" BU_SG_REL_ MFG SG_ 974 HFS_gesafet 1000;
BA_REL_ "GenSigTimeoutTime" BU_SG_REL_ TSG_BFS SG_ 974 HFS_gesafet 1000;
BA_REL_ "GenSigTimeoutTime" BU_SG_REL_ VTS SG_ 974 HFS_gesafet 1000;
BA_REL_ "GenSigTimeoutTime" BU_SG_REL_ BCM2 SG_ 974 HFS_Heckrollotaster_betaetigt 1000;
BA_REL_ "GenSigTimeoutTime" BU_SG_REL_ BCM2 SG_ 974 HFS_Tuerschloss_defekt 1000;
BA_REL_ "GenSigTimeoutTime" BU_SG_REL_ BCM2 SG_ 974 HFS_Unlock_Taster 1000;
BA_REL_ "GenSigTimeoutTime" BU_SG_REL_ MFG SG_ 974 HFS_Unlock_Taster 1000;
BA_REL_ "GenSigTimeoutTime" BU_SG_REL_ BCM2 SG_ 974 HFS_Lock_Taster 1000;
BA_REL_ "GenSigTimeoutTime" BU_SG_REL_ MFG SG_ 974 HFS_Lock_Taster 1000;
BA_REL_ "GenSigTimeoutTime" BU_SG_REL_ BCM2 SG_ 974 HFS_Sperrklinke 1000;
BA_REL_ "GenSigTimeoutTime" BU_SG_REL_ MFG SG_ 974 HFS_Sperrklinke 1000;
BA_REL_ "GenSigTimeoutTime" BU_SG_REL_ MFG SG_ 974 HFS_TAG_betaetigt 1000;
BA_REL_ "GenSigTimeoutTime" BU_SG_REL_ VTS SG_ 974 HFS_TAG_betaetigt 1000;
BA_REL_ "GenSigTimeoutTime" BU_SG_REL_ BCM1 SG_ 974 HFS_TIG_betaetigt 1000;
BA_REL_ "GenSigTimeoutTime" BU_SG_REL_ BCM2 SG_ 974 HFS_TIG_betaetigt 1000;
BA_REL_ "GenSigTimeoutTime" BU_SG_REL_ MFG SG_ 974 HFS_TIG_betaetigt 1000;
BA_REL_ "GenSigTimeoutTime" BU_SG_REL_ MFG SG_ 974 HFS_FH_S_HBFS_AutoHoch 1000;
BA_REL_ "GenSigTimeoutTime" BU_SG_REL_ TSG_BFS SG_ 974 HFS_FH_S_HBFS_AutoHoch 1000;
BA_REL_ "GenSigTimeoutTime" BU_SG_REL_ MFG SG_ 974 HFS_FH_S_HBFS_AutoTief 1000;
BA_REL_ "GenSigTimeoutTime" BU_SG_REL_ TSG_BFS SG_ 974 HFS_FH_S_HBFS_AutoTief 1000;
BA_REL_ "GenSigTimeoutTime" BU_SG_REL_ MFG SG_ 974 HFS_FH_S_HBFS_ManHoch 1000;
BA_REL_ "GenSigTimeoutTime" BU_SG_REL_ TSG_BFS SG_ 974 HFS_FH_S_HBFS_ManHoch 1000;
BA_REL_ "GenSigTimeoutTime" BU_SG_REL_ MFG SG_ 974 HFS_FH_S_HBFS_ManTief 1000;
BA_REL_ "GenSigTimeoutTime" BU_SG_REL_ TSG_BFS SG_ 974 HFS_FH_S_HBFS_ManTief 1000;
BA_REL_ "GenSigTimeoutTime" BU_SG_REL_ BCM2 SG_ 974 HFS_SAD_Schalter 1000;
BA_REL_ "GenSigTimeoutTime" BU_SG_REL_ SAD SG_ 974 HFS_SAD_Schalter 1000;
BA_REL_ "GenSigTimeoutTime" BU_SG_REL_ BCM2 SG_ 974 HFS_FH_S_ManHoch 1000;
BA_REL_ "GenSigTimeoutTime" BU_SG_REL_ BCM2 SG_ 974 HFS_FH_S_AutoHoch 1000;
BA_REL_ "GenSigTimeoutTime" BU_SG_REL_ BCM2 SG_ 974 HFS_FH_S_ManTief 1000;
BA_REL_ "GenSigTimeoutTime" BU_SG_REL_ BCM2 SG_ 974 HFS_FH_S_AutoTief 1000;
BA_REL_ "GenSigTimeoutTime" BU_SG_REL_ BCM1 SG_ 974 HFS_FH_Oeffnung 1000;
BA_REL_ "GenSigTimeoutTime" BU_SG_REL_ BCM2 SG_ 974 HFS_FH_Oeffnung 1000;
BA_REL_ "GenSigTimeoutTime" BU_SG_REL_ Gateway SG_ 974 HFS_FH_Oeffnung 1000;
BA_REL_ "GenSigTimeoutTime" BU_SG_REL_ MFG SG_ 974 HFS_FH_Oeffnung 1000;
BA_REL_ "GenSigTimeoutTime" BU_SG_REL_ SAD SG_ 974 HFS_FH_Oeffnung 1000;
BA_REL_ "GenSigTimeoutTime" BU_SG_REL_ SAD2 SG_ 974 HFS_FH_Oeffnung 1000;
BA_REL_ "GenSigTimeoutTime" BU_SG_REL_ VSG SG_ 974 HFS_FH_Oeffnung 1000;
BA_REL_ "GenSigTimeoutTime" BU_SG_REL_ VTS SG_ 974 HFS_FH_Oeffnung 1000;
BA_REL_ "GenSigTimeoutTime" BU_SG_REL_ MFG SG_ 974 HFS_FH_Bew_hoch 1000;
BA_REL_ "GenSigTimeoutTime" BU_SG_REL_ TSG_BFS SG_ 974 HFS_FH_Bew_hoch 1000;
BA_REL_ "GenSigTimeoutTime" BU_SG_REL_ VSG SG_ 974 HFS_FH_Bew_hoch 1000;
BA_REL_ "GenSigTimeoutTime" BU_SG_REL_ MFG SG_ 974 HFS_FH_Bew_tief 1000;
BA_REL_ "GenSigTimeoutTime" BU_SG_REL_ TSG_BFS SG_ 974 HFS_FH_Bew_tief 1000;
BA_REL_ "GenSigTimeoutTime" BU_SG_REL_ Gateway SG_ 974 HFS_FH_Fang 1000;
BA_REL_ "GenSigTimeoutTime" BU_SG_REL_ MFG SG_ 974 HFS_FH_Fang 1000;
BA_REL_ "GenSigTimeoutTime" BU_SG_REL_ MFG SG_ 974 HFS_FH_Block 1000;
BA_REL_ "GenSigTimeoutTime" BU_SG_REL_ BCM2 SG_ 974 HFS_FH_Thermo 1000;
BA_REL_ "GenSigTimeoutTime" BU_SG_REL_ MFG SG_ 974 HFS_FH_Thermo 1000;
BA_REL_ "GenSigTimeoutTime" BU_SG_REL_ BCM2 SG_ 974 HFS_UEKB_aktiviert 1000;
BA_REL_ "GenSigTimeoutTime" BU_SG_REL_ MFG SG_ 974 HFS_UEKB_aktiviert 1000;
BA_REL_ "GenSigTimeoutTime" BU_SG_REL_ BCM2 SG_ 974 HFS_FH_normiert 1000;
BA_REL_ "GenSigTimeoutTime" BU_SG_REL_ Gateway SG_ 974 HFS_FH_normiert 1000;
BA_REL_ "GenSigTimeoutTime" BU_SG_REL_ MFG SG_ 974 HFS_FH_normiert 1000;
BA_REL_ "GenSigTimeoutTime" BU_SG_REL_ VSG SG_ 974 HFS_FH_normiert 1000;
BA_REL_ "GenSigTimeoutTime" BU_SG_REL_ VTS SG_ 974 HFS_FH_normiert 1000;
BA_REL_ "GenSigTimeoutTime" BU_SG_REL_ BCM1 SG_ 974 ASW_Warnung_aktiv_HFS 1000;
BA_REL_ "GenSigTimeoutTime" BU_SG_REL_ MFG SG_ 974 HFS_Zuziehhilfe_aktiv 1000;
BA_REL_ "GenSigTimeoutTime" BU_SG_REL_ MFG SG_ 974 HFS_Seitenrollo_hoch 1000;
BA_REL_ "GenSigTimeoutTime" BU_SG_REL_ MFG SG_ 974 HFS_Seitenrollo_tief 1000;
BA_REL_ "GenSigTimeoutTime" BU_SG_REL_ MFG SG_ 974 HFS_Status_KiSi 1000;
BA_REL_ "GenSigTimeoutTime" BU_SG_REL_ TSG_BFS SG_ 974 HFS_Status_KiSi 1000;
BA_REL_ "GenSigTimeoutTime" BU_SG_REL_ TSG_BFS SG_ 974 SSR_HFS_Pos_Unten 1000;
BA_REL_ "GenSigTimeoutTime" BU_SG_REL_ MFG SG_ 974 HFS_Oben_Block_erw 1000;
BA_REL_ "GenSigTimeoutTime" BU_SG_REL_ TSG_BFS SG_ 974 HFS_Oben_Block_erw 1000;
BA_REL_ "GenSigTimeoutTime" BU_SG_REL_ MFG SG_ 974 HFS_Unten_Block_erw 1000;
BA_REL_ "GenSigTimeoutTime" BU_SG_REL_ TSG_BFS SG_ 974 HFS_Unten_Block_erw 1000;
BA_REL_ "GenSigTimeoutTime" BU_SG_REL_ SitzMem_FS SG_ 974 MTHFS_M_Taste 1000;
BA_REL_ "GenSigTimeoutTime" BU_SG_REL_ SitzMem_HFS SG_ 974 MTHFS_M_Taste 1000;
BA_REL_ "GenSigTimeoutTime" BU_SG_REL_ SitzMem_FS SG_ 974 MTHFS_Pos1 1000;
BA_REL_ "GenSigTimeoutTime" BU_SG_REL_ SitzMem_HFS SG_ 974 MTHFS_Pos1 1000;
BA_REL_ "GenSigTimeoutTime" BU_SG_REL_ SitzMem_FS SG_ 974 MTHFS_Pos2 1000;
BA_REL_ "GenSigTimeoutTime" BU_SG_REL_ SitzMem_HFS SG_ 974 MTHFS_Pos2 1000;
BA_REL_ "GenSigTimeoutTime" BU_SG_REL_ SitzMem_FS SG_ 974 MTHFS_Pos3 1000;
BA_REL_ "GenSigTimeoutTime" BU_SG_REL_ SitzMem_HFS SG_ 974 MTHFS_Pos3 1000;
BA_REL_ "GenSigTimeoutTime" BU_SG_REL_ BCM2 SG_ 974 HFS_MRollo_Schalter 1000;
BA_REL_ "GenSigTimeoutTime" BU_SG_REL_ SAD SG_ 974 HFS_MRollo_Schalter 1000;
BA_REL_ "GenSigTimeoutTime" BU_SG_REL_ BCM2 SG_ 974 HFS_Lock_Taster_inv 1000;
BA_REL_ "GenSigTimeoutTime" BU_SG_REL_ BCM1 SG_ 1458 TSG_FlHz_HFS_NTC_A 5000;
BA_REL_ "GenSigTimeoutTime" BU_SG_REL_ BCM1 SG_ 1458 TSG_FlHz_HFS_FnAbbruchHzKreis_A 5000;
BA_REL_ "GenSigTimeoutTime" BU_SG_REL_ BCM1 SG_ 1458 TSG_FlHz_HFS_NTC_B 5000;
BA_REL_ "GenSigTimeoutTime" BU_SG_REL_ BCM1 SG_ 1458 TSG_FlHz_HFS_FnAbbruchHzKreis_B 5000;
BA_REL_ "GenSigTimeoutTime" BU_SG_REL_ BCM1 SG_ 346 TSK_Status_PLA 1000;
BA_REL_ "GenSigTimeoutTime" BU_SG_REL_ BCM1 SG_ 346 TSK_aktives_System 1000;
BA_REL_ "GenSigTimeoutTime" BU_SG_REL_ BCM1 SG_ 346 TSK_Status_ARA 1000;
BA_REL_ "GenSigTimeoutTime" BU_SG_REL_ BCM1 SG_ 995 VS_VD_zu_ver 1000;
BA_REL_ "GenSigTimeoutTime" BU_SG_REL_ BCM2 SG_ 995 VS_VD_zu_ver 1000;
BA_REL_ "GenSigTimeoutTime" BU_SG_REL_ Gateway SG_ 995 VS_VD_zu_ver 1000;
BA_REL_ "GenSigTimeoutTime" BU_SG_REL_ SpoilerSG SG_ 995 VS_VD_zu_ver 1000;
BA_REL_ "GenSigTimeoutTime" BU_SG_REL_ TSG_BFS SG_ 995 VS_VD_zu_ver 1000;
BA_REL_ "GenSigTimeoutTime" BU_SG_REL_ TSG_FS SG_ 995 VS_VD_zu_ver 1000;
BA_REL_ "GenSigTimeoutTime" BU_SG_REL_ BCM2 SG_ 995 VS_VD_entriegelt 1000;
BA_REL_ "GenSigTimeoutTime" BU_SG_REL_ Gateway SG_ 995 VS_VD_entriegelt 1000;
BA_REL_ "GenSigTimeoutTime" BU_SG_REL_ TSG_BFS SG_ 995 VS_VD_entriegelt 1000;
BA_REL_ "GenSigTimeoutTime" BU_SG_REL_ TSG_FS SG_ 995 VS_VD_entriegelt 1000;
BA_REL_ "GenSigTimeoutTime" BU_SG_REL_ BCM1 SG_ 995 VS_VD_offen_ver 1000;
BA_REL_ "GenSigTimeoutTime" BU_SG_REL_ BCM2 SG_ 995 VS_VD_offen_ver 1000;
BA_REL_ "GenSigTimeoutTime" BU_SG_REL_ Gateway SG_ 995 VS_VD_offen_ver 1000;
BA_REL_ "GenSigTimeoutTime" BU_SG_REL_ TSG_BFS SG_ 995 VS_VD_offen_ver 1000;
BA_REL_ "GenSigTimeoutTime" BU_SG_REL_ TSG_FS SG_ 995 VS_VD_offen_ver 1000;
BA_REL_ "GenSigTimeoutTime" BU_SG_REL_ BCM2 SG_ 995 VS_VD_Zwischenposition 1000;
BA_REL_ "GenSigTimeoutTime" BU_SG_REL_ Gateway SG_ 995 VS_VD_Zwischenposition 1000;
BA_REL_ "GenSigTimeoutTime" BU_SG_REL_ TSG_BFS SG_ 995 VS_VD_Zwischenposition 1000;
BA_REL_ "GenSigTimeoutTime" BU_SG_REL_ TSG_FS SG_ 995 VS_VD_Zwischenposition 1000;
BA_REL_ "GenSigTimeoutTime" BU_SG_REL_ TSG_BFS SG_ 995 VS_VD_Bew_auf 1000;
BA_REL_ "GenSigTimeoutTime" BU_SG_REL_ TSG_FS SG_ 995 VS_VD_Bew_auf 1000;
BA_REL_ "GenSigTimeoutTime" BU_SG_REL_ TSG_BFS SG_ 995 VS_VD_Bew_zu 1000;
BA_REL_ "GenSigTimeoutTime" BU_SG_REL_ TSG_FS SG_ 995 VS_VD_Bew_zu 1000;
BA_REL_ "GenSigTimeoutTime" BU_SG_REL_ AAG SG_ 995 VS_Verdeck_Anf 1000;
BA_REL_ "GenSigTimeoutTime" BU_SG_REL_ BCM2 SG_ 995 VS_Verdeck_Anf 1000;
BA_REL_ "GenSigTimeoutTime" BU_SG_REL_ Gateway SG_ 995 VS_Verdeck_Anf 1000;
BA_REL_ "GenSigTimeoutTime" BU_SG_REL_ BCM1 SG_ 995 VS_Hardtop 1000;
BA_REL_ "GenSigTimeoutTime" BU_SG_REL_ Gateway SG_ 995 VS_Hardtop 1000;
BA_REL_ "GenSigTimeoutTime" BU_SG_REL_ TSG_BFS SG_ 995 VS_Hardtop 1000;
BA_REL_ "GenSigTimeoutTime" BU_SG_REL_ TSG_FS SG_ 995 VS_Hardtop 1000;
BA_REL_ "GenSigTimeoutTime" BU_SG_REL_ Gateway SG_ 995 VS_VD_Fehler 1000;
BA_REL_ "GenSigTimeoutTime" BU_SG_REL_ BCM2 SG_ 995 VS_HD_sperren 1000;
BA_REL_ "GenSigTimeoutTime" BU_SG_REL_ BCM2 SG_ 995 VS_HHS_enable 1000;
BA_REL_ "GenSigTimeoutTime" BU_SG_REL_ TSG_FS SG_ 995 ZFH_FS_AutoHoch 1000;
BA_REL_ "GenSigTimeoutTime" BU_SG_REL_ TSG_FS SG_ 995 ZFH_FS_AutoTief 1000;
BA_REL_ "GenSigTimeoutTime" BU_SG_REL_ TSG_FS SG_ 995 ZFH_FS_ManHoch 1000;
BA_REL_ "GenSigTimeoutTime" BU_SG_REL_ TSG_FS SG_ 995 ZFH_FS_ManTief 1000;
BA_REL_ "GenSigTimeoutTime" BU_SG_REL_ TSG_BFS SG_ 995 ZFH_BFS_AutoHoch 1000;
BA_REL_ "GenSigTimeoutTime" BU_SG_REL_ TSG_BFS SG_ 995 ZFH_BFS_AutoTief 1000;
BA_REL_ "GenSigTimeoutTime" BU_SG_REL_ TSG_BFS SG_ 995 ZFH_BFS_ManHoch 1000;
BA_REL_ "GenSigTimeoutTime" BU_SG_REL_ TSG_BFS SG_ 995 ZFH_BFS_ManTief 1000;
BA_REL_ "GenSigTimeoutTime" BU_SG_REL_ TSG_FS SG_ 995 ZFH_HFS_AutoHoch 1000;
BA_REL_ "GenSigTimeoutTime" BU_SG_REL_ TSG_FS SG_ 995 ZFH_HFS_AutoTief 1000;
BA_REL_ "GenSigTimeoutTime" BU_SG_REL_ TSG_FS SG_ 995 ZFH_HFS_ManHoch 1000;
BA_REL_ "GenSigTimeoutTime" BU_SG_REL_ TSG_FS SG_ 995 ZFH_HFS_ManTief 1000;
BA_REL_ "GenSigTimeoutTime" BU_SG_REL_ TSG_BFS SG_ 995 ZFH_HBFS_AutoHoch 1000;
BA_REL_ "GenSigTimeoutTime" BU_SG_REL_ TSG_BFS SG_ 995 ZFH_HBFS_AutoTief 1000;
BA_REL_ "GenSigTimeoutTime" BU_SG_REL_ TSG_BFS SG_ 995 ZFH_HBFS_ManHoch 1000;
BA_REL_ "GenSigTimeoutTime" BU_SG_REL_ TSG_BFS SG_ 995 ZFH_HBFS_ManTief 1000;
BA_REL_ "GenSigTimeoutTime" BU_SG_REL_ TSG_FS SG_ 995 VS_FH_FT_Langhub 1000;
BA_REL_ "GenSigTimeoutTime" BU_SG_REL_ TSG_BFS SG_ 995 VS_FH_BT_Langhub 1000;
BA_REL_ "GenSigTimeoutTime" BU_SG_REL_ TSG_FS SG_ 995 VS_FH_HFS_Langhub 1000;
BA_REL_ "GenSigTimeoutTime" BU_SG_REL_ TSG_BFS SG_ 995 VS_FH_HBFS_Langhub 1000;
BA_REL_ "GenSigTimeoutTime" BU_SG_REL_ BCM1 SG_ 995 VSG_Meldungen 1000;
BA_REL_ "GenSigTimeoutTime" BU_SG_REL_ BCM1 SG_ 1716 VIN_01_MUX 2000;
BA_REL_ "GenSigTimeoutTime" BU_SG_REL_ Gateway SG_ 1716 VIN_01_MUX 2000;
BA_REL_ "GenSigTimeoutTime" BU_SG_REL_ HDSG SG_ 1716 VIN_01_MUX 2000;
BA_REL_ "GenSigTimeoutTime" BU_SG_REL_ MFG SG_ 1716 VIN_01_MUX 2000;
BA_REL_ "GenSigTimeoutTime" BU_SG_REL_ SAD SG_ 1716 VIN_01_MUX 2000;
BA_REL_ "GenSigTimeoutTime" BU_SG_REL_ SAD2 SG_ 1716 VIN_01_MUX 2000;
BA_REL_ "GenSigTimeoutTime" BU_SG_REL_ TSG_BFS SG_ 1716 VIN_01_MUX 2000;
BA_REL_ "GenSigTimeoutTime" BU_SG_REL_ TSG_FS SG_ 1716 VIN_01_MUX 2000;
BA_REL_ "GenSigTimeoutTime" BU_SG_REL_ VSG SG_ 1716 VIN_01_MUX 2000;
BA_REL_ "GenSigTimeoutTime" BU_SG_REL_ VTS SG_ 1716 VIN_01_MUX 2000;
BA_REL_ "GenSigTimeoutTime" BU_SG_REL_ BCM1 SG_ 1716 VIN_4 2000;
BA_REL_ "GenSigTimeoutTime" BU_SG_REL_ Gateway SG_ 1716 VIN_4 2000;
BA_REL_ "GenSigTimeoutTime" BU_SG_REL_ HDSG SG_ 1716 VIN_4 2000;
BA_REL_ "GenSigTimeoutTime" BU_SG_REL_ MFG SG_ 1716 VIN_4 2000;
BA_REL_ "GenSigTimeoutTime" BU_SG_REL_ SAD SG_ 1716 VIN_4 2000;
BA_REL_ "GenSigTimeoutTime" BU_SG_REL_ SAD2 SG_ 1716 VIN_4 2000;
BA_REL_ "GenSigTimeoutTime" BU_SG_REL_ TSG_BFS SG_ 1716 VIN_4 2000;
BA_REL_ "GenSigTimeoutTime" BU_SG_REL_ TSG_FS SG_ 1716 VIN_4 2000;
BA_REL_ "GenSigTimeoutTime" BU_SG_REL_ VSG SG_ 1716 VIN_4 2000;
BA_REL_ "GenSigTimeoutTime" BU_SG_REL_ VTS SG_ 1716 VIN_4 2000;
BA_REL_ "GenSigTimeoutTime" BU_SG_REL_ BCM1 SG_ 1716 VIN_11 2000;
BA_REL_ "GenSigTimeoutTime" BU_SG_REL_ Gateway SG_ 1716 VIN_11 2000;
BA_REL_ "GenSigTimeoutTime" BU_SG_REL_ HDSG SG_ 1716 VIN_11 2000;
BA_REL_ "GenSigTimeoutTime" BU_SG_REL_ MFG SG_ 1716 VIN_11 2000;
BA_REL_ "GenSigTimeoutTime" BU_SG_REL_ SAD SG_ 1716 VIN_11 2000;
BA_REL_ "GenSigTimeoutTime" BU_SG_REL_ SAD2 SG_ 1716 VIN_11 2000;
BA_REL_ "GenSigTimeoutTime" BU_SG_REL_ TSG_BFS SG_ 1716 VIN_11 2000;
BA_REL_ "GenSigTimeoutTime" BU_SG_REL_ TSG_FS SG_ 1716 VIN_11 2000;
BA_REL_ "GenSigTimeoutTime" BU_SG_REL_ VSG SG_ 1716 VIN_11 2000;
BA_REL_ "GenSigTimeoutTime" BU_SG_REL_ VTS SG_ 1716 VIN_11 2000;
BA_REL_ "GenSigTimeoutTime" BU_SG_REL_ BCM1 SG_ 1716 VIN_5 2000;
BA_REL_ "GenSigTimeoutTime" BU_SG_REL_ Gateway SG_ 1716 VIN_5 2000;
BA_REL_ "GenSigTimeoutTime" BU_SG_REL_ HDSG SG_ 1716 VIN_5 2000;
BA_REL_ "GenSigTimeoutTime" BU_SG_REL_ MFG SG_ 1716 VIN_5 2000;
BA_REL_ "GenSigTimeoutTime" BU_SG_REL_ SAD SG_ 1716 VIN_5 2000;
BA_REL_ "GenSigTimeoutTime" BU_SG_REL_ SAD2 SG_ 1716 VIN_5 2000;
BA_REL_ "GenSigTimeoutTime" BU_SG_REL_ TSG_BFS SG_ 1716 VIN_5 2000;
BA_REL_ "GenSigTimeoutTime" BU_SG_REL_ TSG_FS SG_ 1716 VIN_5 2000;
BA_REL_ "GenSigTimeoutTime" BU_SG_REL_ VSG SG_ 1716 VIN_5 2000;
BA_REL_ "GenSigTimeoutTime" BU_SG_REL_ VTS SG_ 1716 VIN_5 2000;
BA_REL_ "GenSigTimeoutTime" BU_SG_REL_ BCM1 SG_ 1716 VIN_12 2000;
BA_REL_ "GenSigTimeoutTime" BU_SG_REL_ Gateway SG_ 1716 VIN_12 2000;
BA_REL_ "GenSigTimeoutTime" BU_SG_REL_ HDSG SG_ 1716 VIN_12 2000;
BA_REL_ "GenSigTimeoutTime" BU_SG_REL_ MFG SG_ 1716 VIN_12 2000;
BA_REL_ "GenSigTimeoutTime" BU_SG_REL_ SAD SG_ 1716 VIN_12 2000;
BA_REL_ "GenSigTimeoutTime" BU_SG_REL_ SAD2 SG_ 1716 VIN_12 2000;
BA_REL_ "GenSigTimeoutTime" BU_SG_REL_ TSG_BFS SG_ 1716 VIN_12 2000;
BA_REL_ "GenSigTimeoutTime" BU_SG_REL_ TSG_FS SG_ 1716 VIN_12 2000;
BA_REL_ "GenSigTimeoutTime" BU_SG_REL_ VSG SG_ 1716 VIN_12 2000;
BA_REL_ "GenSigTimeoutTime" BU_SG_REL_ VTS SG_ 1716 VIN_12 2000;
BA_REL_ "GenSigTimeoutTime" BU_SG_REL_ BCM1 SG_ 1716 VIN_6 2000;
BA_REL_ "GenSigTimeoutTime" BU_SG_REL_ Gateway SG_ 1716 VIN_6 2000;
BA_REL_ "GenSigTimeoutTime" BU_SG_REL_ HDSG SG_ 1716 VIN_6 2000;
BA_REL_ "GenSigTimeoutTime" BU_SG_REL_ MFG SG_ 1716 VIN_6 2000;
BA_REL_ "GenSigTimeoutTime" BU_SG_REL_ SAD SG_ 1716 VIN_6 2000;
BA_REL_ "GenSigTimeoutTime" BU_SG_REL_ SAD2 SG_ 1716 VIN_6 2000;
BA_REL_ "GenSigTimeoutTime" BU_SG_REL_ TSG_BFS SG_ 1716 VIN_6 2000;
BA_REL_ "GenSigTimeoutTime" BU_SG_REL_ TSG_FS SG_ 1716 VIN_6 2000;
BA_REL_ "GenSigTimeoutTime" BU_SG_REL_ VSG SG_ 1716 VIN_6 2000;
BA_REL_ "GenSigTimeoutTime" BU_SG_REL_ VTS SG_ 1716 VIN_6 2000;
BA_REL_ "GenSigTimeoutTime" BU_SG_REL_ BCM1 SG_ 1716 VIN_13 2000;
BA_REL_ "GenSigTimeoutTime" BU_SG_REL_ Gateway SG_ 1716 VIN_13 2000;
BA_REL_ "GenSigTimeoutTime" BU_SG_REL_ HDSG SG_ 1716 VIN_13 2000;
BA_REL_ "GenSigTimeoutTime" BU_SG_REL_ MFG SG_ 1716 VIN_13 2000;
BA_REL_ "GenSigTimeoutTime" BU_SG_REL_ SAD SG_ 1716 VIN_13 2000;
BA_REL_ "GenSigTimeoutTime" BU_SG_REL_ SAD2 SG_ 1716 VIN_13 2000;
BA_REL_ "GenSigTimeoutTime" BU_SG_REL_ TSG_BFS SG_ 1716 VIN_13 2000;
BA_REL_ "GenSigTimeoutTime" BU_SG_REL_ TSG_FS SG_ 1716 VIN_13 2000;
BA_REL_ "GenSigTimeoutTime" BU_SG_REL_ VSG SG_ 1716 VIN_13 2000;
BA_REL_ "GenSigTimeoutTime" BU_SG_REL_ VTS SG_ 1716 VIN_13 2000;
BA_REL_ "GenSigTimeoutTime" BU_SG_REL_ BCM1 SG_ 1716 VIN_7 2000;
BA_REL_ "GenSigTimeoutTime" BU_SG_REL_ Gateway SG_ 1716 VIN_7 2000;
BA_REL_ "GenSigTimeoutTime" BU_SG_REL_ HDSG SG_ 1716 VIN_7 2000;
BA_REL_ "GenSigTimeoutTime" BU_SG_REL_ MFG SG_ 1716 VIN_7 2000;
BA_REL_ "GenSigTimeoutTime" BU_SG_REL_ SAD SG_ 1716 VIN_7 2000;
BA_REL_ "GenSigTimeoutTime" BU_SG_REL_ SAD2 SG_ 1716 VIN_7 2000;
BA_REL_ "GenSigTimeoutTime" BU_SG_REL_ TSG_BFS SG_ 1716 VIN_7 2000;
BA_REL_ "GenSigTimeoutTime" BU_SG_REL_ TSG_FS SG_ 1716 VIN_7 2000;
BA_REL_ "GenSigTimeoutTime" BU_SG_REL_ VSG SG_ 1716 VIN_7 2000;
BA_REL_ "GenSigTimeoutTime" BU_SG_REL_ VTS SG_ 1716 VIN_7 2000;
BA_REL_ "GenSigTimeoutTime" BU_SG_REL_ BCM1 SG_ 1716 VIN_14 2000;
BA_REL_ "GenSigTimeoutTime" BU_SG_REL_ Gateway SG_ 1716 VIN_14 2000;
BA_REL_ "GenSigTimeoutTime" BU_SG_REL_ HDSG SG_ 1716 VIN_14 2000;
BA_REL_ "GenSigTimeoutTime" BU_SG_REL_ MFG SG_ 1716 VIN_14 2000;
BA_REL_ "GenSigTimeoutTime" BU_SG_REL_ SAD SG_ 1716 VIN_14 2000;
BA_REL_ "GenSigTimeoutTime" BU_SG_REL_ SAD2 SG_ 1716 VIN_14 2000;
BA_REL_ "GenSigTimeoutTime" BU_SG_REL_ TSG_BFS SG_ 1716 VIN_14 2000;
BA_REL_ "GenSigTimeoutTime" BU_SG_REL_ TSG_FS SG_ 1716 VIN_14 2000;
BA_REL_ "GenSigTimeoutTime" BU_SG_REL_ VSG SG_ 1716 VIN_14 2000;
BA_REL_ "GenSigTimeoutTime" BU_SG_REL_ VTS SG_ 1716 VIN_14 2000;
BA_REL_ "GenSigTimeoutTime" BU_SG_REL_ BCM1 SG_ 1716 VIN_1 2000;
BA_REL_ "GenSigTimeoutTime" BU_SG_REL_ Gateway SG_ 1716 VIN_1 2000;
BA_REL_ "GenSigTimeoutTime" BU_SG_REL_ HDSG SG_ 1716 VIN_1 2000;
BA_REL_ "GenSigTimeoutTime" BU_SG_REL_ MFG SG_ 1716 VIN_1 2000;
BA_REL_ "GenSigTimeoutTime" BU_SG_REL_ SAD SG_ 1716 VIN_1 2000;
BA_REL_ "GenSigTimeoutTime" BU_SG_REL_ SAD2 SG_ 1716 VIN_1 2000;
BA_REL_ "GenSigTimeoutTime" BU_SG_REL_ TSG_BFS SG_ 1716 VIN_1 2000;
BA_REL_ "GenSigTimeoutTime" BU_SG_REL_ TSG_FS SG_ 1716 VIN_1 2000;
BA_REL_ "GenSigTimeoutTime" BU_SG_REL_ VSG SG_ 1716 VIN_1 2000;
BA_REL_ "GenSigTimeoutTime" BU_SG_REL_ VTS SG_ 1716 VIN_1 2000;
BA_REL_ "GenSigTimeoutTime" BU_SG_REL_ BCM1 SG_ 1716 VIN_8 2000;
BA_REL_ "GenSigTimeoutTime" BU_SG_REL_ Gateway SG_ 1716 VIN_8 2000;
BA_REL_ "GenSigTimeoutTime" BU_SG_REL_ HDSG SG_ 1716 VIN_8 2000;
BA_REL_ "GenSigTimeoutTime" BU_SG_REL_ MFG SG_ 1716 VIN_8 2000;
BA_REL_ "GenSigTimeoutTime" BU_SG_REL_ SAD SG_ 1716 VIN_8 2000;
BA_REL_ "GenSigTimeoutTime" BU_SG_REL_ SAD2 SG_ 1716 VIN_8 2000;
BA_REL_ "GenSigTimeoutTime" BU_SG_REL_ TSG_BFS SG_ 1716 VIN_8 2000;
BA_REL_ "GenSigTimeoutTime" BU_SG_REL_ TSG_FS SG_ 1716 VIN_8 2000;
BA_REL_ "GenSigTimeoutTime" BU_SG_REL_ VSG SG_ 1716 VIN_8 2000;
BA_REL_ "GenSigTimeoutTime" BU_SG_REL_ VTS SG_ 1716 VIN_8 2000;
BA_REL_ "GenSigTimeoutTime" BU_SG_REL_ BCM1 SG_ 1716 VIN_15 2000;
BA_REL_ "GenSigTimeoutTime" BU_SG_REL_ Gateway SG_ 1716 VIN_15 2000;
BA_REL_ "GenSigTimeoutTime" BU_SG_REL_ HDSG SG_ 1716 VIN_15 2000;
BA_REL_ "GenSigTimeoutTime" BU_SG_REL_ MFG SG_ 1716 VIN_15 2000;
BA_REL_ "GenSigTimeoutTime" BU_SG_REL_ SAD SG_ 1716 VIN_15 2000;
BA_REL_ "GenSigTimeoutTime" BU_SG_REL_ SAD2 SG_ 1716 VIN_15 2000;
BA_REL_ "GenSigTimeoutTime" BU_SG_REL_ TSG_BFS SG_ 1716 VIN_15 2000;
BA_REL_ "GenSigTimeoutTime" BU_SG_REL_ TSG_FS SG_ 1716 VIN_15 2000;
BA_REL_ "GenSigTimeoutTime" BU_SG_REL_ VSG SG_ 1716 VIN_15 2000;
BA_REL_ "GenSigTimeoutTime" BU_SG_REL_ VTS SG_ 1716 VIN_15 2000;
BA_REL_ "GenSigTimeoutTime" BU_SG_REL_ BCM1 SG_ 1716 VIN_2 2000;
BA_REL_ "GenSigTimeoutTime" BU_SG_REL_ Gateway SG_ 1716 VIN_2 2000;
BA_REL_ "GenSigTimeoutTime" BU_SG_REL_ HDSG SG_ 1716 VIN_2 2000;
BA_REL_ "GenSigTimeoutTime" BU_SG_REL_ MFG SG_ 1716 VIN_2 2000;
BA_REL_ "GenSigTimeoutTime" BU_SG_REL_ SAD SG_ 1716 VIN_2 2000;
BA_REL_ "GenSigTimeoutTime" BU_SG_REL_ SAD2 SG_ 1716 VIN_2 2000;
BA_REL_ "GenSigTimeoutTime" BU_SG_REL_ TSG_BFS SG_ 1716 VIN_2 2000;
BA_REL_ "GenSigTimeoutTime" BU_SG_REL_ TSG_FS SG_ 1716 VIN_2 2000;
BA_REL_ "GenSigTimeoutTime" BU_SG_REL_ VSG SG_ 1716 VIN_2 2000;
BA_REL_ "GenSigTimeoutTime" BU_SG_REL_ VTS SG_ 1716 VIN_2 2000;
BA_REL_ "GenSigTimeoutTime" BU_SG_REL_ BCM1 SG_ 1716 VIN_9 2000;
BA_REL_ "GenSigTimeoutTime" BU_SG_REL_ Gateway SG_ 1716 VIN_9 2000;
BA_REL_ "GenSigTimeoutTime" BU_SG_REL_ HDSG SG_ 1716 VIN_9 2000;
BA_REL_ "GenSigTimeoutTime" BU_SG_REL_ MFG SG_ 1716 VIN_9 2000;
BA_REL_ "GenSigTimeoutTime" BU_SG_REL_ SAD SG_ 1716 VIN_9 2000;
BA_REL_ "GenSigTimeoutTime" BU_SG_REL_ SAD2 SG_ 1716 VIN_9 2000;
BA_REL_ "GenSigTimeoutTime" BU_SG_REL_ TSG_BFS SG_ 1716 VIN_9 2000;
BA_REL_ "GenSigTimeoutTime" BU_SG_REL_ TSG_FS SG_ 1716 VIN_9 2000;
BA_REL_ "GenSigTimeoutTime" BU_SG_REL_ VSG SG_ 1716 VIN_9 2000;
BA_REL_ "GenSigTimeoutTime" BU_SG_REL_ VTS SG_ 1716 VIN_9 2000;
BA_REL_ "GenSigTimeoutTime" BU_SG_REL_ BCM1 SG_ 1716 VIN_16 2000;
BA_REL_ "GenSigTimeoutTime" BU_SG_REL_ Gateway SG_ 1716 VIN_16 2000;
BA_REL_ "GenSigTimeoutTime" BU_SG_REL_ HDSG SG_ 1716 VIN_16 2000;
BA_REL_ "GenSigTimeoutTime" BU_SG_REL_ MFG SG_ 1716 VIN_16 2000;
BA_REL_ "GenSigTimeoutTime" BU_SG_REL_ SAD SG_ 1716 VIN_16 2000;
BA_REL_ "GenSigTimeoutTime" BU_SG_REL_ SAD2 SG_ 1716 VIN_16 2000;
BA_REL_ "GenSigTimeoutTime" BU_SG_REL_ TSG_BFS SG_ 1716 VIN_16 2000;
BA_REL_ "GenSigTimeoutTime" BU_SG_REL_ TSG_FS SG_ 1716 VIN_16 2000;
BA_REL_ "GenSigTimeoutTime" BU_SG_REL_ VSG SG_ 1716 VIN_16 2000;
BA_REL_ "GenSigTimeoutTime" BU_SG_REL_ VTS SG_ 1716 VIN_16 2000;
BA_REL_ "GenSigTimeoutTime" BU_SG_REL_ BCM1 SG_ 1716 VIN_3 2000;
BA_REL_ "GenSigTimeoutTime" BU_SG_REL_ Gateway SG_ 1716 VIN_3 2000;
BA_REL_ "GenSigTimeoutTime" BU_SG_REL_ HDSG SG_ 1716 VIN_3 2000;
BA_REL_ "GenSigTimeoutTime" BU_SG_REL_ MFG SG_ 1716 VIN_3 2000;
BA_REL_ "GenSigTimeoutTime" BU_SG_REL_ SAD SG_ 1716 VIN_3 2000;
BA_REL_ "GenSigTimeoutTime" BU_SG_REL_ SAD2 SG_ 1716 VIN_3 2000;
BA_REL_ "GenSigTimeoutTime" BU_SG_REL_ TSG_BFS SG_ 1716 VIN_3 2000;
BA_REL_ "GenSigTimeoutTime" BU_SG_REL_ TSG_FS SG_ 1716 VIN_3 2000;
BA_REL_ "GenSigTimeoutTime" BU_SG_REL_ VSG SG_ 1716 VIN_3 2000;
BA_REL_ "GenSigTimeoutTime" BU_SG_REL_ VTS SG_ 1716 VIN_3 2000;
BA_REL_ "GenSigTimeoutTime" BU_SG_REL_ BCM1 SG_ 1716 VIN_10 2000;
BA_REL_ "GenSigTimeoutTime" BU_SG_REL_ Gateway SG_ 1716 VIN_10 2000;
BA_REL_ "GenSigTimeoutTime" BU_SG_REL_ HDSG SG_ 1716 VIN_10 2000;
BA_REL_ "GenSigTimeoutTime" BU_SG_REL_ MFG SG_ 1716 VIN_10 2000;
BA_REL_ "GenSigTimeoutTime" BU_SG_REL_ SAD SG_ 1716 VIN_10 2000;
BA_REL_ "GenSigTimeoutTime" BU_SG_REL_ SAD2 SG_ 1716 VIN_10 2000;
BA_REL_ "GenSigTimeoutTime" BU_SG_REL_ TSG_BFS SG_ 1716 VIN_10 2000;
BA_REL_ "GenSigTimeoutTime" BU_SG_REL_ TSG_FS SG_ 1716 VIN_10 2000;
BA_REL_ "GenSigTimeoutTime" BU_SG_REL_ VSG SG_ 1716 VIN_10 2000;
BA_REL_ "GenSigTimeoutTime" BU_SG_REL_ VTS SG_ 1716 VIN_10 2000;
BA_REL_ "GenSigTimeoutTime" BU_SG_REL_ BCM1 SG_ 1716 VIN_17 2000;
BA_REL_ "GenSigTimeoutTime" BU_SG_REL_ Gateway SG_ 1716 VIN_17 2000;
BA_REL_ "GenSigTimeoutTime" BU_SG_REL_ HDSG SG_ 1716 VIN_17 2000;
BA_REL_ "GenSigTimeoutTime" BU_SG_REL_ MFG SG_ 1716 VIN_17 2000;
BA_REL_ "GenSigTimeoutTime" BU_SG_REL_ SAD SG_ 1716 VIN_17 2000;
BA_REL_ "GenSigTimeoutTime" BU_SG_REL_ SAD2 SG_ 1716 VIN_17 2000;
BA_REL_ "GenSigTimeoutTime" BU_SG_REL_ TSG_BFS SG_ 1716 VIN_17 2000;
BA_REL_ "GenSigTimeoutTime" BU_SG_REL_ TSG_FS SG_ 1716 VIN_17 2000;
BA_REL_ "GenSigTimeoutTime" BU_SG_REL_ VSG SG_ 1716 VIN_17 2000;
BA_REL_ "GenSigTimeoutTime" BU_SG_REL_ VTS SG_ 1716 VIN_17 2000;
BA_REL_ "GenSigTimeoutTime" BU_SG_REL_ SitzMem_FS SG_ 1361 WFS_Schluessel_Fahrberecht 2000;
BA_REL_ "GenSigTimeoutTime" BU_SG_REL_ BCM1 SG_ 1361 WFS_ID_Geb_autorisiert 2000;
BA_REL_ "GenSigTimeoutTime" BU_SG_REL_ TSG_BFS SG_ 1702 Wischer_vorne_aktiv 5000;
BA_REL_ "GenSigTimeoutTime" BU_SG_REL_ TSG_FS SG_ 1702 Wischer_vorne_aktiv 5000;
BA_REL_ "GenSigTimeoutTime" BU_SG_REL_ BCM2 SG_ 1702 Heckwischer_Anforderung 5000;
BA_REL_ "GenSigTimeoutTime" BU_SG_REL_ TSG_BFS SG_ 1702 WWSs_01_upd 5000;
BA_REL_ "GenSigTimeoutTime" BU_SG_REL_ TSG_FS SG_ 1702 WWSs_01_upd 5000;
BA_REL_ "GenSigTimeoutTime" BU_SG_REL_ VTS SG_ 2527679496 WIV_t_min 3200;
BA_REL_ "GenSigTimeoutTime" BU_SG_REL_ VTS SG_ 2527679496 WIV_t_max 3200;
BA_REL_ "GenSigTimeoutTime" BU_SG_REL_ VTS SG_ 2527679496 WIV_W_min 3200;
BA_REL_ "GenSigTimeoutTime" BU_SG_REL_ VTS SG_ 2527679496 WIV_W_max 3200;
BA_REL_ "GenSigTimeoutTime" BU_SG_REL_ MFG SG_ 389 ZFH_FS_ManHoch 500;
BA_REL_ "GenSigTimeoutTime" BU_SG_REL_ MFG SG_ 389 ZFH_FS_AutoHoch 500;
BA_REL_ "GenSigTimeoutTime" BU_SG_REL_ MFG SG_ 389 ZFH_FS_ManTief 500;
BA_REL_ "GenSigTimeoutTime" BU_SG_REL_ MFG SG_ 389 ZFH_FS_AutoTief 500;
BA_REL_ "GenSigTimeoutTime" BU_SG_REL_ MFG SG_ 389 ZFH_BFS_ManHoch 500;
BA_REL_ "GenSigTimeoutTime" BU_SG_REL_ TSG_BFS SG_ 389 ZFH_BFS_ManHoch 500;
BA_REL_ "GenSigTimeoutTime" BU_SG_REL_ MFG SG_ 389 ZFH_BFS_AutoHoch 500;
BA_REL_ "GenSigTimeoutTime" BU_SG_REL_ TSG_BFS SG_ 389 ZFH_BFS_AutoHoch 500;
BA_REL_ "GenSigTimeoutTime" BU_SG_REL_ MFG SG_ 389 ZFH_BFS_ManTief 500;
BA_REL_ "GenSigTimeoutTime" BU_SG_REL_ TSG_BFS SG_ 389 ZFH_BFS_ManTief 500;
BA_REL_ "GenSigTimeoutTime" BU_SG_REL_ MFG SG_ 389 ZFH_BFS_AutoTief 500;
BA_REL_ "GenSigTimeoutTime" BU_SG_REL_ TSG_BFS SG_ 389 ZFH_BFS_AutoTief 500;
BA_REL_ "GenSigTimeoutTime" BU_SG_REL_ MFG SG_ 389 ZFH_HFS_ManHoch 500;
BA_REL_ "GenSigTimeoutTime" BU_SG_REL_ MFG SG_ 389 ZFH_HFS_AutoHoch 500;
BA_REL_ "GenSigTimeoutTime" BU_SG_REL_ MFG SG_ 389 ZFH_HFS_ManTief 500;
BA_REL_ "GenSigTimeoutTime" BU_SG_REL_ MFG SG_ 389 ZFH_HFS_AutoTief 500;
BA_REL_ "GenSigTimeoutTime" BU_SG_REL_ MFG SG_ 389 ZFH_HBFS_ManHoch 500;
BA_REL_ "GenSigTimeoutTime" BU_SG_REL_ TSG_BFS SG_ 389 ZFH_HBFS_ManHoch 500;
BA_REL_ "GenSigTimeoutTime" BU_SG_REL_ MFG SG_ 389 ZFH_HBFS_AutoHoch 500;
BA_REL_ "GenSigTimeoutTime" BU_SG_REL_ TSG_BFS SG_ 389 ZFH_HBFS_AutoHoch 500;
BA_REL_ "GenSigTimeoutTime" BU_SG_REL_ MFG SG_ 389 ZFH_HBFS_ManTief 500;
BA_REL_ "GenSigTimeoutTime" BU_SG_REL_ TSG_BFS SG_ 389 ZFH_HBFS_ManTief 500;
BA_REL_ "GenSigTimeoutTime" BU_SG_REL_ MFG SG_ 389 ZFH_HBFS_AutoTief 500;
BA_REL_ "GenSigTimeoutTime" BU_SG_REL_ TSG_BFS SG_ 389 ZFH_HBFS_AutoTief 500;
BA_REL_ "GenSigTimeoutTime" BU_SG_REL_ TSG_BFS SG_ 389 ZFH_zentral_zu 500;
BA_REL_ "GenSigTimeoutTime" BU_SG_REL_ TSG_BFS SG_ 389 ZFH_zentral_auf 500;
BA_REL_ "GenSigTimeoutTime" BU_SG_REL_ TSG_BFS SG_ 389 Krypt_Signatur 500;
BA_REL_ "GenSigTimeoutTime" BU_SG_REL_ BCM2 SG_ 389 Krypt_Schluesselschalter_auf 500;
BA_REL_ "GenSigTimeoutTime" BU_SG_REL_ TSG_BFS SG_ 389 Krypt_Schluesselschalter_auf 500;
BA_REL_ "GenSigTimeoutTime" BU_SG_REL_ BCM2 SG_ 389 Krypt_Schluesselschalter_zu 500;
BA_REL_ "GenSigTimeoutTime" BU_SG_REL_ TSG_BFS SG_ 389 Krypt_Schluesselschalter_zu 500;
BA_REL_ "GenSigTimeoutTime" BU_SG_REL_ MFG SG_ 392 BT_FH_BT_ManHoch 500;
BA_REL_ "GenSigTimeoutTime" BU_SG_REL_ MFG SG_ 392 BT_FH_BT_AutoHoch 500;
BA_REL_ "GenSigTimeoutTime" BU_SG_REL_ MFG SG_ 392 BT_FH_BT_ManTief 500;
BA_REL_ "GenSigTimeoutTime" BU_SG_REL_ MFG SG_ 392 BT_FH_BT_AutoTief 500;
BA_REL_ "GenSigTimeoutTime" BU_SG_REL_ MFG SG_ 392 BT_FH_FT_ManHoch 500;
BA_REL_ "GenSigTimeoutTime" BU_SG_REL_ TSG_FS SG_ 392 BT_FH_FT_ManHoch 500;
BA_REL_ "GenSigTimeoutTime" BU_SG_REL_ MFG SG_ 392 BT_FH_FT_AutoHoch 500;
BA_REL_ "GenSigTimeoutTime" BU_SG_REL_ TSG_FS SG_ 392 BT_FH_FT_AutoHoch 500;
BA_REL_ "GenSigTimeoutTime" BU_SG_REL_ MFG SG_ 392 BT_FH_FT_ManTief 500;
BA_REL_ "GenSigTimeoutTime" BU_SG_REL_ TSG_FS SG_ 392 BT_FH_FT_ManTief 500;
BA_REL_ "GenSigTimeoutTime" BU_SG_REL_ MFG SG_ 392 BT_FH_FT_AutoTief 500;
BA_REL_ "GenSigTimeoutTime" BU_SG_REL_ TSG_FS SG_ 392 BT_FH_FT_AutoTief 500;
BA_REL_ "GenSigTimeoutTime" BU_SG_REL_ MFG SG_ 392 BT_FH_HFS_ManHoch 500;
BA_REL_ "GenSigTimeoutTime" BU_SG_REL_ TSG_FS SG_ 392 BT_FH_HFS_ManHoch 500;
BA_REL_ "GenSigTimeoutTime" BU_SG_REL_ MFG SG_ 392 BT_FH_HFS_AutoHoch 500;
BA_REL_ "GenSigTimeoutTime" BU_SG_REL_ TSG_FS SG_ 392 BT_FH_HFS_AutoHoch 500;
BA_REL_ "GenSigTimeoutTime" BU_SG_REL_ MFG SG_ 392 BT_FH_HFS_ManTief 500;
BA_REL_ "GenSigTimeoutTime" BU_SG_REL_ TSG_FS SG_ 392 BT_FH_HFS_ManTief 500;
BA_REL_ "GenSigTimeoutTime" BU_SG_REL_ MFG SG_ 392 BT_FH_HFS_AutoTief 500;
BA_REL_ "GenSigTimeoutTime" BU_SG_REL_ TSG_FS SG_ 392 BT_FH_HFS_AutoTief 500;
BA_REL_ "GenSigTimeoutTime" BU_SG_REL_ MFG SG_ 392 BT_FH_HBFS_ManHoch 500;
BA_REL_ "GenSigTimeoutTime" BU_SG_REL_ MFG SG_ 392 BT_FH_HBFS_AutoHoch 500;
BA_REL_ "GenSigTimeoutTime" BU_SG_REL_ MFG SG_ 392 BT_FH_HBFS_ManTief 500;
BA_REL_ "GenSigTimeoutTime" BU_SG_REL_ MFG SG_ 392 BT_FH_HBFS_AutoTief 500;
BA_REL_ "GenSigTimeoutTime" BU_SG_REL_ MFG SG_ 392 BT_SP_hoch 500;
BA_REL_ "GenSigTimeoutTime" BU_SG_REL_ MFG SG_ 392 BT_SP_tief 500;
BA_REL_ "GenSigTimeoutTime" BU_SG_REL_ MFG SG_ 392 BT_SP_links 500;
BA_REL_ "GenSigTimeoutTime" BU_SG_REL_ MFG SG_ 392 BT_SP_rechts 500;
BA_REL_ "GenSigTimeoutTime" BU_SG_REL_ MFG SG_ 392 BT_SP_Garagenstellung 500;
BA_REL_ "GenSigTimeoutTime" BU_SG_REL_ MFG SG_ 392 BT_SP_Fahrstellung 500;
BA_REL_ "GenSigTimeoutTime" BU_SG_REL_ VTS SG_ 392 BT_SP_Fahrstellung 500;
BA_REL_ "GenSigTimeoutTime" BU_SG_REL_ MFG SG_ 392 BT_FH_zentral_zu 500;
BA_REL_ "GenSigTimeoutTime" BU_SG_REL_ TSG_FS SG_ 392 BT_FH_zentral_zu 500;
BA_REL_ "GenSigTimeoutTime" BU_SG_REL_ MFG SG_ 392 BT_FH_zentral_auf 500;
BA_REL_ "GenSigTimeoutTime" BU_SG_REL_ TSG_FS SG_ 392 BT_FH_zentral_auf 500;
BA_REL_ "GenSigTimeoutTime" BU_SG_REL_ BCM1 SG_ 388 ZV_01_CRC 5000;
BA_REL_ "GenSigTimeoutTime" BU_SG_REL_ TSG_FS SG_ 388 ZV_01_CRC 5000;
BA_REL_ "GenSigTimeoutTime" BU_SG_REL_ BCM1 SG_ 388 ZV_01_BZ 5000;
BA_REL_ "GenSigTimeoutTime" BU_SG_REL_ TSG_FS SG_ 388 ZV_01_BZ 5000;
BA_REL_ "GenSigTimeoutTime" BU_SG_REL_ BCM1 SG_ 388 ZV_FT_verriegeln 5000;
BA_REL_ "GenSigTimeoutTime" BU_SG_REL_ Gateway SG_ 388 ZV_FT_verriegeln 5000;
BA_REL_ "GenSigTimeoutTime" BU_SG_REL_ SitzMem_BFS SG_ 388 ZV_FT_verriegeln 5000;
BA_REL_ "GenSigTimeoutTime" BU_SG_REL_ SitzMem_FS SG_ 388 ZV_FT_verriegeln 5000;
BA_REL_ "GenSigTimeoutTime" BU_SG_REL_ TSG_BFS SG_ 388 ZV_FT_verriegeln 5000;
BA_REL_ "GenSigTimeoutTime" BU_SG_REL_ TSG_FS SG_ 388 ZV_FT_verriegeln 5000;
BA_REL_ "GenSigTimeoutTime" BU_SG_REL_ BCM1 SG_ 388 ZV_FT_entriegeln 5000;
BA_REL_ "GenSigTimeoutTime" BU_SG_REL_ Gateway SG_ 388 ZV_FT_entriegeln 5000;
BA_REL_ "GenSigTimeoutTime" BU_SG_REL_ TSG_BFS SG_ 388 ZV_FT_entriegeln 5000;
BA_REL_ "GenSigTimeoutTime" BU_SG_REL_ TSG_FS SG_ 388 ZV_FT_entriegeln 5000;
BA_REL_ "GenSigTimeoutTime" BU_SG_REL_ Gateway SG_ 388 ZV_BT_verriegeln 5000;
BA_REL_ "GenSigTimeoutTime" BU_SG_REL_ TSG_BFS SG_ 388 ZV_BT_verriegeln 5000;
BA_REL_ "GenSigTimeoutTime" BU_SG_REL_ Gateway SG_ 388 ZV_BT_entriegeln 5000;
BA_REL_ "GenSigTimeoutTime" BU_SG_REL_ TSG_BFS SG_ 388 ZV_BT_entriegeln 5000;
BA_REL_ "GenSigTimeoutTime" BU_SG_REL_ TSG_FS SG_ 388 ZV_HFS_verriegeln 5000;
BA_REL_ "GenSigTimeoutTime" BU_SG_REL_ TSG_FS SG_ 388 ZV_HFS_entriegeln 5000;
BA_REL_ "GenSigTimeoutTime" BU_SG_REL_ TSG_BFS SG_ 388 ZV_HBFS_verriegeln 5000;
BA_REL_ "GenSigTimeoutTime" BU_SG_REL_ TSG_BFS SG_ 388 ZV_HBFS_entriegeln 5000;
BA_REL_ "GenSigTimeoutTime" BU_SG_REL_ TSG_BFS SG_ 388 ZV_zentral_safen 5000;
BA_REL_ "GenSigTimeoutTime" BU_SG_REL_ TSG_FS SG_ 388 ZV_zentral_safen 5000;
BA_REL_ "GenSigTimeoutTime" BU_SG_REL_ TSG_BFS SG_ 388 ZV_zentral_entsafen 5000;
BA_REL_ "GenSigTimeoutTime" BU_SG_REL_ TSG_FS SG_ 388 ZV_zentral_entsafen 5000;
BA_REL_ "GenSigTimeoutTime" BU_SG_REL_ TSG_BFS SG_ 388 ZV_Spg_Anklappen 5000;
BA_REL_ "GenSigTimeoutTime" BU_SG_REL_ TSG_FS SG_ 388 ZV_Spg_Anklappen 5000;
BA_REL_ "GenSigTimeoutTime" BU_SG_REL_ AAG SG_ 388 ZV_Softtouch_betaetigt 5000;
BA_REL_ "GenSigTimeoutTime" BU_SG_REL_ BCM1 SG_ 388 ZV_Softtouch_betaetigt 5000;
BA_REL_ "GenSigTimeoutTime" BU_SG_REL_ HDSG SG_ 388 ZV_Softtouch_betaetigt 5000;
BA_REL_ "GenSigTimeoutTime" BU_SG_REL_ TSG_FS SG_ 388 ZV_LED_Steuerung 5000;
BA_REL_ "GenSigTimeoutTime" BU_SG_REL_ TSG_FS SG_ 388 ZV_LED_Uebernahme 5000;
BA_REL_ "GenSigTimeoutTime" BU_SG_REL_ BCM1 SG_ 388 ZV_auf_FT 5000;
BA_REL_ "GenSigTimeoutTime" BU_SG_REL_ TSG_FS SG_ 388 ZV_auf_FT 5000;
BA_REL_ "GenSigTimeoutTime" BU_SG_REL_ TSG_FS SG_ 388 ZV_zu_FT 5000;
BA_REL_ "GenSigTimeoutTime" BU_SG_REL_ BCM1 SG_ 388 ZV_auf_BT 5000;
BA_REL_ "GenSigTimeoutTime" BU_SG_REL_ BCM1 SG_ 388 ZV_auf_Kessy 5000;
BA_REL_ "GenSigTimeoutTime" BU_SG_REL_ TSG_BFS SG_ 388 ZV_auf_Kessy 5000;
BA_REL_ "GenSigTimeoutTime" BU_SG_REL_ TSG_FS SG_ 388 ZV_auf_Kessy 5000;
BA_REL_ "GenSigTimeoutTime" BU_SG_REL_ BCM1 SG_ 388 ZV_zu_Kessy 5000;
BA_REL_ "GenSigTimeoutTime" BU_SG_REL_ TSG_BFS SG_ 388 ZV_zu_Kessy 5000;
BA_REL_ "GenSigTimeoutTime" BU_SG_REL_ TSG_FS SG_ 388 ZV_zu_Kessy 5000;
BA_REL_ "GenSigTimeoutTime" BU_SG_REL_ BCM1 SG_ 388 ZV_auf_Funk 5000;
BA_REL_ "GenSigTimeoutTime" BU_SG_REL_ SitzMem_BFS SG_ 388 ZV_auf_Funk 5000;
BA_REL_ "GenSigTimeoutTime" BU_SG_REL_ SitzMem_FS SG_ 388 ZV_auf_Funk 5000;
BA_REL_ "GenSigTimeoutTime" BU_SG_REL_ TSG_BFS SG_ 388 ZV_auf_Funk 5000;
BA_REL_ "GenSigTimeoutTime" BU_SG_REL_ TSG_FS SG_ 388 ZV_auf_Funk 5000;
BA_REL_ "GenSigTimeoutTime" BU_SG_REL_ BCM1 SG_ 388 ZV_zu_Funk 5000;
BA_REL_ "GenSigTimeoutTime" BU_SG_REL_ TSG_BFS SG_ 388 ZV_zu_Funk 5000;
BA_REL_ "GenSigTimeoutTime" BU_SG_REL_ TSG_FS SG_ 388 ZV_zu_Funk 5000;
BA_REL_ "GenSigTimeoutTime" BU_SG_REL_ AAG SG_ 388 VIP_Sensor_betaetigt 5000;
BA_REL_ "GenSigTimeoutTime" BU_SG_REL_ BCM1 SG_ 388 VIP_Sensor_betaetigt 5000;
BA_REL_ "GenSigTimeoutTime" BU_SG_REL_ HDSG SG_ 388 VIP_Sensor_betaetigt 5000;
BA_REL_ "GenSigTimeoutTime" BU_SG_REL_ BCM1 SG_ 388 ZV_zu_Zeitl_Nachverr 5000;
BA_REL_ "GenSigTimeoutTime" BU_SG_REL_ TSG_BFS SG_ 388 ZV_zu_Zeitl_Nachverr 5000;
BA_REL_ "GenSigTimeoutTime" BU_SG_REL_ TSG_FS SG_ 388 ZV_zu_Zeitl_Nachverr 5000;
BA_REL_ "GenSigTimeoutTime" BU_SG_REL_ VSG SG_ 388 ZV_Verdeck_zu 5000;
BA_REL_ "GenSigTimeoutTime" BU_SG_REL_ VSG SG_ 388 ZV_Verdeck_auf 5000;
BA_REL_ "GenSigTimeoutTime" BU_SG_REL_ TSG_FS SG_ 388 FH_FT_hoch 5000;
BA_REL_ "GenSigTimeoutTime" BU_SG_REL_ TSG_FS SG_ 388 FH_FT_tief 5000;
BA_REL_ "GenSigTimeoutTime" BU_SG_REL_ TSG_BFS SG_ 388 FH_BT_hoch 5000;
BA_REL_ "GenSigTimeoutTime" BU_SG_REL_ TSG_BFS SG_ 388 FH_BT_tief 5000;
BA_REL_ "GenSigTimeoutTime" BU_SG_REL_ TSG_FS SG_ 388 FH_HFS_hoch 5000;
BA_REL_ "GenSigTimeoutTime" BU_SG_REL_ TSG_FS SG_ 388 FH_HFS_tief 5000;
BA_REL_ "GenSigTimeoutTime" BU_SG_REL_ TSG_BFS SG_ 388 FH_HBFS_hoch 5000;
BA_REL_ "GenSigTimeoutTime" BU_SG_REL_ TSG_BFS SG_ 388 FH_HBFS_tief 5000;
BA_REL_ "GenSigTimeoutTime" BU_SG_REL_ TSG_FS SG_ 388 BCM_Spg_Synchron 5000;
BA_REL_ "GenSigTimeoutTime" BU_SG_REL_ TSG_BFS SG_ 388 BCM_BF_Spg_Absenkung 5000;
BA_REL_ "GenSigTimeoutTime" BU_SG_REL_ TSG_BFS SG_ 388 ZV_Signatur 5000;
BA_REL_ "GenSigTimeoutTime" BU_SG_REL_ TSG_FS SG_ 388 ZV_Signatur 5000;
BA_REL_ "GenSigTimeoutTime" BU_SG_REL_ MFG SG_ 1411 BCM_FH_Freigabe 2000;
BA_REL_ "GenSigTimeoutTime" BU_SG_REL_ SAD SG_ 1411 BCM_FH_Freigabe 2000;
BA_REL_ "GenSigTimeoutTime" BU_SG_REL_ SAD2 SG_ 1411 BCM_FH_Freigabe 2000;
BA_REL_ "GenSigTimeoutTime" BU_SG_REL_ TSG_BFS SG_ 1411 BCM_FH_Freigabe 2000;
BA_REL_ "GenSigTimeoutTime" BU_SG_REL_ TSG_FS SG_ 1411 BCM_FH_Freigabe 2000;
BA_REL_ "GenSigTimeoutTime" BU_SG_REL_ VSG SG_ 1411 BCM_FH_Freigabe 2000;
BA_REL_ "GenSigTimeoutTime" BU_SG_REL_ BCM1 SG_ 1411 BCM_Komfortfkt_Freigabe 2000;
BA_REL_ "GenSigTimeoutTime" BU_SG_REL_ SAD SG_ 1411 BCM_Komfortfkt_Freigabe 2000;
BA_REL_ "GenSigTimeoutTime" BU_SG_REL_ SAD2 SG_ 1411 BCM_Komfortfkt_Freigabe 2000;
BA_REL_ "GenSigTimeoutTime" BU_SG_REL_ TSG_BFS SG_ 1411 BCM_Komfortfkt_Freigabe 2000;
BA_REL_ "GenSigTimeoutTime" BU_SG_REL_ TSG_FS SG_ 1411 BCM_Komfortfkt_Freigabe 2000;
BA_REL_ "GenSigTimeoutTime" BU_SG_REL_ TSG_BFS SG_ 1411 BCM_Verdeck_Freigabe 2000;
BA_REL_ "GenSigTimeoutTime" BU_SG_REL_ TSG_FS SG_ 1411 BCM_Verdeck_Freigabe 2000;
BA_REL_ "GenSigTimeoutTime" BU_SG_REL_ VSG SG_ 1411 BCM_Verdeck_Freigabe 2000;
BA_REL_ "GenSigTimeoutTime" BU_SG_REL_ MFG SG_ 1411 ZV_verriegelt_intern_ist 2000;
BA_REL_ "GenSigTimeoutTime" BU_SG_REL_ TSG_BFS SG_ 1411 ZV_verriegelt_intern_ist 2000;
BA_REL_ "GenSigTimeoutTime" BU_SG_REL_ TSG_FS SG_ 1411 ZV_verriegelt_intern_ist 2000;
BA_REL_ "GenSigTimeoutTime" BU_SG_REL_ VTS SG_ 1411 ZV_verriegelt_intern_ist 2000;
BA_REL_ "GenSigTimeoutTime" BU_SG_REL_ AAG SG_ 1411 ZV_verriegelt_extern_ist 2000;
BA_REL_ "GenSigTimeoutTime" BU_SG_REL_ BCM1 SG_ 1411 ZV_verriegelt_extern_ist 2000;
BA_REL_ "GenSigTimeoutTime" BU_SG_REL_ HDSG SG_ 1411 ZV_verriegelt_extern_ist 2000;
BA_REL_ "GenSigTimeoutTime" BU_SG_REL_ MFG SG_ 1411 ZV_verriegelt_extern_ist 2000;
BA_REL_ "GenSigTimeoutTime" BU_SG_REL_ SitzMem_FS SG_ 1411 ZV_verriegelt_extern_ist 2000;
BA_REL_ "GenSigTimeoutTime" BU_SG_REL_ SitzMem_SR3 SG_ 1411 ZV_verriegelt_extern_ist 2000;
BA_REL_ "GenSigTimeoutTime" BU_SG_REL_ TSG_BFS SG_ 1411 ZV_verriegelt_extern_ist 2000;
BA_REL_ "GenSigTimeoutTime" BU_SG_REL_ TSG_FS SG_ 1411 ZV_verriegelt_extern_ist 2000;
BA_REL_ "GenSigTimeoutTime" BU_SG_REL_ VSG SG_ 1411 ZV_verriegelt_extern_ist 2000;
BA_REL_ "GenSigTimeoutTime" BU_SG_REL_ VTS SG_ 1411 ZV_verriegelt_extern_ist 2000;
BA_REL_ "GenSigTimeoutTime" BU_SG_REL_ MFG SG_ 1411 ZV_verriegelt_intern_soll 2000;
BA_REL_ "GenSigTimeoutTime" BU_SG_REL_ TSG_BFS SG_ 1411 ZV_verriegelt_intern_soll 2000;
BA_REL_ "GenSigTimeoutTime" BU_SG_REL_ TSG_FS SG_ 1411 ZV_verriegelt_intern_soll 2000;
BA_REL_ "GenSigTimeoutTime" BU_SG_REL_ AAG SG_ 1411 ZV_verriegelt_extern_soll 2000;
BA_REL_ "GenSigTimeoutTime" BU_SG_REL_ BCM1 SG_ 1411 ZV_verriegelt_extern_soll 2000;
BA_REL_ "GenSigTimeoutTime" BU_SG_REL_ ELV SG_ 1411 ZV_verriegelt_extern_soll 2000;
BA_REL_ "GenSigTimeoutTime" BU_SG_REL_ MFG SG_ 1411 ZV_verriegelt_extern_soll 2000;
BA_REL_ "GenSigTimeoutTime" BU_SG_REL_ SitzMem_BFS SG_ 1411 ZV_verriegelt_extern_soll 2000;
BA_REL_ "GenSigTimeoutTime" BU_SG_REL_ SitzMem_FS SG_ 1411 ZV_verriegelt_extern_soll 2000;
BA_REL_ "GenSigTimeoutTime" BU_SG_REL_ SitzMem_SR3 SG_ 1411 ZV_verriegelt_extern_soll 2000;
BA_REL_ "GenSigTimeoutTime" BU_SG_REL_ TSG_BFS SG_ 1411 ZV_verriegelt_extern_soll 2000;
BA_REL_ "GenSigTimeoutTime" BU_SG_REL_ TSG_FS SG_ 1411 ZV_verriegelt_extern_soll 2000;
BA_REL_ "GenSigTimeoutTime" BU_SG_REL_ VSG SG_ 1411 ZV_verriegelt_extern_soll 2000;
BA_REL_ "GenSigTimeoutTime" BU_SG_REL_ BCM1 SG_ 1411 ZV_gesafet_extern_ist 2000;
BA_REL_ "GenSigTimeoutTime" BU_SG_REL_ MFG SG_ 1411 ZV_gesafet_extern_ist 2000;
BA_REL_ "GenSigTimeoutTime" BU_SG_REL_ TSG_BFS SG_ 1411 ZV_gesafet_extern_ist 2000;
BA_REL_ "GenSigTimeoutTime" BU_SG_REL_ TSG_FS SG_ 1411 ZV_gesafet_extern_ist 2000;
BA_REL_ "GenSigTimeoutTime" BU_SG_REL_ BCM1 SG_ 1411 ZV_gesafet_extern_soll 2000;
BA_REL_ "GenSigTimeoutTime" BU_SG_REL_ ELV SG_ 1411 ZV_gesafet_extern_soll 2000;
BA_REL_ "GenSigTimeoutTime" BU_SG_REL_ MFG SG_ 1411 ZV_gesafet_extern_soll 2000;
BA_REL_ "GenSigTimeoutTime" BU_SG_REL_ TSG_BFS SG_ 1411 ZV_gesafet_extern_soll 2000;
BA_REL_ "GenSigTimeoutTime" BU_SG_REL_ TSG_FS SG_ 1411 ZV_gesafet_extern_soll 2000;
BA_REL_ "GenSigTimeoutTime" BU_SG_REL_ BCM1 SG_ 1411 ZV_FT_offen 2000;
BA_REL_ "GenSigTimeoutTime" BU_SG_REL_ Gateway SG_ 1411 ZV_FT_offen 2000;
BA_REL_ "GenSigTimeoutTime" BU_SG_REL_ MSBBR SG_ 1411 ZV_FT_offen 2000;
BA_REL_ "GenSigTimeoutTime" BU_SG_REL_ BCM1 SG_ 1411 ZV_BT_offen 2000;
BA_REL_ "GenSigTimeoutTime" BU_SG_REL_ Gateway SG_ 1411 ZV_BT_offen 2000;
BA_REL_ "GenSigTimeoutTime" BU_SG_REL_ MSBBR SG_ 1411 ZV_BT_offen 2000;
BA_REL_ "GenSigTimeoutTime" BU_SG_REL_ BCM1 SG_ 1411 ZV_HFS_offen 2000;
BA_REL_ "GenSigTimeoutTime" BU_SG_REL_ Gateway SG_ 1411 ZV_HFS_offen 2000;
BA_REL_ "GenSigTimeoutTime" BU_SG_REL_ MSBBR SG_ 1411 ZV_HFS_offen 2000;
BA_REL_ "GenSigTimeoutTime" BU_SG_REL_ TSG_BFS SG_ 1411 ZV_HFS_offen 2000;
BA_REL_ "GenSigTimeoutTime" BU_SG_REL_ TSG_FS SG_ 1411 ZV_HFS_offen 2000;
BA_REL_ "GenSigTimeoutTime" BU_SG_REL_ BCM1 SG_ 1411 ZV_HBFS_offen 2000;
BA_REL_ "GenSigTimeoutTime" BU_SG_REL_ Gateway SG_ 1411 ZV_HBFS_offen 2000;
BA_REL_ "GenSigTimeoutTime" BU_SG_REL_ MSBBR SG_ 1411 ZV_HBFS_offen 2000;
BA_REL_ "GenSigTimeoutTime" BU_SG_REL_ TSG_BFS SG_ 1411 ZV_HBFS_offen 2000;
BA_REL_ "GenSigTimeoutTime" BU_SG_REL_ TSG_FS SG_ 1411 ZV_HBFS_offen 2000;
BA_REL_ "GenSigTimeoutTime" BU_SG_REL_ AAG SG_ 1411 ZV_HD_offen 2000;
BA_REL_ "GenSigTimeoutTime" BU_SG_REL_ BCM1 SG_ 1411 ZV_HD_offen 2000;
BA_REL_ "GenSigTimeoutTime" BU_SG_REL_ Gateway SG_ 1411 ZV_HD_offen 2000;
BA_REL_ "GenSigTimeoutTime" BU_SG_REL_ HDSG SG_ 1411 ZV_HD_offen 2000;
BA_REL_ "GenSigTimeoutTime" BU_SG_REL_ MFG SG_ 1411 ZV_HD_offen 2000;
BA_REL_ "GenSigTimeoutTime" BU_SG_REL_ MSBBR SG_ 1411 ZV_HD_offen 2000;
BA_REL_ "GenSigTimeoutTime" BU_SG_REL_ SitzMem_SR3 SG_ 1411 ZV_HD_offen 2000;
BA_REL_ "GenSigTimeoutTime" BU_SG_REL_ SpoilerSG SG_ 1411 ZV_HD_offen 2000;
BA_REL_ "GenSigTimeoutTime" BU_SG_REL_ VSG SG_ 1411 ZV_HD_offen 2000;
BA_REL_ "GenSigTimeoutTime" BU_SG_REL_ VTS SG_ 1411 ZV_HD_offen 2000;
BA_REL_ "GenSigTimeoutTime" BU_SG_REL_ AAG SG_ 1411 ZV_HS_offen 2000;
BA_REL_ "GenSigTimeoutTime" BU_SG_REL_ BCM1 SG_ 1411 ZV_HS_offen 2000;
BA_REL_ "GenSigTimeoutTime" BU_SG_REL_ MSBBR SG_ 1411 ZV_HS_offen 2000;
BA_REL_ "GenSigTimeoutTime" BU_SG_REL_ SitzMem_SR3 SG_ 1411 ZV_HS_offen 2000;
BA_REL_ "GenSigTimeoutTime" BU_SG_REL_ BCM1 SG_ 1411 DWA_aktiv 2000;
BA_REL_ "GenSigTimeoutTime" BU_SG_REL_ MFG SG_ 1411 DWA_aktiv 2000;
BA_REL_ "GenSigTimeoutTime" BU_SG_REL_ Gateway SG_ 1411 HD_Hauptraste 2000;
BA_REL_ "GenSigTimeoutTime" BU_SG_REL_ HDSG SG_ 1411 HD_Hauptraste 2000;
BA_REL_ "GenSigTimeoutTime" BU_SG_REL_ VSG SG_ 1411 HD_Hauptraste 2000;
BA_REL_ "GenSigTimeoutTime" BU_SG_REL_ HDSG SG_ 1411 HD_Vorraste 2000;
BA_REL_ "GenSigTimeoutTime" BU_SG_REL_ Gateway SG_ 1411 ZV_Schluessel_Zugang 2000;
BA_REL_ "GenSigTimeoutTime" BU_SG_REL_ BCM1 SG_ 1411 ZV_ist_Zustand_verfuegbar 2000;
BA_REL_ "GenSigTimeoutTime" BU_SG_REL_ MFG SG_ 1411 ZV_ist_Zustand_verfuegbar 2000;
BA_REL_ "GenSigTimeoutTime" BU_SG_REL_ SitzMem_BFS SG_ 1411 ZV_ist_Zustand_verfuegbar 2000;
BA_REL_ "GenSigTimeoutTime" BU_SG_REL_ SitzMem_FS SG_ 1411 ZV_ist_Zustand_verfuegbar 2000;
BA_REL_ "GenSigTimeoutTime" BU_SG_REL_ TSG_FS SG_ 1411 IRUE_Taster_Fkts_LED 2000;
BA_REL_ "GenSigTimeoutTime" BU_SG_REL_ SAD SG_ 1411 ZV_Rollo_auf 2000;
BA_REL_ "GenSigTimeoutTime" BU_SG_REL_ SAD2 SG_ 1411 ZV_Rollo_auf 2000;
BA_REL_ "GenSigTimeoutTime" BU_SG_REL_ SAD SG_ 1411 ZV_Rollo_zu 2000;
BA_REL_ "GenSigTimeoutTime" BU_SG_REL_ SAD2 SG_ 1411 ZV_Rollo_zu 2000;
BA_REL_ "GenSigTimeoutTime" BU_SG_REL_ SAD SG_ 1411 ZV_SAD_auf 2000;
BA_REL_ "GenSigTimeoutTime" BU_SG_REL_ SAD2 SG_ 1411 ZV_SAD_auf 2000;
BA_REL_ "GenSigTimeoutTime" BU_SG_REL_ SAD SG_ 1411 ZV_SAD_zu 2000;
BA_REL_ "GenSigTimeoutTime" BU_SG_REL_ SAD2 SG_ 1411 ZV_SAD_zu 2000;
VAL_ 975 HBFS_Tuer_geoeffnet 0 "geschlossen" 1 "offen" ;
VAL_ 975 HBFS_verriegelt 0 "nicht_verriegelt" 1 "verriegelt" ;
VAL_ 975 HBFS_gesafet 0 "nicht_gesafet" 1 "gesafet" ;
VAL_ 975 HBFS_Heckrollotaster_betaetigt 0 "keine_Verfahranweisung_in_Richtung_Hoch" 1 "In_Richtung_Hoch_Verfahren" ;
VAL_ 975 HBFS_Tuerschloss_defekt 0 "Tuerschloss funktionsfähig" 1 "Tuerschloss defekt" ;
VAL_ 975 HBFS_Unlock_Taster 0 "nicht_betaetigt" 1 "betaetigt" ;
VAL_ 975 HBFS_Lock_Taster 0 "nicht_betaetigt" 1 "betaetigt" ;
VAL_ 975 HBFS_Sperrklinke 0 "Schloss_in_Vorraste_und_Hauptraste" 1 "Tuer_auf_oder_Tuer_Position_zwischen_Vor_und_Hauptraste" ;
VAL_ 975 HBFS_TAG_betaetigt 0 "nicht_betaetigt" 1 "betaetigt" ;
VAL_ 975 HBFS_TIG_betaetigt 0 "nicht_betaetigt" 1 "betaetigt" ;
VAL_ 975 HBFS_FH_S_HFS_AutoHoch 0 "keine_Bedienung" 1 "Automatiklauf_Angefordert" ;
VAL_ 975 HBFS_FH_S_HFS_AutoTief 0 "keine_Bedienung" 1 "Automatiklauf_Angefordert" ;
VAL_ 975 HBFS_FH_S_HFS_ManHoch 0 "keine_Bedienung" 1 "Manueller_Lauf_Angefordert" ;
VAL_ 975 HBFS_FH_S_HFS_ManTief 0 "keine_Bedienung" 1 "Manueller_Lauf_Angefordert" ;
VAL_ 975 HBFS_Tuer_Status 0 "Init" 1 "Tuer geschlossen" 2 "Tuer offen" 3 "Fehler" ;
VAL_ 975 HBFS_SAD_Schalter 0 "nicht_betaetigt" 5 "AUF_manuell" 6 "AUF_automatik" 7 "ZU_manuell" 8 "ZU_automatik" 13 "nicht_verfuegbar" 14 "Init" 15 "Fehler" ;
VAL_ 975 HBFS_FH_S_ManHoch 0 "nicht_betaetigt" 1 "betaetigt" ;
VAL_ 975 HBFS_FH_S_AutoHoch 0 "nicht_betaetigt" 1 "betaetigt" ;
VAL_ 975 HBFS_FH_S_ManTief 0 "nicht_betaetigt" 1 "betaetigt" ;
VAL_ 975 HBFS_FH_S_AutoTief 0 "nicht_betaetigt" 1 "betaetigt" ;
VAL_ 975 HBFS_FH_Bew_hoch 0 "inaktiv" 1 "aktiv" ;
VAL_ 975 HBFS_FH_Bew_tief 0 "inaktiv" 1 "aktiv" ;
VAL_ 975 HBFS_FH_Fang 0 "ausserhalb_Fangbereich" 1 "innerhalb_Fangbereich" ;
VAL_ 975 HBFS_FH_Block 0 "inaktiv" 1 "aktiv" ;
VAL_ 975 HBFS_FH_Thermo 0 "inaktiv" 1 "aktiv" ;
VAL_ 975 HBFS_UEKB_aktiviert 0 "inaktiv" 1 "aktiv" ;
VAL_ 975 HBFS_Tuerschloss_verrieg_nicht 0 "Türschloss kann verriegelt werden" 1 "Türschloss kann nicht verriegelt werden" ;
VAL_ 975 HBFS_FH_normiert 0 "inaktiv" 1 "aktiv" ;
VAL_ 975 ASW_Warnung_aktiv_HBFS 0 "nicht_angefordert" 1 "angefordert" ;
VAL_ 975 HBFS_Zuziehhilfe_aktiv 1 "Zuziehhilfe_aktiv" ;
VAL_ 975 HBFS_Seitenrollo_hoch 1 "Seitenrollo_in_Bewegung_hoch" ;
VAL_ 975 HBFS_Seitenrollo_tief 1 "Seitenrollo_in_Bewegung_tief" ;
VAL_ 975 HBFS_Status_KiSi 0 "inaktiv" 1 "aktiv" ;
VAL_ 975 SSR_HBFS_Pos_Unten 0 "SSR_Oben" 1 "SSR_Unten" ;
VAL_ 975 HBFS_Oben_Block_erw 0 "Fensterheber_nicht_in_Blockerwartung_oben" 1 "Fensterheber in Blockerwartung oben" ;
VAL_ 975 HBFS_Unten_Block_erw 0 "Fensterheber_nicht_in_Blockerwartung_unten" 1 "Fensterheber in Blockerwartung unten" ;
VAL_ 975 MTHBFS_M_Taste 0 "nicht_betaetigt" 1 "betaetigt" ;
VAL_ 975 MTHBFS_Pos1 0 "nicht_betaetigt" 1 "betaetigt" ;
VAL_ 975 MTHBFS_Pos2 0 "nicht_betaetigt" 1 "betaetigt" ;
VAL_ 975 MTHBFS_Pos3 0 "nicht_betaetigt" 1 "betaetigt" ;
VAL_ 975 HBFS_MRollo_Schalter 0 "nicht_betaetigt" 1 "ZU_manuell" 2 "ZU_automatik" 3 "AUF_manuell" 4 "AUF_automatik" 5 "nicht_verfuegbar" 6 "Init" 7 "Fehler" ;
VAL_ 975 HBFS_Lock_Taster_inv 0 "Lock Taster betätgit" 1 "Lock Taster nicht betätigt" ;
VAL_ 975 HBFS_Status_KiSi_inv 0 "aktiv" 1 "inaktiv" ;
VAL_ 1457 TSG_FlHz_HBFS_NTC_A 125 "Fehler_NTC_OpenLoad__KS_Plus" 126 "Fehler_NTC_Overload__KS_Minus" 127 "Init" ;
VAL_ 1457 TSG_FlHz_HBFS_FnAbbruchHzKreis_A 0 "OK" 1 "FunktionsAbbruch" ;
VAL_ 1457 TSG_FlHz_HBFS_NTC_B 125 "Fehler_NTC_OpenLoad__KS_Plus" 126 "Fehler_NTC_Overload__KS_Minus" 127 "Init" ;
VAL_ 1457 TSG_FlHz_HBFS_FnAbbruchHzKreis_B 0 "OK" 1 "FunktionsAbbruch" ;
VAL_ 974 HFS_Tuer_geoeffnet 0 "geschlossen" 1 "offen" ;
VAL_ 974 HFS_verriegelt 0 "nicht_verriegelt" 1 "verriegelt" ;
VAL_ 974 HFS_gesafet 0 "nicht_gesafet" 1 "gesafet" ;
VAL_ 974 HFS_Heckrollotaster_betaetigt 0 "keine_Verfahranweisung_in_Richtung_Hoch" 1 "In_Richtung_Hoch_Verfahren" ;
VAL_ 974 HFS_Tuerschloss_defekt 0 "Tuerschloss funktionsfähig" 1 "Tuerschloss defekt" ;
VAL_ 974 HFS_Unlock_Taster 0 "nicht_betaetigt" 1 "betaetigt" ;
VAL_ 974 HFS_Lock_Taster 0 "nicht_betaetigt" 1 "betaetigt" ;
VAL_ 974 HFS_Sperrklinke 0 "Schloss_in_Vorraste_und_Hauptraste" 1 "Tuer_auf_oder_Tuer_Position_zwischen_Vor_und_Hauptraste" ;
VAL_ 974 HFS_TAG_betaetigt 0 "nicht_betaetigt" 1 "betaetigt" ;
VAL_ 974 HFS_TIG_betaetigt 0 "nicht_betaetigt" 1 "betaetigt" ;
VAL_ 974 HFS_FH_S_HBFS_AutoHoch 0 "keine_Bedienung" 1 "Automatiklauf_Angefordert" ;
VAL_ 974 HFS_FH_S_HBFS_AutoTief 0 "keine_Bedienung" 1 "Automatiklauf_Angefordert" ;
VAL_ 974 HFS_FH_S_HBFS_ManHoch 0 "keine_Bedienung" 1 "Manueller_Lauf_Angefordert" ;
VAL_ 974 HFS_FH_S_HBFS_ManTief 0 "keine_Bedienung" 1 "Manueller_Lauf_Angefordert" ;
VAL_ 974 HFS_Tuer_Status 0 "Init" 1 "Tuer geschlossen" 2 "Tuer offen" 3 "Fehler" ;
VAL_ 974 HFS_SAD_Schalter 0 "nicht_betaetigt" 5 "AUF_manuell" 6 "AUF_automatik" 7 "ZU_manuell" 8 "ZU_automatik" 13 "nicht_verfuegbar" 14 "Init" 15 "Fehler" ;
VAL_ 974 HFS_FH_S_ManHoch 0 "nicht_betaetigt" 1 "betaetigt" ;
VAL_ 974 HFS_FH_S_AutoHoch 0 "nicht_betaetigt" 1 "betaetigt" ;
VAL_ 974 HFS_FH_S_ManTief 0 "nicht_betaetigt" 1 "betaetigt" ;
VAL_ 974 HFS_FH_S_AutoTief 0 "nicht_betaetigt" 1 "betaetigt" ;
VAL_ 974 HFS_FH_Bew_hoch 0 "inaktiv" 1 "aktiv" ;
VAL_ 974 HFS_FH_Bew_tief 0 "inaktiv" 1 "aktiv" ;
VAL_ 974 HFS_FH_Fang 0 "ausserhalb_Fangbereich" 1 "innerhalb_Fangbereich" ;
VAL_ 974 HFS_FH_Block 0 "inaktiv" 1 "aktiv" ;
VAL_ 974 HFS_FH_Thermo 0 "inaktiv" 1 "aktiv" ;
VAL_ 974 HFS_UEKB_aktiviert 0 "inaktiv" 1 "aktiv" ;
VAL_ 974 HFS_Tuerschloss_verrieg_nicht 0 "Tür kann verriegelt werden" 1 "Tür kann nicht verriegelt werden" ;
VAL_ 974 HFS_FH_normiert 0 "inaktiv" 1 "aktiv" ;
VAL_ 974 ASW_Warnung_aktiv_HFS 0 "nicht_angefordert" 1 "angefordert" ;
VAL_ 974 HFS_Zuziehhilfe_aktiv 1 "Zuziehhilfe_aktiv" ;
VAL_ 974 HFS_Seitenrollo_hoch 1 "Seitenrollo_in_Bewegung_hoch" ;
VAL_ 974 HFS_Seitenrollo_tief 1 "Seitenrollo_in_Bewegung_tief" ;
VAL_ 974 HFS_Status_KiSi 0 "inaktiv" 1 "aktiv" ;
VAL_ 974 SSR_HFS_Pos_Unten 0 "SSR_Oben" 1 "SSR_Unten" ;
VAL_ 974 HFS_Oben_Block_erw 0 "Fensterheber_nicht_in_Blockerwartung_oben" 1 "Fensterheber in Blockerwartung oben" ;
VAL_ 974 HFS_Unten_Block_erw 0 "Fensterheber_nicht_in_Blockerwartung_unten" 1 "Fensterheber in Blockerwartung unten" ;
VAL_ 974 MTHFS_M_Taste 0 "nicht_betaetigt" 1 "betaetigt" ;
VAL_ 974 MTHFS_Pos1 0 "nicht_betaetigt" 1 "betaetigt" ;
VAL_ 974 MTHFS_Pos2 0 "nicht_betaetigt" 1 "betaetigt" ;
VAL_ 974 MTHFS_Pos3 0 "nicht_betaetigt" 1 "betaetigt" ;
VAL_ 974 HFS_MRollo_Schalter 0 "nicht_betaetigt" 1 "ZU_manuell" 2 "ZU_automatik" 3 "AUF_manuell" 4 "AUF_automatik" 5 "nicht_verfuegbar" 6 "Init" 7 "Fehler" ;
VAL_ 974 HFS_Lock_Taster_inv 0 "Lock Taster betätgit" 1 "Lock Taster nicht betätigt" ;
VAL_ 1458 TSG_FlHz_HFS_NTC_A 125 "Fehler_NTC_OpenLoad__KS_Plus" 126 "Fehler_NTC_Overload__KS_Minus" 127 "Init" ;
VAL_ 1458 TSG_FlHz_HFS_FnAbbruchHzKreis_A 0 "OK" 1 "FunktionsAbbruch" ;
VAL_ 1458 TSG_FlHz_HFS_NTC_B 125 "Fehler_NTC_OpenLoad__KS_Plus" 126 "Fehler_NTC_Overload__KS_Minus" 127 "Init" ;
VAL_ 1458 TSG_FlHz_HFS_FnAbbruchHzKreis_B 0 "OK" 1 "FunktionsAbbruch" ;
VAL_ 346 MO_Anforderung_HMS 0 "keine_Anforderung" 1 "halten" 2 "parken" 3 "halten_Standby" 4 "anfahren" 5 "Loesen_ueber_Rampe" ;
VAL_ 346 TSK_vMax_Fahrerassistenz 511 "Init_ungueltig_keine_Beschraenkung" ;
VAL_ 346 TSK_Einheit_vMax_Fahrerassistenz 0 "kmh" 1 "mph" ;
VAL_ 346 TSK_Status_PLA 0 "Aus_Funktionsbereit" 1 "Init_oder_nicht_verbaut" 2 "aktivierbar" 3 "aktiv" 5 "Abschaltung_laeuft" 6 "reversibel_aus" 7 "Fehler" ;
VAL_ 346 TSK_aktives_System 0 "keine_Funktion_aktiv" 1 "GRA_ACC" 2 "ARA" 3 "Speedlimiter" 4 "IPA" 5 "PLA" ;
VAL_ 346 TSK_erhoehter_Fahrwiderstand 0 "kein_erhoehter_Fahrwiderstand" 1 "erhoehter_Fahrwiderstand" ;
VAL_ 346 TSK_Status_ARA 0 "Aus" 1 "Init_oder_nicht_verbaut" 2 "aktivierbar" 3 "aktiv" 5 "abschaltung_laeuft" 6 "reversibel_aus" 7 "Fehler" ;
VAL_ 346 TSK_Status_IPA 0 "Aus_Funktionsbereit" 1 "Init_oder_nicht_verbaut" 2 "aktivierbar" 3 "aktiv" 5 "Abschaltung_laueft" 6 "reversibel_aus" 7 "Fehler" ;
VAL_ 995 VS_VD_zu_ver 1 "Zustand des Verdecks verriegelt und geschlossen" ;
VAL_ 995 VS_VD_entriegelt 1 "Zustand des Verdeck entriegelt" ;
VAL_ 995 VS_VD_offen_ver 0 "Init" 1 "Zustand des Verdecks verriegelt und offen " ;
VAL_ 995 VS_VD_Zwischenposition 1 "Verdeck in Zwischenposition " ;
VAL_ 995 VS_VD_Bew_auf 1 "Verdeck in Bewegung auf" ;
VAL_ 995 VS_VD_Bew_zu 1 "Verdeck in Bewegung zu " ;
VAL_ 995 VS_Hardtop 1 "Hardtop montiert" ;
VAL_ 995 VS_VD_Fehler 1 "Fehlerzustand Verdeck " ;
VAL_ 995 VS_Lampe_Blk 0 "Kontrollleuchte_inaktiv" 1 "Kontrollleuchte_aktiv" ;
VAL_ 995 VS_HD_sperren 0 "HD Entriegelung freigegeben" 1 "HD Entriegelung gesperrt" ;
VAL_ 995 VS_HHS_enable 1 "Freigabe HHS " ;
VAL_ 995 ZFH_FS_AutoHoch 0 "Keine_Verfahranforderung" 1 "Automatischer_Hochlauf" ;
VAL_ 995 ZFH_FS_AutoTief 0 "Keine_Verfahranforderung" 1 "Automatischer_Tieflauf" ;
VAL_ 995 ZFH_FS_ManHoch 0 "Keine_Verfahranforderung" 1 "Manueller_Hochlauf" ;
VAL_ 995 ZFH_FS_ManTief 0 "Keine_Verfahranforderung" 1 "Manueller_Tieflauf" ;
VAL_ 995 ZFH_BFS_AutoHoch 0 "Keine_Verfahranforderung" 1 "Automatischer_Hochlauf" ;
VAL_ 995 ZFH_BFS_AutoTief 0 "Keine_Verfahranforderung" 1 "Automatischer_Tieflauf" ;
VAL_ 995 ZFH_BFS_ManHoch 0 "Keine_Verfahranforderung" 1 "Manueller_Hochlauf" ;
VAL_ 995 ZFH_BFS_ManTief 0 "Keine_Verfahranforderung" 1 "Manueller_Tieflauf" ;
VAL_ 995 ZFH_HFS_AutoHoch 0 "Keine_Verfahranforderung" 1 "Automatischer_Hochlauf" ;
VAL_ 995 ZFH_HFS_AutoTief 0 "Keine_Verfahranforderung" 1 "Automatischer_Tieflauf" ;
VAL_ 995 ZFH_HFS_ManHoch 0 "Keine_Verfahranforderung" 1 "Manueller_Hochlauf" ;
VAL_ 995 ZFH_HFS_ManTief 0 "Keine_Verfahranforderung" 1 "Manueller_Tieflauf" ;
VAL_ 995 ZFH_HBFS_AutoHoch 0 "Keine_Verfahranforderung" 1 "Automatischer_Hochlauf" ;
VAL_ 995 ZFH_HBFS_AutoTief 0 "Keine_Verfahranforderung" 1 "Automatischer_Tieflauf" ;
VAL_ 995 ZFH_HBFS_ManHoch 0 "Keine_Verfahranforderung" 1 "Manueller_Hochlauf" ;
VAL_ 995 ZFH_HBFS_ManTief 0 "Keine_Verfahranforderung" 1 "Manueller_Tieflauf" ;
VAL_ 995 VS_Heckschloss_auf 0 "kein_Oeffnen" 1 "Heckschloss_oeffnen" ;
VAL_ 995 VSG_Meldungen 0 "keine_Meldung" ;
VAL_ 1361 WFS_Schluessel_Fahrberecht 0 "kein authorisierter Schluessel erkannt " 1 "aktive_Funkschluessel_Nr_01" 2 "aktive_Funkschluessel_Nr_02" 3 "aktive_Funkschluessel_Nr_03" 4 "aktive_Funkschluessel_Nr_04" 5 "aktive_Funkschluessel_Nr_05" 6 "aktive_Funkschluessel_Nr_06" 7 "aktive_Funkschluessel_Nr_07" 8 "aktive_Funkschluessel_Nr_08" 9 "ungueltig_09" 10 "ungueltig_10" 11 "ungueltig_11" 12 "ungueltig_12" 13 "ungueltig_13" 14 "ungueltig_14" 15 "ungueltig_15" ;
VAL_ 1361 WFS_ID_Geb_autorisiert 0 "Schluessel_nicht_authorisiert" 1 "Schluessel authorisiert" ;
VAL_ 1361 WFS_ID_Geb_autorisiert_in_Kl15 0 "nicht_authorisiert_in_Kl15" 1 "authorisiert_in_Kl15" ;
VAL_ 1361 WFS_ID_Geb_steckt 0 "kein_Schluessel_im_Zuendschloss" 1 " Schluessel steckt im Zuendschloss" ;
VAL_ 1361 WFS_Safe 1 "WFS nicht deaktiviert" ;
VAL_ 1361 WFS_LZ 0 "nicht def." 1 "LZ 1" 2 "LZ 2" 3 "LZ 3" ;
VAL_ 1361 WFS_ELV_authorisiert 0 "ELV_nicht_authorisiert" 1 "ELV_authorisiert" ;
VAL_ 1361 WFS_LF_Aktiv 0 "Funktempfang_nicht_aktiv" 1 "LF_Funkempfang_aktiv" ;
VAL_ 1361 WFS_Betrieb_Lesespule 0 "keine_Schluesselkomm_Lesespule" 1 "Schluesselkomm_Lesespule" ;
VAL_ 1361 WFS_Klemmenfreigabe 0 "keine_Freigabe" 1 "Freigabe" ;
VAL_ 1361 WFS_Fahrerhinweise 0 "Keine_Anzeigeanforderung" 1 "Schuessel_Auth_niO" 2 "Notlauf_aktiv" ;
VAL_ 1702 Wischer_vorne_aktiv 1 "Wischer vorne läuft" ;
VAL_ 1702 Waschen_vorne_aktiv 1 "Waschen aktiv" ;
VAL_ 1702 Wischer_vorne_Normal 1 "Wischer Front normal aktiv" ;
VAL_ 1702 Wischer_vorne_Schnell 1 "Wischer vorne schnell aktiv" ;
VAL_ 1702 Wischer_vorne_Parklage 0 "Wischer_Front_nicht_in_Parklage" 1 "Wischer_Front_in_Parklage__Initialzustand" ;
VAL_ 1702 Wischer_vorne_defekt 1 "Wischer vorne defekt" ;
VAL_ 1702 Wischer_vorne_blockiert 1 "Wischer vorne blockiert" ;
VAL_ 1702 Wischer1_Wischgeschwindigkeit 0 "0 U/min" 62 "Init" 63 "Fehler" ;
VAL_ 1702 BCM1_SRA_aktiv 0 "nicht aktiv" 1 "aktiv" ;
VAL_ 1702 Heckwischer_Anforderung 0 "Aus" 1 "Ein" ;
VAL_ 1702 WWSs_01_upd 0 "nicht_aktuell" 1 "aktuell" ;
VAL_ 2527679496 WIV_Verschleissindex_Ueberlauf 0 "kein_Ueberlauf" 1 "min_1_Zaehlerueberlauf" ;
VAL_ 2527679496 WIV_Russindex_Ueberlauf 0 "kein_Ueberlauf" 1 "min_1_Zaehlerueberlauf" ;
VAL_ 389 ZFH_FS_ManHoch 0 "Keine_Verfahranforderung" 1 "Manueller_Hochlauf" ;
VAL_ 389 ZFH_FS_AutoHoch 0 "Keine_Verfahranforderung" 1 "Automatischer_Hochlauf" ;
VAL_ 389 ZFH_FS_ManTief 0 "Keine_Verfahranforderung" 1 "Manueller_Tieflauf" ;
VAL_ 389 ZFH_FS_AutoTief 0 "Keine_Verfahranforderung" 1 "Automatischer_Tieflauf" ;
VAL_ 389 ZFH_BFS_ManHoch 0 "Keine_Verfahranforderung" 1 "Manueller_Hochlauf" ;
VAL_ 389 ZFH_BFS_AutoHoch 0 "Keine_Verfahranforderung" 1 "Automatischer_Hochlauf" ;
VAL_ 389 ZFH_BFS_ManTief 0 "Keine_Verfahranforderung" 1 "Manueller_Tieflauf" ;
VAL_ 389 ZFH_BFS_AutoTief 0 "Keine_Verfahranforderung" 1 "Automatischer_Tieflauf" ;
VAL_ 389 ZFH_HFS_ManHoch 0 "Keine_Verfahranforderung" 1 "Manueller_Hochlauf" ;
VAL_ 389 ZFH_HFS_AutoHoch 0 "Keine_Verfahranforderung" 1 "Automatischer_Hochlauf" ;
VAL_ 389 ZFH_HFS_ManTief 0 "Keine_Verfahranforderung" 1 "Manueller_Tieflauf" ;
VAL_ 389 ZFH_HFS_AutoTief 0 "Keine_Verfahranforderung" 1 "Automatischer_Tieflauf" ;
VAL_ 389 ZFH_HBFS_ManHoch 0 "Keine_Verfahranforderung" 1 "Manueller_Hochlauf" ;
VAL_ 389 ZFH_HBFS_AutoHoch 0 "Keine_Verfahranforderung" 1 "Automatischer_Hochlauf" ;
VAL_ 389 ZFH_HBFS_ManTief 0 "Keine_Verfahranforderung" 1 "Manueller_Tieflauf" ;
VAL_ 389 ZFH_HBFS_AutoTief 0 "Keine_Verfahranforderung" 1 "Automatischer_Tieflauf" ;
VAL_ 389 ZFH_zentral_zu 1 "Fensterheber_zentral_zu" ;
VAL_ 389 ZFH_zentral_auf 1 "Fensterheber_zentral_auf" ;
VAL_ 389 Krypt_Schluesselschalter_auf 0 "Schluesselschalter_nicht_betaetigt" 1 "Schluesselschalter_betaetigt" ;
VAL_ 389 Krypt_Schluesselschalter_zu 0 "Schluesselschalter_nicht_betaetigt" 1 "Schluesselschalter_betaetigt" ;
VAL_ 392 BT_FH_BT_ManHoch 0 "Keine_Verfahranforderung" 1 "Manueller_Hochlauf" ;
VAL_ 392 BT_FH_BT_AutoHoch 0 "Keine_Verfahranforderung" 1 "Automatischer_Hochlauf" ;
VAL_ 392 BT_FH_BT_ManTief 0 "Keine_Verfahranforderung" 1 "Manueller_Tieflauf" ;
VAL_ 392 BT_FH_BT_AutoTief 0 "Kein_Verfahranforderung" 1 "Automatischer_Tieflauf" ;
VAL_ 392 BT_FH_FT_ManHoch 0 "Keine_Verfahranforderung" 1 "Manueller_Hochlauf" ;
VAL_ 392 BT_FH_FT_AutoHoch 0 "Keine_Verfahranforderung" 1 "Automatischer_Hochlauf" ;
VAL_ 392 BT_FH_FT_ManTief 0 "Keine_Verfahranforderung" 1 "Manueller_Tieflauf" ;
VAL_ 392 BT_FH_FT_AutoTief 0 "Keine_Verfahranforderung" 1 "Automatischer_Tieflauf" ;
VAL_ 392 BT_FH_HFS_ManHoch 0 "Keine_Verfahranforderung" 1 "Manueller_Hochlauf" ;
VAL_ 392 BT_FH_HFS_AutoHoch 0 "Keine_Verfahranforderung" 1 "Automatischer_Hochlauf" ;
VAL_ 392 BT_FH_HFS_ManTief 0 "Keine_Verfahranforderung" 1 "Manueller_Tieflauf" ;
VAL_ 392 BT_FH_HFS_AutoTief 0 "Keine_Verfahranforderung" 1 "Automatischer_Tieflauf" ;
VAL_ 392 BT_FH_HBFS_ManHoch 0 "Keine_Verfahranforderung" 1 "Manueller_Hochlauf" ;
VAL_ 392 BT_FH_HBFS_AutoHoch 0 "Keine_Verfahranforderung" 1 "Automatischer_Hochlauf" ;
VAL_ 392 BT_FH_HBFS_ManTief 0 "Keine_Verfahranforderung" 1 "Manueller_Tieflauf" ;
VAL_ 392 BT_FH_HBFS_AutoTief 0 "Keine_Verfahranforderung" 1 "Automatischer_Tieflauf" ;
VAL_ 392 BT_SP_hoch 0 "nicht_betaetigt" 1 "betaetigt" ;
VAL_ 392 BT_SP_tief 0 "nicht_betaetigt" 1 "betaetigt" ;
VAL_ 392 BT_SP_links 0 "nicht_betaetigt" 1 "betaetigt" ;
VAL_ 392 BT_SP_rechts 0 "nicht_betaetigt" 1 "betaetigt" ;
VAL_ 392 BT_SP_Garagenstellung 1 "Spiegel_in_Garagenstellung" ;
VAL_ 392 BT_SP_Fahrstellung 1 "Spiegel_ist_ausgeklappt" ;
VAL_ 392 BT_FH_zentral_zu 1 "Fensterheber_zentral_zu" ;
VAL_ 392 BT_FH_zentral_auf 1 "Fensterheber_zentral_auf" ;
VAL_ 388 ZV_FT_verriegeln 0 "FT nicht verriegeln" 1 "FT verriegeln" ;
VAL_ 388 ZV_FT_entriegeln 0 "FT nicht entriegeln" 1 "FT entriegeln" ;
VAL_ 388 ZV_BT_verriegeln 0 "BT nicht verriegeln" 1 "BT verriegeln" ;
VAL_ 388 ZV_BT_entriegeln 0 "BT nicht entriegeln" 1 "BT ist zu entriegeln" ;
VAL_ 388 ZV_HFS_verriegeln 0 "inaktiv" 1 "aktiv" ;
VAL_ 388 ZV_HFS_entriegeln 0 "inaktiv" 1 "aktiv" ;
VAL_ 388 ZV_HBFS_verriegeln 0 "inaktiv" 1 "aktiv" ;
VAL_ 388 ZV_HBFS_entriegeln 0 "inaktiv" 1 "aktiv" ;
VAL_ 388 ZV_zentral_safen 0 "nicht safen" 1 "Befehl zentral safen" ;
VAL_ 388 ZV_zentral_entsafen 1 "Befehl zentral entsafen" ;
VAL_ 388 ZV_Spg_Anklappen 0 "inaktiv" 1 "aktiv" ;
VAL_ 388 ZV_Softtouch_betaetigt 0 "Softtouch_nicht_betaetigt" 1 "Softtouch betaetigt" ;
VAL_ 388 ZV_LED_Steuerung 0 "LED_aus" 1 "LED_ein" ;
VAL_ 388 ZV_LED_Uebernahme 1 "TSG uebernimmt LED Steuerung" ;
VAL_ 388 ZV_auf_FT 0 "nicht_betaetigt" 1 "betaetigt" ;
VAL_ 388 ZV_zu_FT 0 "nicht_betaetigt" 1 "betaetigt" ;
VAL_ 388 ZV_auf_BT 0 "nicht_betaetigt" 1 "betaetigt" ;
VAL_ 388 ZV_zu_BT 0 "nicht_betaetigt" 1 "betaetigt" ;
VAL_ 388 ZV_auf_Funk 0 "nicht_betaetigt" 1 "betaetigt" ;
VAL_ 388 ZV_zu_Funk 0 "nicht_betaetigt" 1 "betaetigt" ;
VAL_ 388 VIP_Sensor_betaetigt 0 "keine_Heckentriegelung_durch_VIP_Sensor_angefordert" 1 "Heckentriegelung_durch_VIP_Sensor_angefordert" ;
VAL_ 388 VIP_Freigabe 0 "keine_Freigabe" 1 "Freigabe" ;
VAL_ 388 ZV_zu_Zeitl_Nachverr 1 "Nachverriegeln" ;
VAL_ 388 ZV_HSK_entriegeln 0 "Handschuhkasten nicht entriegeln" 1 "Handschuhkasten entriegeln" ;
VAL_ 388 ZV_HSK_verriegeln 0 "Handschuhkasten nicht verriegeln" 1 "Handschuhkasten_verriegelt" ;
VAL_ 388 ZV_Verdeck_zu 0 "inaktiv" 1 "aktiv" ;
VAL_ 388 ZV_Verdeck_auf 0 "inaktiv" 1 "aktiv" ;
VAL_ 388 FH_FT_hoch 0 "keine_Anforderung" 1 "FT_hoch" ;
VAL_ 388 FH_FT_tief 0 "keine_Anforderung" 1 "FT_tief" ;
VAL_ 388 FH_BT_hoch 0 "keine_Anforderung" 1 "BT_hoch" ;
VAL_ 388 FH_BT_tief 0 "keine_Anforderung" 1 "BT_tief" ;
VAL_ 388 FH_HFS_hoch 0 "inaktiv" 1 "aktiv" ;
VAL_ 388 FH_HFS_tief 0 "inaktiv" 1 "aktiv" ;
VAL_ 388 FH_HBFS_hoch 0 "inaktiv" 1 "aktiv" ;
VAL_ 388 FH_HBFS_tief 0 "inaktiv" 1 "aktiv" ;
VAL_ 388 BCM_Spg_Synchron 0 "inaktiv" 1 "aktiv" ;
VAL_ 1411 BCM_FH_Freigabe 1 "Funktionsfreigabe Fensterheber" ;
VAL_ 1411 BCM_Komfortfkt_Freigabe 0 "Komfortfunktion gesperrt" 1 "globale Freigabe der Komfortfunktion erteilt" ;
VAL_ 1411 BCM_HSK_Freigabe 0 "erlauben" 1 "sperren" ;
VAL_ 1411 BCM_Verdeck_Freigabe 0 "Verdeckbetrieb nicht erlaubt" 1 "Verdeckbetrieb erlaubt" ;
VAL_ 1411 ZV_verriegelt_intern_ist 1 "Fahrzeug innen verriegelt; Istzustand" ;
VAL_ 1411 ZV_verriegelt_extern_ist 1 "Fahrzeug_aussen_verriegelt_Istzustand" ;
VAL_ 1411 ZV_verriegelt_intern_soll 1 "Fahrzeug verriegelt intern; Sollzusstand" ;
VAL_ 1411 ZV_verriegelt_extern_soll 1 "Fahrzeug verriegelt extern; Sollzusstand" ;
VAL_ 1411 ZV_gesafet_extern_ist 1 "Fahrzeug aussen gesafet; Istzustand" ;
VAL_ 1411 ZV_gesafet_extern_soll 1 "Fahrzeug_aussen_gesafet_Sollzustand" ;
VAL_ 1411 ZV_Einzeltuerentriegelung 1 "Fahrzeug an Einzeltuer entriegelt" ;
VAL_ 1411 ZV_Heckeinzelentriegelung 1 "Heckdeckeleinzelentriegelung" ;
VAL_ 1411 ZV_FT_offen 1 "FT_geoeffnet" ;
VAL_ 1411 ZV_BT_offen 1 "BT_geoeffnet" ;
VAL_ 1411 ZV_HFS_offen 0 "geschlossen" 1 "offen" ;
VAL_ 1411 ZV_HBFS_offen 0 "geschlossen" 1 "offen" ;
VAL_ 1411 ZV_HD_offen 1 "Heckdeckel_auf" ;
VAL_ 1411 ZV_HS_offen 0 "Heckscheibe_geschlossen" 1 "Heckscheibe auf" ;
VAL_ 1411 IRUE_aktiv 0 "unscharf" 1 "scharf" ;
VAL_ 1411 DWA_aktiv 0 "unscharf" 1 "scharf" ;
VAL_ 1411 HD_Hauptraste 0 "geschlossen" 1 "offen" ;
VAL_ 1411 HD_Vorraste 0 "geschlossen" 1 "offen" ;
VAL_ 1411 FFB_HDF_Taste 0 "Taste_nicht_betaetigt" 1 "HDF_Taste_am_Funkschluessel_betaetigt" ;
VAL_ 1411 FFB_Panik_Taste 0 "Taste_nicht_betaetigt" 1 "Panik_Taste_am_Funkschluessel_betaetigt" ;
VAL_ 1411 FFB_Auf_Taste 0 "Taste_nicht_betaetigt" 1 "Oeffnentaste_betaetigt" ;
VAL_ 1411 FFB_Zu_Taste 0 "Taste_nicht_betaetigt" 1 "Zu_Taste_am_Funkschluessel_betaetigt" ;
VAL_ 1411 FFB_CarFinder 0 "nicht aktiv" 1 "aktiv" ;
VAL_ 1411 FFB_Komfortoeffnen 0 "kein_Komfortoeffnen_empfangen" 1 "Komfortoeffnen ueber Funk empfangen" ;
VAL_ 1411 FFB_Komfortschliessen 0 "kein_Komfortschliessen_empfangen" 1 "Komfortschliessen ueber Funk empfangen" ;
VAL_ 1411 FBS_IDG_in_Reichweite 0 "ausser_Reichweite_bzw_nicht_ermittelbar" 1 "innerhalb_Reichweite" ;
VAL_ 1411 ZV_Schluessel_Zugang 0 "kein authorisierter Schluessel erkannt " 1 "aktive_Funkschluessel_Nr_01" 2 "aktive_Funkschluessel_Nr_02" 3 "aktive_Funkschluessel_Nr_03" 4 "aktive_Funkschluessel_Nr_04" 5 "aktive_Funkschluessel_Nr_05" 6 "aktive_Funkschluessel_Nr_06" 7 "aktive_Funkschluessel_Nr_07" 8 "aktive_Funkschluessel_Nr_08" 9 "ungueltig_09" 10 "ungueltig_10" 11 "ungueltig_11" 12 "ungueltig_12" 13 "ungueltig_13" 14 "ungueltig_14" 15 "ungueltig_15" ;
VAL_ 1411 ZV_SafeFunktion_aktiv 0 "inaktiv" 1 "aktiv" ;
VAL_ 1411 FBS_Warn_Schluessel_Batt 0 "i.O." 1 "defekt" ;
VAL_ 1411 ZV_Oeffnungsmodus 0 "globale_Oeffnung" 1 "ZV_mit_Einzeltuerentr" 2 "ZV_individuell_selektiv" 3 "ZV_seitenselektiv" ;
VAL_ 1411 HFS_verriegelt 0 "nicht_verriegelt" 1 "verriegelt" ;
VAL_ 1411 HFS_gesafet 0 "nicht_gesafet" 1 "gesafet" ;
VAL_ 1411 HBFS_verriegelt 0 "nicht_verriegelt" 1 "verriegelt" ;
VAL_ 1411 HBFS_gesafet 0 "nicht_gesafet" 1 "gesafet" ;
VAL_ 1411 ZV_ist_Zustand_verfuegbar 0 "nicht_verfuegbar" 1 "verfuegbar_alle_TSGs_am_Bus" ;
VAL_ 1411 IRUE_Taster_Fkts_LED 0 "LED_aus" 1 "LED_ein" ;
VAL_ 1411 ZV_Tankklappe_offen 0 "Tankklappe_geschlossen" 1 "Tankklappe_offen" ;
VAL_ 1411 ZV_Rollo_auf 0 "inaktiv" 1 "aktiv" ;
VAL_ 1411 ZV_Rollo_zu 0 "inaktiv" 1 "aktiv" ;
VAL_ 1411 ZV_SAD_auf 0 "inaktiv" 1 "aktiv" ;
VAL_ 1411 ZV_SAD_zu 0 "inaktiv" 1 "aktiv" ;
VAL_ 1411 BCM_Tankklappensteller_Fehler 0 "kein_Fehler" 1 "Fehler" ;
